VERSION ""

NS_ :

BS_:

BU_: VCU_LE CHUD_LE VKM_LE RCRM_LE VPM_LE EDI_LE V2V_LE TCP_LE CSM_LE UHP_Low_LE TouchPad_LE RSE_LE RSC_LE RSA_LE PDIM_LE OTIM_LE ICS_LE LVMPC_LE LVMNav_LE DVB_T_LE ONSTAR_LE HUD_LE IPC_LE RadioHead_LE CHM_LE Dummy_LE CGM_LE AMP_LE

BO_ 2155102208 Driver_Seat_Massage_Priority_LE: 8 CGM_LE
 SG_ DSMP_UnsdRsrvd : 56|1@0+ (1,0) [0|1] ""  VCU_LE,CSM_LE,RadioHead_LE
 SG_ DSMP_MaxDispVal : 59|3@0+ (1,0) [0|7] ""  VCU_LE,CSM_LE,RadioHead_LE
 SG_ DSMP_Type15 : 63|4@0+ (1,0) [0|15] ""  VCU_LE,CSM_LE,RadioHead_LE
 SG_ DSMP_Type14 : 51|4@0+ (1,0) [0|15] ""  VCU_LE,CSM_LE,RadioHead_LE
 SG_ DSMP_Type13 : 55|4@0+ (1,0) [0|15] ""  VCU_LE,CSM_LE,RadioHead_LE
 SG_ DSMP_Type12 : 43|4@0+ (1,0) [0|15] ""  VCU_LE,CSM_LE,RadioHead_LE
 SG_ DSMP_Type11 : 47|4@0+ (1,0) [0|15] ""  VCU_LE,CSM_LE,RadioHead_LE
 SG_ DSMP_Type10 : 35|4@0+ (1,0) [0|15] ""  VCU_LE,CSM_LE,RadioHead_LE
 SG_ DSMP_Type9 : 39|4@0+ (1,0) [0|15] ""  VCU_LE,CSM_LE,RadioHead_LE
 SG_ DSMP_Type8 : 27|4@0+ (1,0) [0|15] ""  VCU_LE,CSM_LE,RadioHead_LE
 SG_ DSMP_Type7 : 31|4@0+ (1,0) [0|15] ""  VCU_LE,CSM_LE,RadioHead_LE
 SG_ DSMP_Type6 : 19|4@0+ (1,0) [0|15] ""  VCU_LE,CSM_LE,RadioHead_LE
 SG_ DSMP_Type5 : 23|4@0+ (1,0) [0|15] ""  VCU_LE,CSM_LE,RadioHead_LE
 SG_ DSMP_Type4 : 11|4@0+ (1,0) [0|15] ""  VCU_LE,CSM_LE,RadioHead_LE
 SG_ DSMP_Type3 : 15|4@0+ (1,0) [0|15] ""  VCU_LE,CSM_LE,RadioHead_LE
 SG_ DSMP_Type2 : 3|4@0+ (1,0) [0|15] ""  VCU_LE,CSM_LE,RadioHead_LE
 SG_ DSMP_Type1 : 7|4@0+ (1,0) [0|15] ""  VCU_LE,CSM_LE,RadioHead_LE

BO_ 2155085824 Driver_Seat_Control_Disp_Stat_LE: 8 CGM_LE
 SG_ StrgColUpDwnPos : 63|8@0+ (1,0) [0|255] ""  Dummy_LE
 SG_ CPMAPINFO4 : 5|1@0+ (1,0) [0|1] ""  Dummy_LE
 SG_ StrgColInOutPos : 55|8@0+ (1,0) [0|255] ""  Dummy_LE
 SG_ StrgColCommsFlt : 7|2@0+ (1,0) [0|3] ""  Dummy_LE
 SG_ DSCDS_UnsdRsrvd : 42|3@0+ (1,0) [0|7] ""  VCU_LE,CSM_LE,RadioHead_LE
 SG_ DSCDS_DispReq : 43|1@0+ (1,0) [0|1] ""  VCU_LE,CSM_LE,RadioHead_LE
 SG_ DSCDS_DispSz : 45|2@0+ (1,0) [0|3] ""  VCU_LE,CSM_LE,RadioHead_LE
 SG_ DSCDS_CshLgAdjFdRr : 47|2@0+ (1,0) [0|3] ""  VCU_LE,CSM_LE,RadioHead_LE
 SG_ DSCDS_BkCshBlstInOt : 34|3@0+ (1,0) [0|7] ""  VCU_LE,CSM_LE,RadioHead_LE
 SG_ DSCDS_CshBlstrInOut : 36|2@0+ (1,0) [0|3] ""  VCU_LE,CSM_LE,RadioHead_LE
 SG_ DSCDS_BkBlstrInOut : 38|2@0+ (1,0) [0|3] ""  VCU_LE,CSM_LE,RadioHead_LE
 SG_ DSCDS_LmbrUDnFdRr : 25|3@0+ (1,0) [0|7] ""  VCU_LE,CSM_LE,RadioHead_LE
 SG_ DSCDS_LmbrFwdRr : 27|2@0+ (1,0) [0|3] ""  VCU_LE,CSM_LE,RadioHead_LE
 SG_ DSCDS_LmbrUpDwn : 29|2@0+ (1,0) [0|3] ""  VCU_LE,CSM_LE,RadioHead_LE
 SG_ DSCDS_UprShldrFdRr : 31|2@0+ (1,0) [0|3] ""  VCU_LE,CSM_LE,RadioHead_LE
 SG_ DSCDS_HdrstTltFwdRr : 17|2@0+ (1,0) [0|3] ""  VCU_LE,CSM_LE,RadioHead_LE
 SG_ DSCDS_HdrstWngInOt : 19|2@0+ (1,0) [0|3] ""  VCU_LE,CSM_LE,RadioHead_LE
 SG_ DSCDS_HdrstUDnFdRr : 22|3@0+ (1,0) [0|7] ""  VCU_LE,CSM_LE,RadioHead_LE
 SG_ DSCDS_HdrstFwdRrwd : 8|2@0+ (1,0) [0|3] ""  VCU_LE,CSM_LE,RadioHead_LE
 SG_ DSCDS_HdrstUpDn : 10|2@0+ (1,0) [0|3] ""  VCU_LE,CSM_LE,RadioHead_LE
 SG_ DSCDS_MassgIntsty : 13|3@0+ (1,0) [0|7] ""  VCU_LE,CSM_LE,RadioHead_LE
 SG_ DSCDS_MassgTyp : 1|4@0+ (1,0) [0|15] ""  VCU_LE,CSM_LE,RadioHead_LE
 SG_ DSCDS_Massg : 3|2@0+ (1,0) [0|3] ""  VCU_LE,CSM_LE,RadioHead_LE

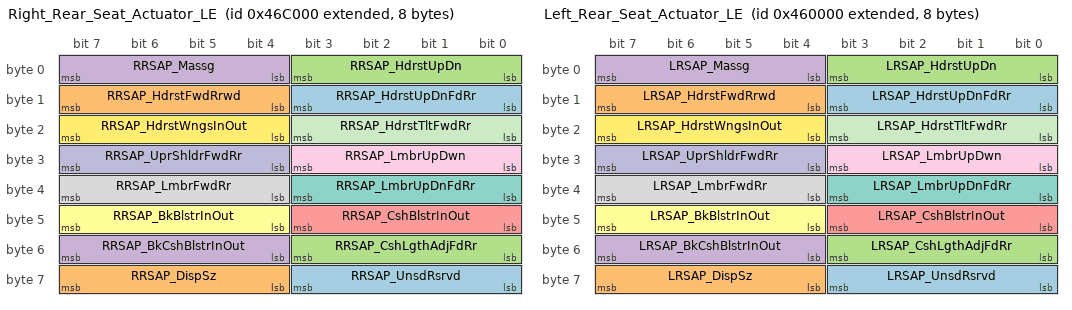
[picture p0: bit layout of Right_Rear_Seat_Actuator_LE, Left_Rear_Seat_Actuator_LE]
BO_ 2152120320 Right_Rear_Seat_Actuator_LE: 8 CGM_LE
 SG_ RRSAP_UnsdRsrvd : 59|4@0+ (1,0) [0|15] ""  RSE_LE,VCU_LE,CSM_LE,RadioHead_LE
 SG_ RRSAP_DispSz : 63|4@0+ (1,0) [0|15] ""  RSE_LE,VCU_LE,CSM_LE,RadioHead_LE
 SG_ RRSAP_CshLgthAdjFdRr : 51|4@0+ (1,0) [0|15] ""  RSE_LE,VCU_LE,CSM_LE,RadioHead_LE
 SG_ RRSAP_BkCshBlstrInOut : 55|4@0+ (1,0) [0|15] ""  RSE_LE,VCU_LE,CSM_LE,RadioHead_LE
 SG_ RRSAP_CshBlstrInOut : 43|4@0+ (1,0) [0|15] ""  RSE_LE,VCU_LE,CSM_LE,RadioHead_LE
 SG_ RRSAP_BkBlstrInOut : 47|4@0+ (1,0) [0|15] ""  RSE_LE,VCU_LE,CSM_LE,RadioHead_LE
 SG_ RRSAP_LmbrUpDnFdRr : 35|4@0+ (1,0) [0|15] ""  RSE_LE,VCU_LE,CSM_LE,RadioHead_LE
 SG_ RRSAP_LmbrFwdRr : 39|4@0+ (1,0) [0|15] ""  RSE_LE,VCU_LE,CSM_LE,RadioHead_LE
 SG_ RRSAP_LmbrUpDwn : 27|4@0+ (1,0) [0|15] ""  RSE_LE,VCU_LE,CSM_LE,RadioHead_LE
 SG_ RRSAP_UprShldrFwdRr : 31|4@0+ (1,0) [0|15] ""  RSE_LE,VCU_LE,CSM_LE,RadioHead_LE
 SG_ RRSAP_HdrstTltFwdRr : 19|4@0+ (1,0) [0|15] ""  RSE_LE,VCU_LE,CSM_LE,RadioHead_LE
 SG_ RRSAP_HdrstWngsInOut : 23|4@0+ (1,0) [0|15] ""  RSE_LE,VCU_LE,CSM_LE,RadioHead_LE
 SG_ RRSAP_HdrstUpDnFdRr : 11|4@0+ (1,0) [0|15] ""  RSE_LE,VCU_LE,CSM_LE,RadioHead_LE
 SG_ RRSAP_HdrstFwdRrwd : 15|4@0+ (1,0) [0|15] ""  RSE_LE,VCU_LE,CSM_LE,RadioHead_LE
 SG_ RRSAP_HdrstUpDn : 3|4@0+ (1,0) [0|15] ""  RSE_LE,VCU_LE,CSM_LE,RadioHead_LE
 SG_ RRSAP_Massg : 7|4@0+ (1,0) [0|15] ""  RSE_LE,VCU_LE,CSM_LE,RadioHead_LE

BO_ 2152103936 Left_Rear_Seat_Display_Status_LE: 6 CGM_LE
 SG_ LRSCDS_UnsdRsrvd : 42|3@0+ (1,0) [0|7] ""  RSE_LE,VCU_LE,CSM_LE,RadioHead_LE
 SG_ LRSCDS_DispReq : 43|1@0+ (1,0) [0|1] ""  RSE_LE,VCU_LE,CSM_LE,RadioHead_LE
 SG_ LRSCDS_DispSz : 45|2@0+ (1,0) [0|3] ""  RSE_LE,VCU_LE,CSM_LE,RadioHead_LE
 SG_ LRSCDS_CshLgAdjFdRr : 47|2@0+ (1,0) [0|3] ""  RSE_LE,VCU_LE,CSM_LE,RadioHead_LE
 SG_ LRSCDS_BkCshBlstInOt : 34|3@0+ (1,0) [0|7] ""  RSE_LE,VCU_LE,CSM_LE,RadioHead_LE
 SG_ LRSCDS_CshBlstrInOut : 36|2@0+ (1,0) [0|3] ""  RSE_LE,VCU_LE,CSM_LE,RadioHead_LE
 SG_ LRSCDS_BkBlstrInOut : 38|2@0+ (1,0) [0|3] ""  RSE_LE,VCU_LE,CSM_LE,RadioHead_LE
 SG_ LRSCDS_LmbrUDnFdRr : 25|3@0+ (1,0) [0|7] ""  RSE_LE,VCU_LE,CSM_LE,RadioHead_LE
 SG_ LRSCDS_LmbrFwdRr : 27|2@0+ (1,0) [0|3] ""  RSE_LE,VCU_LE,CSM_LE,RadioHead_LE
 SG_ LRSCDS_LmbrUpDwn : 29|2@0+ (1,0) [0|3] ""  RSE_LE,VCU_LE,CSM_LE,RadioHead_LE
 SG_ LRSCDS_UprShldrFdRr : 31|2@0+ (1,0) [0|3] ""  RSE_LE,VCU_LE,CSM_LE,RadioHead_LE
 SG_ LRSCDS_HdrstTltFwdRr : 17|2@0+ (1,0) [0|3] ""  RSE_LE,VCU_LE,CSM_LE,RadioHead_LE
 SG_ LRSCDS_HdrstWngInOt : 19|2@0+ (1,0) [0|3] ""  RSE_LE,VCU_LE,CSM_LE,RadioHead_LE
 SG_ LRSCDS_HdrstFdRrUDn : 22|3@0+ (1,0) [0|7] ""  RSE_LE,VCU_LE,CSM_LE,RadioHead_LE
 SG_ LRSCDS_HdrstFwdRrwd : 8|2@0+ (1,0) [0|3] ""  RSE_LE,VCU_LE,CSM_LE,RadioHead_LE
 SG_ LRSCDS_HdrstUpDn : 10|2@0+ (1,0) [0|3] ""  RSE_LE,VCU_LE,CSM_LE,RadioHead_LE
 SG_ LRSCDS_MassgIntsty : 13|3@0+ (1,0) [0|7] ""  RSE_LE,VCU_LE,CSM_LE,RadioHead_LE
 SG_ LRSCDS_MassgTyp : 1|4@0+ (1,0) [0|15] ""  RSE_LE,VCU_LE,CSM_LE,RadioHead_LE
 SG_ LRSCDS_Massg : 3|2@0+ (1,0) [0|3] ""  RSE_LE,VCU_LE,CSM_LE,RadioHead_LE

BO_ 2152087552 Left_Rear_Seat_Massage_LE: 8 CGM_LE
 SG_ LRSMP_UnsdRsrvd : 56|1@0+ (1,0) [0|1] ""  RSE_LE,VCU_LE,CSM_LE,RadioHead_LE
 SG_ LRSMP_MaxDispVal : 59|3@0+ (1,0) [0|7] ""  RSE_LE,VCU_LE,CSM_LE,RadioHead_LE
 SG_ LRSMP_Type15 : 63|4@0+ (1,0) [0|15] ""  RSE_LE,VCU_LE,CSM_LE,RadioHead_LE
 SG_ LRSMP_Type14 : 51|4@0+ (1,0) [0|15] ""  RSE_LE,VCU_LE,CSM_LE,RadioHead_LE
 SG_ LRSMP_Type13 : 55|4@0+ (1,0) [0|15] ""  RSE_LE,VCU_LE,CSM_LE,RadioHead_LE
 SG_ LRSMP_Type12 : 43|4@0+ (1,0) [0|15] ""  RSE_LE,VCU_LE,CSM_LE,RadioHead_LE
 SG_ LRSMP_Type11 : 47|4@0+ (1,0) [0|15] ""  RSE_LE,VCU_LE,CSM_LE,RadioHead_LE
 SG_ LRSMP_Type10 : 35|4@0+ (1,0) [0|15] ""  RSE_LE,VCU_LE,CSM_LE,RadioHead_LE
 SG_ LRSMP_Type9 : 39|4@0+ (1,0) [0|15] ""  RSE_LE,VCU_LE,CSM_LE,RadioHead_LE
 SG_ LRSMP_Type8 : 27|4@0+ (1,0) [0|15] ""  RSE_LE,VCU_LE,CSM_LE,RadioHead_LE
 SG_ LRSMP_Type7 : 31|4@0+ (1,0) [0|15] ""  RSE_LE,VCU_LE,CSM_LE,RadioHead_LE
 SG_ LRSMP_Type6 : 19|4@0+ (1,0) [0|15] ""  RSE_LE,VCU_LE,CSM_LE,RadioHead_LE
 SG_ LRSMP_Type5 : 23|4@0+ (1,0) [0|15] ""  RSE_LE,VCU_LE,CSM_LE,RadioHead_LE
 SG_ LRSMP_Type4 : 11|4@0+ (1,0) [0|15] ""  RSE_LE,VCU_LE,CSM_LE,RadioHead_LE
 SG_ LRSMP_Type3 : 15|4@0+ (1,0) [0|15] ""  RSE_LE,VCU_LE,CSM_LE,RadioHead_LE
 SG_ LRSMP_Type2 : 3|4@0+ (1,0) [0|15] ""  RSE_LE,VCU_LE,CSM_LE,RadioHead_LE
 SG_ LRSMP_Type1 : 7|4@0+ (1,0) [0|15] ""  RSE_LE,VCU_LE,CSM_LE,RadioHead_LE

BO_ 2152071168 Left_Rear_Seat_Actuator_LE: 8 CGM_LE
 SG_ LRSAP_UnsdRsrvd : 59|4@0+ (1,0) [0|15] ""  RSE_LE,VCU_LE,CSM_LE,RadioHead_LE
 SG_ LRSAP_DispSz : 63|4@0+ (1,0) [0|15] ""  RSE_LE,VCU_LE,CSM_LE,RadioHead_LE
 SG_ LRSAP_CshLgthAdjFdRr : 51|4@0+ (1,0) [0|15] ""  RSE_LE,VCU_LE,CSM_LE,RadioHead_LE
 SG_ LRSAP_BkCshBlstrInOut : 55|4@0+ (1,0) [0|15] ""  RSE_LE,VCU_LE,CSM_LE,RadioHead_LE
 SG_ LRSAP_CshBlstrInOut : 43|4@0+ (1,0) [0|15] ""  RSE_LE,VCU_LE,CSM_LE,RadioHead_LE
 SG_ LRSAP_BkBlstrInOut : 47|4@0+ (1,0) [0|15] ""  RSE_LE,VCU_LE,CSM_LE,RadioHead_LE
 SG_ LRSAP_LmbrUpDnFdRr : 35|4@0+ (1,0) [0|15] ""  RSE_LE,VCU_LE,CSM_LE,RadioHead_LE
 SG_ LRSAP_LmbrFwdRr : 39|4@0+ (1,0) [0|15] ""  RSE_LE,VCU_LE,CSM_LE,RadioHead_LE
 SG_ LRSAP_LmbrUpDwn : 27|4@0+ (1,0) [0|15] ""  RSE_LE,VCU_LE,CSM_LE,RadioHead_LE
 SG_ LRSAP_UprShldrFwdRr : 31|4@0+ (1,0) [0|15] ""  RSE_LE,VCU_LE,CSM_LE,RadioHead_LE
 SG_ LRSAP_HdrstTltFwdRr : 19|4@0+ (1,0) [0|15] ""  RSE_LE,VCU_LE,CSM_LE,RadioHead_LE
 SG_ LRSAP_HdrstWngsInOut : 23|4@0+ (1,0) [0|15] ""  RSE_LE,VCU_LE,CSM_LE,RadioHead_LE
 SG_ LRSAP_HdrstUpDnFdRr : 11|4@0+ (1,0) [0|15] ""  RSE_LE,VCU_LE,CSM_LE,RadioHead_LE
 SG_ LRSAP_HdrstFwdRrwd : 15|4@0+ (1,0) [0|15] ""  RSE_LE,VCU_LE,CSM_LE,RadioHead_LE
 SG_ LRSAP_HdrstUpDn : 3|4@0+ (1,0) [0|15] ""  RSE_LE,VCU_LE,CSM_LE,RadioHead_LE
 SG_ LRSAP_Massg : 7|4@0+ (1,0) [0|15] ""  RSE_LE,VCU_LE,CSM_LE,RadioHead_LE

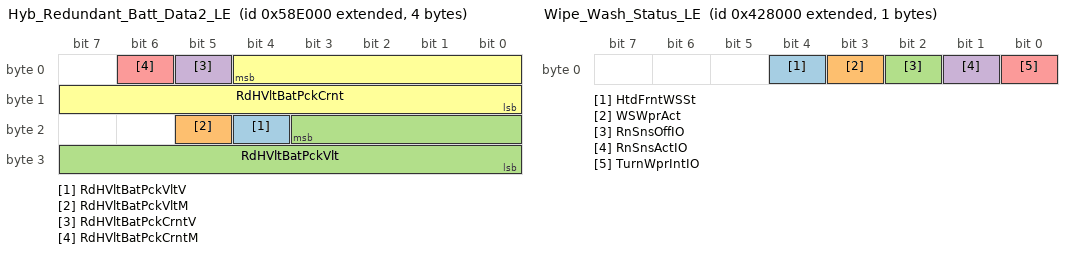
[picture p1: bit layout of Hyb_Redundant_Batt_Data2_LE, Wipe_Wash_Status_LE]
BO_ 2153308160 Hyb_Redundant_Batt_Data2_LE: 4 CGM_LE
 SG_ RdHVltBatPckVltV : 20|1@0+ (1,0) [0|1] ""  CSM_LE,RadioHead_LE,VCU_LE,IPC_LE
 SG_ RdHVltBatPckVltM : 21|1@0+ (1,0) [0|1] ""  CSM_LE,RadioHead_LE,VCU_LE,IPC_LE
 SG_ RdHVltBatPckVlt : 19|12@0+ (0.125,0) [0|511.875] "V"  CSM_LE,RadioHead_LE,VCU_LE,IPC_LE
 SG_ RdHVltBatPckCrntV : 5|1@0+ (1,0) [0|1] ""  CSM_LE,RadioHead_LE,VCU_LE,IPC_LE
 SG_ RdHVltBatPckCrntM : 6|1@0+ (1,0) [0|1] ""  CSM_LE,RadioHead_LE,VCU_LE,IPC_LE
 SG_ RdHVltBatPckCrnt : 4|13@0- (0.15,0) [-614.4|614.25] "A"  CSM_LE,RadioHead_LE,VCU_LE,IPC_LE

BO_ 2149924864 Drv_Pref_Mode_Switch_Status_LE: 8 CGM_LE
 SG_ PTOMobModTrnsInGrIO : 15|1@0+ (1,0) [0|1] ""  VCU_LE,IPC_LE
 SG_ FwdClnMtgnBrkReqAct : 7|1@0+ (1,0) [0|1] ""  Dummy_LE
 SG_ TireRRLowTracIO : 54|1@0+ (1,0) [0|1] ""  CSM_LE,VCU_LE,IPC_LE
 SG_ TireRFLowTracIO : 53|1@0+ (1,0) [0|1] ""  CSM_LE,VCU_LE,IPC_LE
 SG_ TireLRLowTracIO : 52|1@0+ (1,0) [0|1] ""  CSM_LE,VCU_LE,IPC_LE
 SG_ TireLFLowTracIO : 51|1@0+ (1,0) [0|1] ""  CSM_LE,VCU_LE,IPC_LE
 SG_ HilRlbkCtrlActIO : 6|1@0+ (1,0) [0|1] ""  VCU_LE,IPC_LE
 SG_ DsplyPerfMdRq : 50|3@0+ (1,0) [0|7] ""  VCU_LE,IPC_LE
 SG_ DrvSelMd8Stat : 37|1@0+ (1,0) [0|1] ""  CSM_LE,RadioHead_LE,VCU_LE,IPC_LE
 SG_ DrvSelMd8ReqDnd : 38|1@0+ (1,0) [0|1] ""  CSM_LE,RadioHead_LE,VCU_LE,IPC_LE
 SG_ DrvSelMd7Stat : 35|1@0+ (1,0) [0|1] ""  CSM_LE,RadioHead_LE,VCU_LE,IPC_LE
 SG_ DrvSelMd7ReqDnd : 36|1@0+ (1,0) [0|1] ""  CSM_LE,RadioHead_LE,VCU_LE,IPC_LE
 SG_ DrvSelMd6Stat : 13|1@0+ (1,0) [0|1] ""  CSM_LE,RadioHead_LE,VCU_LE,IPC_LE
 SG_ DrvSelMd6ReqDnd : 14|1@0+ (1,0) [0|1] ""  CSM_LE,RadioHead_LE,VCU_LE,IPC_LE
 SG_ DrvSelMd5Stat : 11|1@0+ (1,0) [0|1] ""  CSM_LE,RadioHead_LE,VCU_LE,IPC_LE
 SG_ DrvSelMd5ReqDnd : 12|1@0+ (1,0) [0|1] ""  CSM_LE,RadioHead_LE,VCU_LE,IPC_LE
 SG_ DrvSelMd4Stat : 9|1@0+ (1,0) [0|1] ""  CSM_LE,RadioHead_LE,VCU_LE,IPC_LE
 SG_ DrvSelMd4ReqDnd : 10|1@0+ (1,0) [0|1] ""  CSM_LE,RadioHead_LE,VCU_LE,IPC_LE
 SG_ EDADS_RcmndtFwdGr : 43|4@0+ (1,0) [0|15] ""  CSM_LE,VCU_LE,IPC_LE
 SG_ EDADS_CrntFwdMsdG : 47|4@0+ (1,0) [0|15] ""  CSM_LE,VCU_LE,IPC_LE
 SG_ EDADS_ShftIndStat : 33|2@0+ (1,0) [0|3] ""  CSM_LE,VCU_LE,IPC_LE
 SG_ EDADS_EcoDrvShftIO : 34|1@0+ (1,0) [0|1] ""  CSM_LE,VCU_LE,IPC_LE
 SG_ DSMSS_DrvSelMd0Pn : 24|1@0+ (1,0) [0|1] ""  CSM_LE,RadioHead_LE,VCU_LE,IPC_LE
 SG_ DSMSS_DrvSelMd8Pn : 25|1@0+ (1,0) [0|1] ""  CSM_LE,RadioHead_LE,VCU_LE,IPC_LE
 SG_ DSMSS_DrvSelMd7Pn : 26|1@0+ (1,0) [0|1] ""  CSM_LE,RadioHead_LE,VCU_LE,IPC_LE
 SG_ DSMSS_DrvSelMd6Pn : 27|1@0+ (1,0) [0|1] ""  CSM_LE,RadioHead_LE,VCU_LE,IPC_LE
 SG_ DSMSS_DrvSelMd5Pn : 28|1@0+ (1,0) [0|1] ""  CSM_LE,RadioHead_LE,VCU_LE,IPC_LE
 SG_ DSMSS_DrvSelMd4Pn : 29|1@0+ (1,0) [0|1] ""  CSM_LE,RadioHead_LE,VCU_LE,IPC_LE
 SG_ DSMSS_DrvSelMd3Pn : 30|1@0+ (1,0) [0|1] ""  CSM_LE,RadioHead_LE,VCU_LE,IPC_LE
 SG_ DSMSS_DrvSelMd2Pn : 31|1@0+ (1,0) [0|1] ""  CSM_LE,RadioHead_LE,VCU_LE,IPC_LE
 SG_ DSMSS_DrvSelMd1Pn : 16|1@0+ (1,0) [0|1] ""  CSM_LE,RadioHead_LE,VCU_LE,IPC_LE
 SG_ DSMSS_DrvSelMd8Un : 17|1@0+ (1,0) [0|1] ""  CSM_LE,RadioHead_LE,VCU_LE,IPC_LE
 SG_ DSMSS_DrvSelMd7Un : 18|1@0+ (1,0) [0|1] ""  CSM_LE,RadioHead_LE,VCU_LE,IPC_LE
 SG_ DSMSS_DrvSelMd6Un : 19|1@0+ (1,0) [0|1] ""  CSM_LE,RadioHead_LE,VCU_LE,IPC_LE
 SG_ DSMSS_DrvSelMd5Un : 20|1@0+ (1,0) [0|1] ""  CSM_LE,RadioHead_LE,VCU_LE,IPC_LE
 SG_ DSMSS_DrvSelMd4Un : 21|1@0+ (1,0) [0|1] ""  CSM_LE,RadioHead_LE,VCU_LE,IPC_LE
 SG_ DSMSS_DrvSelMd3Un : 22|1@0+ (1,0) [0|1] ""  CSM_LE,RadioHead_LE,VCU_LE,IPC_LE
 SG_ DSMSS_DrvSelMd2Un : 23|1@0+ (1,0) [0|1] ""  CSM_LE,RadioHead_LE,VCU_LE,IPC_LE
 SG_ DSMSS_DrvSelMd1Un : 8|1@0+ (1,0) [0|1] ""  CSM_LE,RadioHead_LE,VCU_LE,IPC_LE
 SG_ DrvSelMd3Stat : 4|1@0+ (1,0) [0|1] ""  CSM_LE,RadioHead_LE,VCU_LE,IPC_LE
 SG_ DrvSelMd3ReqDnd : 5|1@0+ (1,0) [0|1] ""  CSM_LE,RadioHead_LE,VCU_LE,IPC_LE
 SG_ DrvSelMd2Stat : 2|1@0+ (1,0) [0|1] ""  CSM_LE,RadioHead_LE,VCU_LE,IPC_LE
 SG_ DrvSelMd2ReqDnd : 3|1@0+ (1,0) [0|1] ""  CSM_LE,RadioHead_LE,VCU_LE,IPC_LE
 SG_ DrvSelMd1Stat : 0|1@0+ (1,0) [0|1] ""  CSM_LE,RadioHead_LE,VCU_LE,IPC_LE
 SG_ DrvSelMd1ReqDnd : 1|1@0+ (1,0) [0|1] ""  CSM_LE,RadioHead_LE,VCU_LE,IPC_LE
 SG_ a_12VBatSysUnstab : 55|1@0+ (1,0) [0|1] ""  VCU_LE,IPC_LE
 SG_ FstIdlMdAct : 39|1@0+ (1,0) [0|1] ""  VCU_LE,IPC_LE
 SG_ CPSCA_Resrv3Avail : 56|1@0+ (1,0) [0|1] ""  VCU_LE,CSM_LE,RadioHead_LE
 SG_ CPSCA_Resrv2Avail : 57|1@0+ (1,0) [0|1] ""  VCU_LE,CSM_LE,RadioHead_LE
 SG_ CPSCA_Resrv1Avail : 58|1@0+ (1,0) [0|1] ""  VCU_LE,CSM_LE,RadioHead_LE
 SG_ CPSCA_AlrtBrkStrAvail : 59|1@0+ (1,0) [0|1] ""  VCU_LE,CSM_LE,RadioHead_LE
 SG_ CPSCA_AlrtBrkAvail : 60|1@0+ (1,0) [0|1] ""  VCU_LE,CSM_LE,RadioHead_LE
 SG_ CPSCA_AlrtAvail : 61|1@0+ (1,0) [0|1] ""  VCU_LE,CSM_LE,RadioHead_LE
 SG_ CPSCA_OffAvail : 62|1@0+ (1,0) [0|1] ""  VCU_LE,CSM_LE,RadioHead_LE

BO_ 2151153664 Rear_Window_Defog_Status_LE: 1 CGM_LE
 SG_ RrWndDfgOn : 0|1@0+ (1,0) [0|1] ""  Dummy_LE,IPC_LE,VCU_LE,CSM_LE,RadioHead_LE

BO_ 2151841792 Wipe_Wash_Status_LE: 1 CGM_LE
 SG_ HtdFrntWSSt : 4|1@0+ (1,0) [0|1] ""  VCU_LE,IPC_LE
 SG_ WSWprAct : 3|1@0+ (1,0) [0|1] ""  V2V_LE,CSM_LE,VCU_LE,RadioHead_LE
 SG_ RnSnsOffIO : 2|1@0+ (1,0) [0|1] ""  CSM_LE,IPC_LE,VCU_LE,RadioHead_LE
 SG_ RnSnsActIO : 1|1@0+ (1,0) [0|1] ""  CSM_LE,IPC_LE,VCU_LE,RadioHead_LE
 SG_ TurnWprIntIO : 0|1@0+ (1,0) [0|1] ""  CSM_LE,IPC_LE,VCU_LE,RadioHead_LE

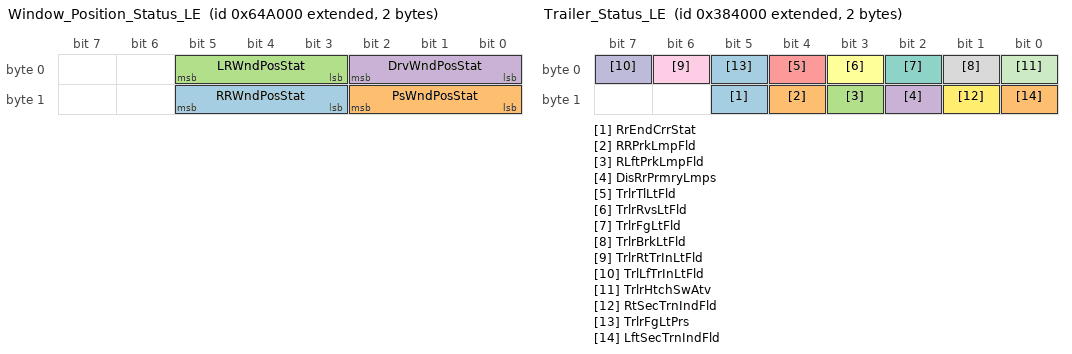
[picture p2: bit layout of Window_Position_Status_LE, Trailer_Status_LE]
BO_ 2154078208 Window_Position_Status_LE: 2 CGM_LE
 SG_ RRWndPosStat : 13|3@0+ (1,0) [0|7] ""  CSM_LE,VCU_LE,RadioHead_LE
 SG_ PsWndPosStat : 10|3@0+ (1,0) [0|7] ""  CSM_LE,VCU_LE,RadioHead_LE
 SG_ LRWndPosStat : 5|3@0+ (1,0) [0|7] ""  CSM_LE,VCU_LE,RadioHead_LE
 SG_ DrvWndPosStat : 2|3@0+ (1,0) [0|7] ""  CSM_LE,VCU_LE,RadioHead_LE

BO_ 2151399424 Wash_Level_LE: 1 IPC_LE
 SG_ WshFldLw : 0|1@0+ (1,0) [0|1] ""  CSM_LE,TCP_LE,VCU_LE,RadioHead_LE,ONSTAR_LE,CGM_LE
 SG_ VhlFlRngLwIO : 1|1@0+ (1,0) [0|1] ""  CGM_LE,CSM_LE

BO_ 2151170048 Trailer_Status_LE: 2 CGM_LE
 SG_ RrEndCrrStat : 13|1@0+ (1,0) [0|1] ""  CSM_LE,VCU_LE,RadioHead_LE
 SG_ RRPrkLmpFld : 12|1@0+ (1,0) [0|1] ""  CSM_LE,RadioHead_LE,VCU_LE,IPC_LE
 SG_ RLftPrkLmpFld : 11|1@0+ (1,0) [0|1] ""  CSM_LE,RadioHead_LE,VCU_LE,IPC_LE
 SG_ DisRrPrmryLmps : 10|1@0+ (1,0) [0|1] ""  CSM_LE,VCU_LE,RadioHead_LE
 SG_ TrlrTlLtFld : 4|1@0+ (1,0) [0|1] ""  CSM_LE,RadioHead_LE,VCU_LE,IPC_LE
 SG_ TrlrRvsLtFld : 3|1@0+ (1,0) [0|1] ""  CSM_LE,RadioHead_LE,VCU_LE,IPC_LE
 SG_ TrlrFgLtFld : 2|1@0+ (1,0) [0|1] ""  CSM_LE,RadioHead_LE,VCU_LE,IPC_LE
 SG_ TrlrBrkLtFld : 1|1@0+ (1,0) [0|1] ""  CSM_LE,RadioHead_LE,VCU_LE,IPC_LE
 SG_ TrlrRtTrInLtFld : 6|1@0+ (1,0) [0|1] ""  CSM_LE,RadioHead_LE,VCU_LE,IPC_LE
 SG_ TrlLfTrInLtFld : 7|1@0+ (1,0) [0|1] ""  CSM_LE,RadioHead_LE,VCU_LE,IPC_LE
 SG_ TrlrHtchSwAtv : 0|1@0+ (1,0) [0|1] ""  CSM_LE,VCU_LE,RadioHead_LE
 SG_ RtSecTrnIndFld : 9|1@0+ (1,0) [0|1] ""  CSM_LE,VCU_LE,RadioHead_LE
 SG_ TrlrFgLtPrs : 5|1@0+ (1,0) [0|1] ""  CSM_LE,VCU_LE,RadioHead_LE
 SG_ LftSecTrnIndFld : 8|1@0+ (1,0) [0|1] ""  CSM_LE,VCU_LE,RadioHead_LE

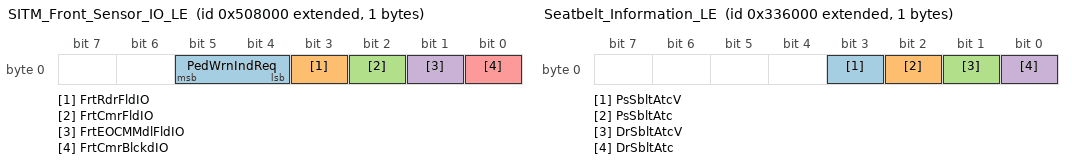
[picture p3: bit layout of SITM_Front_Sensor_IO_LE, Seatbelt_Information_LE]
BO_ 2152759296 SITM_Front_Sensor_IO_LE: 1 CGM_LE
 SG_ PedWrnIndReq : 5|2@0+ (1,0) [0|3] ""  CSM_LE,RadioHead_LE,VCU_LE,IPC_LE
 SG_ FrtRdrFldIO : 3|1@0+ (1,0) [0|1] ""  CSM_LE,IPC_LE,VCU_LE,RadioHead_LE
 SG_ FrtCmrFldIO : 2|1@0+ (1,0) [0|1] ""  CSM_LE,IPC_LE,VCU_LE,RadioHead_LE
 SG_ FrtEOCMMdlFldIO : 1|1@0+ (1,0) [0|1] ""  CSM_LE,IPC_LE,VCU_LE,RadioHead_LE
 SG_ FrtCmrBlckdIO : 0|1@0+ (1,0) [0|1] ""  CSM_LE,IPC_LE,VCU_LE,RadioHead_LE

BO_ 2150850560 Seatbelt_Information_LE: 1 CGM_LE
 SG_ PsSbltAtcV : 3|1@0+ (1,0) [0|1] ""  V2V_LE,CSM_LE,TCP_LE,ONSTAR_LE,VCU_LE,RadioHead_LE
 SG_ PsSbltAtc : 2|1@0+ (1,0) [0|1] ""  V2V_LE,CSM_LE,TCP_LE,ONSTAR_LE,VCU_LE,RadioHead_LE
 SG_ DrSbltAtcV : 1|1@0+ (1,0) [0|1] ""  V2V_LE,CSM_LE,TCP_LE,ONSTAR_LE,VCU_LE,RadioHead_LE
 SG_ DrSbltAtc : 0|1@0+ (1,0) [0|1] ""  V2V_LE,CSM_LE,TCP_LE,ONSTAR_LE,VCU_LE,RadioHead_LE

BO_ 2150604800 Right_Rear_Door_Status_LE: 1 CGM_LE
 SG_ RRDoorAjarSwAct : 0|1@0+ (1,0) [0|1] ""  VKM_LE,AMP_LE,V2V_LE,CSM_LE,VPM_LE,IPC_LE,VCU_LE,RadioHead_LE

BO_ 2151219200 Remote_Start_Status_LE: 1 CGM_LE
 SG_ RemStrtSt : 0|1@0+ (1,0) [0|1] ""  VKM_LE,TCP_LE,CSM_LE,ONSTAR_LE,VCU_LE,RadioHead_LE
 SG_ RmVehStrRq : 1|1@0+ (1,0) [0|1] ""  TCP_LE,ONSTAR_LE,CSM_LE,VCU_LE,RadioHead_LE

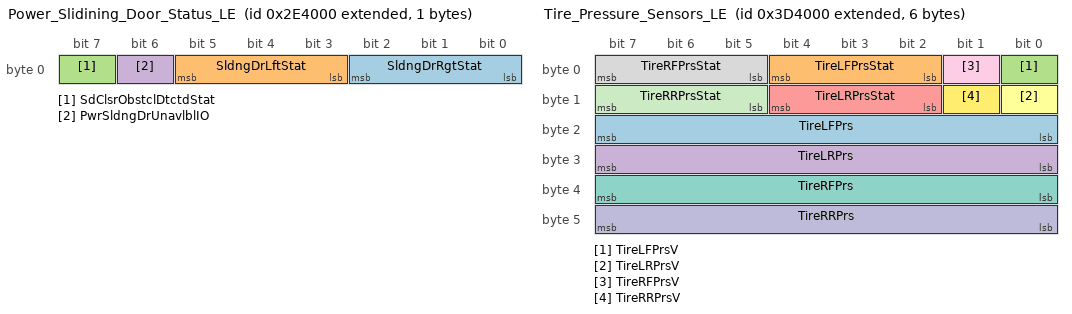
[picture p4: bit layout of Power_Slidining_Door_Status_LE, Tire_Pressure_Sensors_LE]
BO_ 2150514688 Power_Slidining_Door_Status_LE: 1 CGM_LE
 SG_ SldngDrRgtStat : 2|3@0+ (1,0) [0|7] ""  CSM_LE,VCU_LE,RadioHead_LE
 SG_ SldngDrLftStat : 5|3@0+ (1,0) [0|7] ""  CSM_LE,VCU_LE,RadioHead_LE
 SG_ SdClsrObstclDtctdStat : 7|1@0+ (1,0) [0|1] ""  CSM_LE,VCU_LE,RadioHead_LE
 SG_ PwrSldngDrUnavlblIO : 6|1@0+ (1,0) [0|1] ""  CSM_LE,RadioHead_LE,VCU_LE,IPC_LE

BO_ 2155208704 Power_Conv_Top_Info_LE: 3 CGM_LE
 SG_ SftTpPlsDnWrngIndOn : 22|1@0+ (1,0) [0|1] ""  VCU_LE,IPC_LE
 SG_ SftTpPlsDnSrtdIndOn : 21|1@0+ (1,0) [0|1] ""  VCU_LE,IPC_LE
 SG_ VltSwAtvIndOn : 14|1@0+ (1,0) [0|1] ""  CSM_LE,RadioHead_LE,VCU_LE,IPC_LE
 SG_ SftTpVltLwIO : 10|1@0+ (1,0) [0|1] ""  CSM_LE,RadioHead_LE,VCU_LE,IPC_LE
 SG_ SftTpVehOvSpdIndOn : 9|1@0+ (1,0) [0|1] ""  CSM_LE,RadioHead_LE,VCU_LE,IPC_LE
 SG_ SftTpTneuCvrIO : 8|1@0+ (1,0) [0|1] ""  CSM_LE,RadioHead_LE,VCU_LE,IPC_LE
 SG_ SftTpTmpLwIO : 7|1@0+ (1,0) [0|1] ""  CSM_LE,RadioHead_LE,VCU_LE,IPC_LE
 SG_ SftTpStrIO : 6|1@0+ (1,0) [0|1] ""  CSM_LE,RadioHead_LE,VCU_LE,IPC_LE
 SG_ SftTpRmCrgCrrIO : 5|1@0+ (1,0) [0|1] ""  CSM_LE,RadioHead_LE,VCU_LE,IPC_LE
 SG_ SftTpMnlLtchIndOn : 3|1@0+ (1,0) [0|1] ""  CSM_LE,RadioHead_LE,VCU_LE,IPC_LE
 SG_ SftTpMchnOvhtIO : 4|1@0+ (1,0) [0|1] ""  CSM_LE,RadioHead_LE,VCU_LE,IPC_LE
 SG_ SftTpLtcIO : 2|1@0+ (1,0) [0|1] ""  CSM_LE,RadioHead_LE,VCU_LE,IPC_LE
 SG_ SftTpFlrIO : 1|1@0+ (1,0) [0|1] ""  CSM_LE,RadioHead_LE,VCU_LE,IPC_LE
 SG_ SftTpAbvWrngSpdIndOn : 0|1@0+ (1,0) [0|1] ""  CSM_LE,RadioHead_LE,VCU_LE,IPC_LE
 SG_ FldngTpSt : 18|3@0+ (1,0) [0|7] ""  AMP_LE,CSM_LE,RadioHead_LE,VCU_LE,IPC_LE
 SG_ ClsTrnkLidIO : 12|1@0+ (1,0) [0|1] ""  V2V_LE,CSM_LE,RadioHead_LE,VCU_LE,IPC_LE
 SG_ CkSoftTpIO : 11|1@0+ (1,0) [0|1] ""  CSM_LE,RadioHead_LE,VCU_LE,IPC_LE
 SG_ SftTpTrnLmpsRqd : 15|1@0+ (1,0) [0|1] ""  CSM_LE,VCU_LE,RadioHead_LE
 SG_ FldngTpWndCmftRq : 20|2@0+ (1,0) [0|3] ""  CSM_LE,VCU_LE,RadioHead_LE
 SG_ FTUpdWndPsLmtEnbld : 13|1@0+ (1,0) [0|1] ""  CSM_LE,VCU_LE,RadioHead_LE

BO_ 2151530496 TPM_Display_Commands_LE: 6 CGM_LE
 SG_ HVBTBDCSRR1_DChMHSRq : 45|6@0+ (1,0) [0|63] "min"  Dummy_LE
 SG_ HVBTBDCSRR1_DChSnSRq : 47|2@0+ (1,0) [0|3] ""  Dummy_LE
 SG_ HVBTBDCSRR1_DChSlSRq : 35|4@0+ (1,0) [0|15] ""  Dummy_LE
 SG_ HVBTBDCSRR1_DChDStRq : 39|4@0+ (1,0) [0|15] ""  Dummy_LE
 SG_ HVBTBDCSRR1_DChHStRq : 28|5@0+ (1,0) [0|31] "hr"  Dummy_LE
 SG_ HVBatTmBsChgMdRqRmt1 : 31|3@0+ (1,0) [0|7] ""  Dummy_LE
 SG_ HVChgSyChgLvPfStRmt1 : 18|3@0+ (1,0) [0|7] ""  Dummy_LE
 SG_ StTODChrgTmpOvrdRmt1 : 20|2@0+ (1,0) [0|3] ""  Dummy_LE
 SG_ PrtyChrgRqRmt1 : 22|2@0+ (1,0) [0|3] ""  Dummy_LE
 SG_ OfBrdHVCVhCsChRqRmt1 : 23|1@0+ (1,0) [0|1] ""  Dummy_LE
 SG_ TireTrdTmpStat : 6|3@0+ (1,0) [0|7] ""  VCU_LE,IPC_LE
 SG_ TrPrsMntrTrLdStat : 3|2@0+ (1,0) [0|3] ""  CSM_LE,RadioHead_LE,VCU_LE,IPC_LE
 SG_ TrPrsMntrAtLocFld : 1|1@0+ (1,0) [0|1] ""  CSM_LE,RadioHead_LE,VCU_LE,IPC_LE
 SG_ TireLocatnWarnEn : 15|1@0+ (1,0) [0|1] ""  CSM_LE,RadioHead_LE,VCU_LE,IPC_LE
 SG_ WintTrRecIndOn : 12|1@0+ (1,0) [0|1] ""  CSM_LE,RadioHead_LE,VCU_LE,IPC_LE
 SG_ TrPrsMntrFld : 13|1@0+ (1,0) [0|1] ""  CSM_LE,RadioHead_LE,VCU_LE,IPC_LE
 SG_ TrRrAxlPresStat : 11|2@0+ (1,0) [0|3] ""  CSM_LE,RadioHead_LE,VCU_LE,IPC_LE
 SG_ TrFrntAxlPresStat : 9|2@0+ (1,0) [0|3] ""  CSM_LE,RadioHead_LE,VCU_LE,IPC_LE
 SG_ TPMTrLrnMdCmplt : 0|1@0+ (1,0) [0|1] ""  CSM_LE,RadioHead_LE,VCU_LE,IPC_LE

BO_ 2151497728 Tire_Pressure_Sensors_LE: 6 CGM_LE
 SG_ TireLFPrs : 23|8@0+ (4,0) [0|1020] "kPaG"  V2V_LE,VPM_LE,CSM_LE,TCP_LE,ONSTAR_LE,RadioHead_LE,VCU_LE,IPC_LE
 SG_ TireLFPrsStat : 4|3@0+ (1,0) [0|7] ""  VPM_LE,CSM_LE,TCP_LE,ONSTAR_LE,RadioHead_LE,VCU_LE,IPC_LE
 SG_ TireLFPrsV : 0|1@0+ (1,0) [0|1] ""  V2V_LE,VPM_LE,CSM_LE,TCP_LE,ONSTAR_LE,RadioHead_LE,VCU_LE,IPC_LE
 SG_ TireLRPrs : 31|8@0+ (4,0) [0|1020] "kPaG"  V2V_LE,VPM_LE,CSM_LE,TCP_LE,ONSTAR_LE,RadioHead_LE,VCU_LE,IPC_LE
 SG_ TireLRPrsStat : 12|3@0+ (1,0) [0|7] ""  CSM_LE,VPM_LE,TCP_LE,ONSTAR_LE,RadioHead_LE,VCU_LE,IPC_LE
 SG_ TireLRPrsV : 8|1@0+ (1,0) [0|1] ""  V2V_LE,CSM_LE,VPM_LE,TCP_LE,ONSTAR_LE,RadioHead_LE,VCU_LE,IPC_LE
 SG_ TireRFPrs : 39|8@0+ (4,0) [0|1020] "kPaG"  V2V_LE,CSM_LE,VPM_LE,TCP_LE,ONSTAR_LE,RadioHead_LE,VCU_LE,IPC_LE
 SG_ TireRFPrsStat : 7|3@0+ (1,0) [0|7] ""  CSM_LE,VPM_LE,TCP_LE,ONSTAR_LE,RadioHead_LE,VCU_LE,IPC_LE
 SG_ TireRFPrsV : 1|1@0+ (1,0) [0|1] ""  V2V_LE,CSM_LE,VPM_LE,TCP_LE,ONSTAR_LE,RadioHead_LE,VCU_LE,IPC_LE
 SG_ TireRRPrs : 47|8@0+ (4,0) [0|1020] "kPaG"  V2V_LE,CSM_LE,VPM_LE,TCP_LE,ONSTAR_LE,RadioHead_LE,VCU_LE,IPC_LE
 SG_ TireRRPrsStat : 15|3@0+ (1,0) [0|7] ""  CSM_LE,VPM_LE,TCP_LE,ONSTAR_LE,RadioHead_LE,VCU_LE,IPC_LE
 SG_ TireRRPrsV : 9|1@0+ (1,0) [0|1] ""  V2V_LE,CSM_LE,VPM_LE,TCP_LE,ONSTAR_LE,RadioHead_LE,VCU_LE,IPC_LE

BO_ 2150588416 Passenger_Door_Status_LE: 1 CGM_LE
 SG_ PDAjrSwAtv : 0|1@0+ (1,0) [0|1] ""  VKM_LE,AMP_LE,V2V_LE,CSM_LE,VPM_LE,RadioHead_LE,VCU_LE,IPC_LE

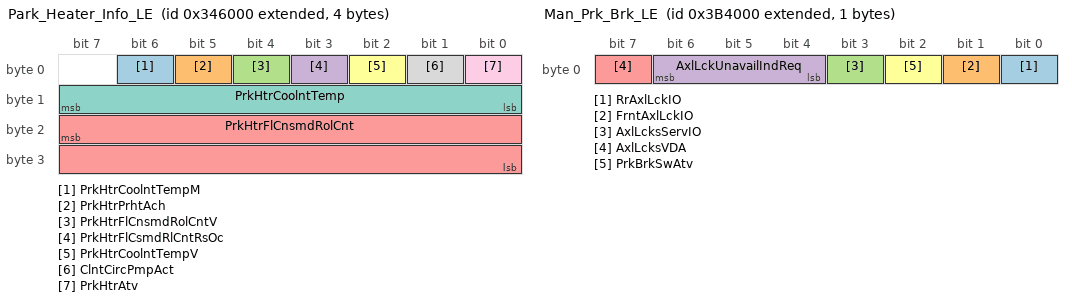
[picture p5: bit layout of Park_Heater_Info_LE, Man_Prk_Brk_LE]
BO_ 2150916096 Park_Heater_Info_LE: 4 CGM_LE
 SG_ PrkHtrCoolntTempM : 6|1@0+ (1,0) [0|1] ""  Dummy_LE
 SG_ PrkHtrPrhtAch : 5|1@0+ (1,0) [0|1] ""  CSM_LE,VCU_LE,RadioHead_LE
 SG_ PrkHtrFlCnsmdRolCntV : 4|1@0+ (1,0) [0|1] ""  CSM_LE,IPC_LE,VCU_LE,RadioHead_LE
 SG_ PrkHtrFlCsmdRlCntRsOc : 3|1@0+ (1,0) [0|1] ""  CSM_LE,IPC_LE,VCU_LE,RadioHead_LE
 SG_ PrkHtrFlCnsmdRolCnt : 23|16@0+ (3.05176E-006,0) [0|0.1999970916] "liters"  CSM_LE,IPC_LE,VCU_LE,RadioHead_LE
 SG_ PrkHtrCoolntTempV : 2|1@0+ (1,0) [0|1] ""  CSM_LE,VCU_LE,RadioHead_LE
 SG_ PrkHtrCoolntTemp : 15|8@0+ (1,-40) [-40|215] "deg C"  CSM_LE,VCU_LE,RadioHead_LE
 SG_ ClntCircPmpAct : 1|1@0+ (1,0) [0|1] ""  CSM_LE,VCU_LE,RadioHead_LE
 SG_ PrkHtrAtv : 0|1@0+ (1,0) [0|1] ""  CSM_LE,VCU_LE,RadioHead_LE

BO_ 2151366656 Man_Prk_Brk_LE: 1 CGM_LE
 SG_ RrAxlLckIO : 0|1@0+ (1,0) [0|1] ""  VCU_LE,IPC_LE
 SG_ FrntAxlLckIO : 1|1@0+ (1,0) [0|1] ""  VCU_LE,IPC_LE
 SG_ AxlLcksServIO : 3|1@0+ (1,0) [0|1] ""  VCU_LE,IPC_LE
 SG_ AxlLckUnavailIndReq : 6|3@0+ (1,0) [0|7] ""  VCU_LE,IPC_LE
 SG_ AxlLcksVDA : 7|1@0+ (1,0) [0|1] ""  VCU_LE,IPC_LE
 SG_ PrkBrkSwAtv : 2|1@0+ (1,0) [0|1] ""  V2V_LE,ONSTAR_LE,TCP_LE,CSM_LE,LVMNav_LE,RadioHead_LE,VCU_LE,IPC_LE

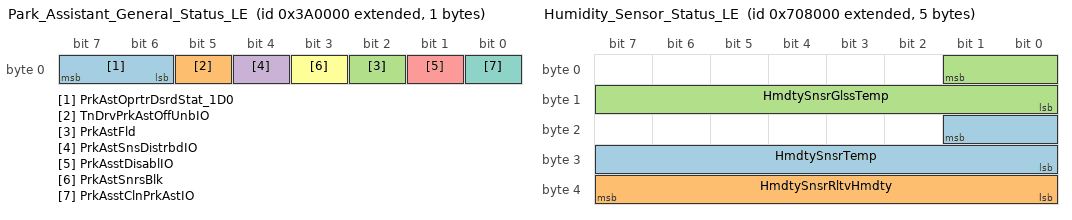
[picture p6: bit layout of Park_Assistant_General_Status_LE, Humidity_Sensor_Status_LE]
BO_ 2151284736 Park_Assistant_General_Status_LE: 1 CGM_LE
 SG_ PrkAstOprtrDsrdStat_1D0 : 7|2@0+ (1,0) [0|3] ""  Dummy_LE
 SG_ TnDrvPrkAstOffUnbIO : 5|1@0+ (1,0) [0|1] ""  VCU_LE,IPC_LE
 SG_ PrkAstFld : 2|1@0+ (1,0) [0|1] ""  CSM_LE,RadioHead_LE,VCU_LE,IPC_LE
 SG_ PrkAstSnsDistrbdIO : 4|1@0+ (1,0) [0|1] ""  CSM_LE,RadioHead_LE,VCU_LE,IPC_LE
 SG_ PrkAsstDisablIO : 1|1@0+ (1,0) [0|1] ""  CSM_LE,RadioHead_LE,VCU_LE,IPC_LE
 SG_ PrkAstSnrsBlk : 3|1@0+ (1,0) [0|1] ""  CSM_LE,RadioHead_LE,VCU_LE,IPC_LE
 SG_ PrkAsstClnPrkAstIO : 0|1@0+ (1,0) [0|1] ""  CSM_LE,RadioHead_LE,VCU_LE,IPC_LE

BO_ 2150596608 Left_Rear_Door_Status_LE: 1 CGM_LE
 SG_ RLDoorAjarSwAct : 0|1@0+ (1,0) [0|1] ""  VKM_LE,AMP_LE,V2V_LE,CSM_LE,VPM_LE,RadioHead_LE,VCU_LE,IPC_LE

BO_ 2155380736 HS_Indications_SuperSlow_LE: 6 CGM_LE
 SG_ ServFuelSysTrnsfrPmpIO : 42|1@0+ (1,0) [0|1] ""  VCU_LE,IPC_LE
 SG_ ACCmCltEngd : 41|1@0+ (1,0) [0|1] ""  Dummy_LE
 SG_ StrAsstRdcdLvl3IO : 23|1@0+ (1,0) [0|1] ""  VCU_LE,IPC_LE
 SG_ StrAsstRdcdLvl2IO : 16|1@0+ (1,0) [0|1] ""  VCU_LE,IPC_LE
 SG_ StrngAsstRdcdIO : 22|1@0+ (1,0) [0|1] ""  CSM_LE,RadioHead_LE,VCU_LE,IPC_LE
 SG_ ARSFlrIO : 40|1@0+ (1,0) [0|1] ""  CSM_LE,RadioHead_LE,VCU_LE,IPC_LE
 SG_ PwrPkFnSpd : 39|8@0+ (0.392157,0) [0|100.000035] "%"  CSM_LE,VCU_LE,RadioHead_LE
 SG_ PwrPckAirInTempFlt : 31|8@0+ (1,-40) [-40|215] "deg C"  CSM_LE,VCU_LE,RadioHead_LE
 SG_ PTExPrtclFltrWrn2IO : 18|1@0+ (1,0) [0|1] ""  CSM_LE,RadioHead_LE,VCU_LE,IPC_LE
 SG_ EngOilHotIO : 5|1@0+ (1,0) [0|1] ""  CSM_LE,RadioHead_LE,VCU_LE,IPC_LE
 SG_ RrLevVDA : 3|1@0+ (1,0) [0|1] ""  CSM_LE,RadioHead_LE,VCU_LE,IPC_LE
 SG_ EngWtrInFlIO : 12|1@0+ (1,0) [0|1] ""  CSM_LE,RadioHead_LE,VCU_LE,IPC_LE
 SG_ AdvFrntLghtSysIndRq : 21|3@0+ (1,0) [0|7] ""  CSM_LE,RadioHead_LE,VCU_LE,IPC_LE
 SG_ PTExPrtclFltrWrnIO : 6|1@0+ (1,0) [0|1] ""  CSM_LE,RadioHead_LE,VCU_LE,IPC_LE
 SG_ AirCndOffIO : 4|1@0+ (1,0) [0|1] ""  CSM_LE,RadioHead_LE,VCU_LE,IPC_LE
 SG_ HdLtLvlFlrIO : 2|1@0+ (1,0) [0|1] ""  CSM_LE,RadioHead_LE,VCU_LE,IPC_LE
 SG_ PwrStrIO : 17|1@0+ (1,0) [0|1] ""  CSM_LE,RadioHead_LE,VCU_LE,IPC_LE
 SG_ EngHt_StpEngIO : 15|1@0+ (1,0) [0|1] ""  CSM_LE,RadioHead_LE,VCU_LE,IPC_LE
 SG_ CkFlFilrCapIO : 14|1@0+ (1,0) [0|1] ""  CSM_LE,RadioHead_LE,VCU_LE,IPC_LE
 SG_ RdcdPwrIO : 13|1@0+ (1,0) [0|1] ""  CSM_LE,RadioHead_LE,VCU_LE,IPC_LE
 SG_ EngOilPrsLwIO : 11|1@0+ (1,0) [0|1] ""  CSM_LE,RadioHead_LE,VCU_LE,IPC_LE
 SG_ EngOilLvlLwIO : 10|1@0+ (1,0) [0|1] ""  CSM_LE,RadioHead_LE,VCU_LE,IPC_LE
 SG_ EngOilChngIO : 9|1@0+ (1,0) [0|1] ""  CSM_LE,RadioHead_LE,VCU_LE,IPC_LE
 SG_ EngHotFuelEnrchmntIO : 8|1@0+ (1,0) [0|1] ""  CSM_LE,RadioHead_LE,VCU_LE,IPC_LE
 SG_ DslGlwPlgIO : 7|1@0+ (1,0) [0|1] ""  CSM_LE,RadioHead_LE,VCU_LE,IPC_LE
 SG_ SrvLevSysIO : 1|1@0+ (1,0) [0|1] ""  CSM_LE,RadioHead_LE,VCU_LE,IPC_LE
 SG_ VehOvrLdIndOn : 0|1@0+ (1,0) [0|1] ""  CSM_LE,RadioHead_LE,VCU_LE,IPC_LE

BO_ 2154856448 Humidity_Sensor_Status_LE: 5 CGM_LE
 SG_ HmdtySnsrTemp : 17|10@0+ (0.146628,-50) [-50|100.000444] "deg C"  CSM_LE,VCU_LE,RadioHead_LE
 SG_ HmdtySnsrRltvHmdty : 39|8@0+ (0.392157,0) [0|100.000035] "%"  CSM_LE,VCU_LE,RadioHead_LE
 SG_ HmdtySnsrGlssTemp : 1|10@0+ (0.146628,-50) [-50|100.000444] "deg C"  CSM_LE,VCU_LE,RadioHead_LE

BO_TX_BU_ 2151399424 : VCU_LE,IPC_LE;
CM_ BO_ 2151530496 "LAP: Kolla oxå 0x3BA.         Imported from CA8.50 (5501)";
CM_ SG_ 2151530496 TrRrAxlPresStat "Not required for C100 DIC";
CM_ SG_ 2151530496 TrFrntAxlPresStat "Not required for C100 DIC";
CM_ SG_ 2150916096 PrkHtrCoolntTempM "Signal Shortname in CSD is PrkHtrCoolntTempMsk. This is a known discrepancy.";
CM_ SG_ 2150916096 PrkHtrFlCnsmdRolCntV "ParkHeater shall be used to denote a heater function that can operate independent of the engine operating status.";
CM_ SG_ 2150916096 PrkHtrFlCsmdRlCntRsOc "ParkHeater shall be used to denote a heater function that can operate independent of the engine operating status.";
CM_ SG_ 2150916096 PrkHtrFlCnsmdRolCnt "ParkHeater shall be used to denote a heater function that can operate independent of the engine operating status.";
CM_ SG_ 2151284736 PrkAstSnsDistrbdIO "This signal turns on a warning that tells the driver that the Parking Assist is receiving ultrasonic input that essentially makes it blind.  The system is still enabled, there is no failure in the system, but it can't perform the function.";
BA_DEF_ SG_  "VNSigPrimaryTriggering" ENUM  "No","Yes","DLCLS","DLCHS","DLCCE","DLCFO";
BA_DEF_ SG_  "VNSigRemoteDiagnostics" ENUM  "No","Yes","DLCLS","DLCHS","DLCCE","DLCFO";
BA_DEF_ SG_  "VNSigInfotainment" ENUM  "No","Yes","DLCLS","DLCHS","DLCCE","DLCFO";
BA_DEF_ SG_  "VNSigParkedVehicle" ENUM  "No","Yes","DLCLS","DLCHS","DLCCE","DLCFO";
BA_DEF_ SG_  "VNSigIntermediate" ENUM  "No","Yes","DLCLS","DLCHS","DLCCE","DLCFO";
BA_DEF_ SG_  "VNSigUnused_4" ENUM  "No","Yes","DLCLS","DLCHS","DLCCE","DLCFO";
BA_DEF_ SG_  "SignalType" STRING ;
BA_DEF_ SG_  "PacketOrder" INT 0 65535;
BA_DEF_ SG_  "SignalLongName" STRING ;
BA_DEF_ SG_  "GenSigStartValue" INT 0 65535;
BA_DEF_ SG_  "VNSigDiagnostic" ENUM  "No","Yes","DLCLS","DLCHS","DLCCE","DLCFO";
BA_DEF_ SG_  "VNSigAllNodes" ENUM  "No","Yes","DLCLS","DLCHS","DLCCE","DLCFO";
BA_DEF_ SG_  "GenSigDeltaValue" INT 0 0;
BA_DEF_ SG_  "GenSigSendType" ENUM  "not used","not used","not used","not used","not used","not used","not used","NoSigSendType","not used","not used","OnAnyChange","OnChangeIfActive","OnDelta","DLCLS","DLCHS","DLCCE","DLCFO";
BA_DEF_ SG_  "GenSigSendOnInit" ENUM  "Not Initialized","Application","Handler","DLCLS","DLCHS","DLCCE","DLCFO";
BA_DEF_ BO_  "AppGenMsgCycleTime" INT 0 0;
BA_DEF_ BO_  "TpTxIndex" INT 0 99;
BA_DEF_ BO_  "GenMsgILSupport" ENUM  "No","Yes","DLCLS","DLCHS","DLCCE","DLCFO";
BA_DEF_ BO_  "TpApplType" STRING ;
BA_DEF_ BO_  "Prio" INT 0 7;
BA_DEF_ BO_  "MessageSubnet" ENUM  "LS","MS","HS","CE","PE","HV","FO","S1","HE","LE","HE2","DLCLS","DLCHS","DLCCE","DLCFO";
BA_DEF_ BO_  "GenMsgMandatoryToSupervision" ENUM  "No","Yes","DLCLS","DLCHS","DLCCE","DLCFO";
BA_DEF_ BO_  "DiagState" ENUM  "No","Yes","DLCLS","DLCHS","DLCCE","DLCFO";
BA_DEF_ BO_  "GenMsgStartDelayTime" INT 0 100000;
BA_DEF_ BO_  "GenMsgDelayTime" INT 0 100000;
BA_DEF_ BO_  "GenMsgCycleTime" INT 0 100000;
BA_DEF_ BO_  "GenMsgSendType" ENUM  "cyclicX","spontanX","cyclicIfActiveX","spontanWithDelay","cyclicAndSpontanX","cyclicAndSpontanWithDelay","spontanWithRepitition","cyclicIfActiveAndSpontanWD","DLCLS","DLCHS","DLCCE","DLCFO";
BA_DEF_ BO_  "DiagResponse" ENUM  "No","Yes","DLCLS","DLCHS","DLCCE","DLCFO";
BA_DEF_ BO_  "DiagRequest" ENUM  "No","Yes","DLCLS","DLCHS","DLCCE","DLCFO";
BA_DEF_ BO_  "NmMessage" ENUM  "No","Yes","DLCLS","DLCHS","DLCCE","DLCFO";
BA_DEF_REL_ BU_SG_REL_  "GenSigSuprvRespComment" STRING ;
BA_DEF_REL_ BU_SG_REL_  "GenSigVBitResp" ENUM  "No","Yes","DLCLS","DLCHS","DLCCE","DLCFO";
BA_DEF_REL_ BU_SG_REL_  "GenSigVBitRespComment" STRING ;
BA_DEF_REL_ BU_SG_REL_  "GenSigVDAFailComment" STRING ;
BA_DEF_REL_ BU_SG_REL_  "GenSigVDAFailResp" ENUM  "No","Yes","DLCLS","DLCHS","DLCCE","DLCFO";
BA_DEF_REL_ BU_SG_REL_  "GenSigRxStartValue" STRING ;
BA_DEF_REL_ BU_SG_REL_  "GenSigSuprvRespSubValue" INT 0 65535;
BA_DEF_REL_ BU_SG_REL_  "GenSigSuprvResp" ENUM  "None","Notify App","Substitute Default","DLCLS","DLCHS","DLCCE","DLCFO";
BA_DEF_REL_ BU_SG_REL_  "GenSigTimeoutMsg" HEX -2147483648 268435455;
BA_DEF_DEF_  "VNSigPrimaryTriggering" "No";
BA_DEF_DEF_  "VNSigRemoteDiagnostics" "No";
BA_DEF_DEF_  "VNSigInfotainment" "No";
BA_DEF_DEF_  "VNSigParkedVehicle" "No";
BA_DEF_DEF_  "VNSigIntermediate" "No";
BA_DEF_DEF_  "VNSigUnused_4" "No";
BA_DEF_DEF_  "SignalType" "";
BA_DEF_DEF_  "PacketOrder" 0;
BA_DEF_DEF_  "SignalLongName" "";
BA_DEF_DEF_  "GenSigStartValue" 0;
BA_DEF_DEF_  "VNSigDiagnostic" "No";
BA_DEF_DEF_  "VNSigAllNodes" "No";
BA_DEF_DEF_  "GenSigDeltaValue" 0;
BA_DEF_DEF_  "GenSigSendType" "NoSigSendType";
BA_DEF_DEF_  "GenSigSendOnInit" "Not Initialized";
BA_DEF_DEF_  "AppGenMsgCycleTime" 0;
BA_DEF_DEF_  "TpTxIndex" 0;
BA_DEF_DEF_  "GenMsgILSupport" "Yes";
BA_DEF_DEF_  "TpApplType" "";
BA_DEF_DEF_  "Prio" 4;
BA_DEF_DEF_  "MessageSubnet" "FO";
BA_DEF_DEF_  "GenMsgMandatoryToSupervision" "No";
BA_DEF_DEF_  "DiagState" "No";
BA_DEF_DEF_  "GenMsgStartDelayTime" 0;
BA_DEF_DEF_  "GenMsgDelayTime" 0;
BA_DEF_DEF_  "GenMsgCycleTime" 0;
BA_DEF_DEF_  "GenMsgSendType" "spontanX";
BA_DEF_DEF_  "DiagResponse" "No";
BA_DEF_DEF_  "DiagRequest" "No";
BA_DEF_DEF_  "NmMessage" "No";
BA_DEF_DEF_REL_ "GenSigSuprvRespComment" "";
BA_DEF_DEF_REL_ "GenSigVBitResp" "No";
BA_DEF_DEF_REL_ "GenSigVBitRespComment" "";
BA_DEF_DEF_REL_ "GenSigVDAFailComment" "";
BA_DEF_DEF_REL_ "GenSigVDAFailResp" "No";
BA_DEF_DEF_REL_ "GenSigRxStartValue" "";
BA_DEF_DEF_REL_ "GenSigSuprvRespSubValue" 0;
BA_DEF_DEF_REL_ "GenSigSuprvResp" "None";
BA_DEF_DEF_REL_ "GenSigTimeoutMsg" 0;
BA_ "MessageSubnet" BO_ 2155102208 9;
BA_ "GenMsgDelayTime" BO_ 2155102208 100;
BA_ "MessageSubnet" BO_ 2155085824 9;
BA_ "GenMsgDelayTime" BO_ 2155085824 100;
BA_ "MessageSubnet" BO_ 2152120320 9;
BA_ "GenMsgDelayTime" BO_ 2152120320 100;
BA_ "MessageSubnet" BO_ 2152103936 9;
BA_ "GenMsgDelayTime" BO_ 2152103936 100;
BA_ "MessageSubnet" BO_ 2152087552 9;
BA_ "GenMsgDelayTime" BO_ 2152087552 100;
BA_ "MessageSubnet" BO_ 2152071168 9;
BA_ "GenMsgDelayTime" BO_ 2152071168 100;
BA_ "MessageSubnet" BO_ 2153308160 9;
BA_ "GenMsgStartDelayTime" BO_ 2153308160 100;
BA_ "GenMsgCycleTime" BO_ 2153308160 1000;
BA_ "GenMsgSendType" BO_ 2153308160 0;
BA_ "MessageSubnet" BO_ 2149924864 9;
BA_ "GenMsgDelayTime" BO_ 2149924864 100;
BA_ "MessageSubnet" BO_ 2151153664 9;
BA_ "GenMsgDelayTime" BO_ 2151153664 100;
BA_ "MessageSubnet" BO_ 2151841792 9;
BA_ "GenMsgDelayTime" BO_ 2151841792 100;
BA_ "MessageSubnet" BO_ 2154078208 9;
BA_ "GenMsgDelayTime" BO_ 2154078208 200;
BA_ "MessageSubnet" BO_ 2151399424 9;
BA_ "GenMsgDelayTime" BO_ 2151399424 100;
BA_ "MessageSubnet" BO_ 2151170048 9;
BA_ "GenMsgDelayTime" BO_ 2151170048 100;
BA_ "MessageSubnet" BO_ 2152759296 9;
BA_ "GenMsgDelayTime" BO_ 2152759296 100;
BA_ "MessageSubnet" BO_ 2150850560 9;
BA_ "GenMsgDelayTime" BO_ 2150850560 100;
BA_ "Prio" BO_ 2150604800 3;
BA_ "MessageSubnet" BO_ 2150604800 9;
BA_ "GenMsgDelayTime" BO_ 2150604800 100;
BA_ "Prio" BO_ 2151219200 3;
BA_ "MessageSubnet" BO_ 2151219200 9;
BA_ "GenMsgDelayTime" BO_ 2151219200 100;
BA_ "MessageSubnet" BO_ 2150514688 9;
BA_ "GenMsgDelayTime" BO_ 2150514688 100;
BA_ "MessageSubnet" BO_ 2155208704 9;
BA_ "GenMsgDelayTime" BO_ 2155208704 100;
BA_ "MessageSubnet" BO_ 2151530496 9;
BA_ "GenMsgDelayTime" BO_ 2151530496 100;
BA_ "MessageSubnet" BO_ 2151497728 9;
BA_ "GenMsgDelayTime" BO_ 2151497728 100;
BA_ "Prio" BO_ 2150588416 3;
BA_ "MessageSubnet" BO_ 2150588416 9;
BA_ "GenMsgDelayTime" BO_ 2150588416 100;
BA_ "MessageSubnet" BO_ 2150916096 9;
BA_ "GenMsgDelayTime" BO_ 2150916096 100;
BA_ "MessageSubnet" BO_ 2151366656 9;
BA_ "GenMsgDelayTime" BO_ 2151366656 100;
BA_ "MessageSubnet" BO_ 2151284736 9;
BA_ "GenMsgDelayTime" BO_ 2151284736 100;
BA_ "Prio" BO_ 2150596608 3;
BA_ "MessageSubnet" BO_ 2150596608 9;
BA_ "GenMsgDelayTime" BO_ 2150596608 100;
BA_ "MessageSubnet" BO_ 2155380736 9;
BA_ "GenMsgStartDelayTime" BO_ 2155380736 180;
BA_ "GenMsgDelayTime" BO_ 2155380736 10;
BA_ "GenMsgCycleTime" BO_ 2155380736 500;
BA_ "GenMsgSendType" BO_ 2155380736 0;
BA_ "MessageSubnet" BO_ 2154856448 9;
BA_ "GenMsgDelayTime" BO_ 2154856448 100;
BA_ "GenSigSendType" SG_ 2155102208 DSMP_UnsdRsrvd 10;
BA_ "GenSigSendOnInit" SG_ 2155102208 DSMP_UnsdRsrvd 2;
BA_ "SignalType" SG_ 2155102208 DSMP_UnsdRsrvd "BLN";
BA_ "PacketOrder" SG_ 2155102208 DSMP_UnsdRsrvd 17;
BA_ "SignalLongName" SG_ 2155102208 DSMP_UnsdRsrvd "Driver Seat Massage Priority : Unused and Reserved";
BA_ "VNSigAllNodes" SG_ 2155102208 DSMP_UnsdRsrvd 1;
BA_ "GenSigDeltaValue" SG_ 2155102208 DSMP_MaxDispVal 1;
BA_ "GenSigSendType" SG_ 2155102208 DSMP_MaxDispVal 12;
BA_ "GenSigSendOnInit" SG_ 2155102208 DSMP_MaxDispVal 2;
BA_ "SignalType" SG_ 2155102208 DSMP_MaxDispVal "UNM";
BA_ "PacketOrder" SG_ 2155102208 DSMP_MaxDispVal 16;
BA_ "SignalLongName" SG_ 2155102208 DSMP_MaxDispVal "Driver Seat Massage Priority : Maximum Display Value";
BA_ "VNSigAllNodes" SG_ 2155102208 DSMP_MaxDispVal 1;
BA_ "GenSigDeltaValue" SG_ 2155102208 DSMP_Type15 1;
BA_ "GenSigSendType" SG_ 2155102208 DSMP_Type15 12;
BA_ "GenSigSendOnInit" SG_ 2155102208 DSMP_Type15 2;
BA_ "SignalType" SG_ 2155102208 DSMP_Type15 "UNM";
BA_ "PacketOrder" SG_ 2155102208 DSMP_Type15 15;
BA_ "SignalLongName" SG_ 2155102208 DSMP_Type15 "Driver Seat Massage Priority : Type 15";
BA_ "VNSigAllNodes" SG_ 2155102208 DSMP_Type15 1;
BA_ "GenSigDeltaValue" SG_ 2155102208 DSMP_Type14 1;
BA_ "GenSigSendType" SG_ 2155102208 DSMP_Type14 12;
BA_ "GenSigSendOnInit" SG_ 2155102208 DSMP_Type14 2;
BA_ "SignalType" SG_ 2155102208 DSMP_Type14 "UNM";
BA_ "PacketOrder" SG_ 2155102208 DSMP_Type14 14;
BA_ "SignalLongName" SG_ 2155102208 DSMP_Type14 "Driver Seat Massage Priority : Type 14";
BA_ "VNSigAllNodes" SG_ 2155102208 DSMP_Type14 1;
BA_ "GenSigDeltaValue" SG_ 2155102208 DSMP_Type13 1;
BA_ "GenSigSendType" SG_ 2155102208 DSMP_Type13 12;
BA_ "GenSigSendOnInit" SG_ 2155102208 DSMP_Type13 2;
BA_ "SignalType" SG_ 2155102208 DSMP_Type13 "UNM";
BA_ "PacketOrder" SG_ 2155102208 DSMP_Type13 13;
BA_ "SignalLongName" SG_ 2155102208 DSMP_Type13 "Driver Seat Massage Priority : Type 13";
BA_ "VNSigAllNodes" SG_ 2155102208 DSMP_Type13 1;
BA_ "GenSigDeltaValue" SG_ 2155102208 DSMP_Type12 1;
BA_ "GenSigSendType" SG_ 2155102208 DSMP_Type12 12;
BA_ "GenSigSendOnInit" SG_ 2155102208 DSMP_Type12 2;
BA_ "SignalType" SG_ 2155102208 DSMP_Type12 "UNM";
BA_ "PacketOrder" SG_ 2155102208 DSMP_Type12 12;
BA_ "SignalLongName" SG_ 2155102208 DSMP_Type12 "Driver Seat Massage Priority : Type 12";
BA_ "VNSigAllNodes" SG_ 2155102208 DSMP_Type12 1;
BA_ "GenSigDeltaValue" SG_ 2155102208 DSMP_Type11 1;
BA_ "GenSigSendType" SG_ 2155102208 DSMP_Type11 12;
BA_ "GenSigSendOnInit" SG_ 2155102208 DSMP_Type11 2;
BA_ "SignalType" SG_ 2155102208 DSMP_Type11 "UNM";
BA_ "PacketOrder" SG_ 2155102208 DSMP_Type11 11;
BA_ "SignalLongName" SG_ 2155102208 DSMP_Type11 "Driver Seat Massage Priority : Type 11";
BA_ "VNSigAllNodes" SG_ 2155102208 DSMP_Type11 1;
BA_ "GenSigDeltaValue" SG_ 2155102208 DSMP_Type10 1;
BA_ "GenSigSendType" SG_ 2155102208 DSMP_Type10 12;
BA_ "GenSigSendOnInit" SG_ 2155102208 DSMP_Type10 2;
BA_ "SignalType" SG_ 2155102208 DSMP_Type10 "UNM";
BA_ "PacketOrder" SG_ 2155102208 DSMP_Type10 10;
BA_ "SignalLongName" SG_ 2155102208 DSMP_Type10 "Driver Seat Massage Priority : Type 10";
BA_ "VNSigAllNodes" SG_ 2155102208 DSMP_Type10 1;
BA_ "GenSigDeltaValue" SG_ 2155102208 DSMP_Type9 1;
BA_ "GenSigSendType" SG_ 2155102208 DSMP_Type9 12;
BA_ "GenSigSendOnInit" SG_ 2155102208 DSMP_Type9 2;
BA_ "SignalType" SG_ 2155102208 DSMP_Type9 "UNM";
BA_ "PacketOrder" SG_ 2155102208 DSMP_Type9 9;
BA_ "SignalLongName" SG_ 2155102208 DSMP_Type9 "Driver Seat Massage Priority : Type 9";
BA_ "VNSigAllNodes" SG_ 2155102208 DSMP_Type9 1;
BA_ "GenSigDeltaValue" SG_ 2155102208 DSMP_Type8 1;
BA_ "GenSigSendType" SG_ 2155102208 DSMP_Type8 12;
BA_ "GenSigSendOnInit" SG_ 2155102208 DSMP_Type8 2;
BA_ "SignalType" SG_ 2155102208 DSMP_Type8 "UNM";
BA_ "PacketOrder" SG_ 2155102208 DSMP_Type8 8;
BA_ "SignalLongName" SG_ 2155102208 DSMP_Type8 "Driver Seat Massage Priority : Type 8";
BA_ "VNSigAllNodes" SG_ 2155102208 DSMP_Type8 1;
BA_ "GenSigDeltaValue" SG_ 2155102208 DSMP_Type7 1;
BA_ "GenSigSendType" SG_ 2155102208 DSMP_Type7 12;
BA_ "GenSigSendOnInit" SG_ 2155102208 DSMP_Type7 2;
BA_ "SignalType" SG_ 2155102208 DSMP_Type7 "UNM";
BA_ "PacketOrder" SG_ 2155102208 DSMP_Type7 7;
BA_ "SignalLongName" SG_ 2155102208 DSMP_Type7 "Driver Seat Massage Priority : Type 7";
BA_ "VNSigAllNodes" SG_ 2155102208 DSMP_Type7 1;
BA_ "GenSigDeltaValue" SG_ 2155102208 DSMP_Type6 1;
BA_ "GenSigSendType" SG_ 2155102208 DSMP_Type6 12;
BA_ "GenSigSendOnInit" SG_ 2155102208 DSMP_Type6 2;
BA_ "SignalType" SG_ 2155102208 DSMP_Type6 "UNM";
BA_ "PacketOrder" SG_ 2155102208 DSMP_Type6 6;
BA_ "SignalLongName" SG_ 2155102208 DSMP_Type6 "Driver Seat Massage Priority : Type 6";
BA_ "VNSigAllNodes" SG_ 2155102208 DSMP_Type6 1;
BA_ "GenSigDeltaValue" SG_ 2155102208 DSMP_Type5 1;
BA_ "GenSigSendType" SG_ 2155102208 DSMP_Type5 12;
BA_ "GenSigSendOnInit" SG_ 2155102208 DSMP_Type5 2;
BA_ "SignalType" SG_ 2155102208 DSMP_Type5 "UNM";
BA_ "PacketOrder" SG_ 2155102208 DSMP_Type5 5;
BA_ "SignalLongName" SG_ 2155102208 DSMP_Type5 "Driver Seat Massage Priority : Type 5";
BA_ "VNSigAllNodes" SG_ 2155102208 DSMP_Type5 1;
BA_ "GenSigDeltaValue" SG_ 2155102208 DSMP_Type4 1;
BA_ "GenSigSendType" SG_ 2155102208 DSMP_Type4 12;
BA_ "GenSigSendOnInit" SG_ 2155102208 DSMP_Type4 2;
BA_ "SignalType" SG_ 2155102208 DSMP_Type4 "UNM";
BA_ "PacketOrder" SG_ 2155102208 DSMP_Type4 4;
BA_ "SignalLongName" SG_ 2155102208 DSMP_Type4 "Driver Seat Massage Priority : Type 4";
BA_ "VNSigAllNodes" SG_ 2155102208 DSMP_Type4 1;
BA_ "GenSigDeltaValue" SG_ 2155102208 DSMP_Type3 1;
BA_ "GenSigSendType" SG_ 2155102208 DSMP_Type3 12;
BA_ "GenSigSendOnInit" SG_ 2155102208 DSMP_Type3 2;
BA_ "SignalType" SG_ 2155102208 DSMP_Type3 "UNM";
BA_ "PacketOrder" SG_ 2155102208 DSMP_Type3 3;
BA_ "SignalLongName" SG_ 2155102208 DSMP_Type3 "Driver Seat Massage Priority : Type 3";
BA_ "VNSigAllNodes" SG_ 2155102208 DSMP_Type3 1;
BA_ "GenSigDeltaValue" SG_ 2155102208 DSMP_Type2 1;
BA_ "GenSigSendType" SG_ 2155102208 DSMP_Type2 12;
BA_ "GenSigSendOnInit" SG_ 2155102208 DSMP_Type2 2;
BA_ "SignalType" SG_ 2155102208 DSMP_Type2 "UNM";
BA_ "PacketOrder" SG_ 2155102208 DSMP_Type2 2;
BA_ "SignalLongName" SG_ 2155102208 DSMP_Type2 "Driver Seat Massage Priority : Type 2";
BA_ "VNSigAllNodes" SG_ 2155102208 DSMP_Type2 1;
BA_ "GenSigDeltaValue" SG_ 2155102208 DSMP_Type1 1;
BA_ "GenSigSendType" SG_ 2155102208 DSMP_Type1 12;
BA_ "GenSigSendOnInit" SG_ 2155102208 DSMP_Type1 2;
BA_ "SignalType" SG_ 2155102208 DSMP_Type1 "UNM";
BA_ "PacketOrder" SG_ 2155102208 DSMP_Type1 1;
BA_ "SignalLongName" SG_ 2155102208 DSMP_Type1 "Driver Seat Massage Priority : Type 1";
BA_ "VNSigAllNodes" SG_ 2155102208 DSMP_Type1 1;
BA_ "GenSigDeltaValue" SG_ 2155085824 StrgColUpDwnPos 1;
BA_ "GenSigSendType" SG_ 2155085824 StrgColUpDwnPos 12;
BA_ "SignalType" SG_ 2155085824 StrgColUpDwnPos "UNM";
BA_ "SignalLongName" SG_ 2155085824 StrgColUpDwnPos "Steering Column Up Down Position";
BA_ "VNSigAllNodes" SG_ 2155085824 StrgColUpDwnPos 1;
BA_ "GenSigSendType" SG_ 2155085824 CPMAPINFO4 10;
BA_ "SignalType" SG_ 2155085824 CPMAPINFO4 "ENM";
BA_ "SignalLongName" SG_ 2155085824 CPMAPINFO4 "Steering Column Internal Fault";
BA_ "VNSigAllNodes" SG_ 2155085824 CPMAPINFO4 1;
BA_ "GenSigDeltaValue" SG_ 2155085824 StrgColInOutPos 1;
BA_ "GenSigSendType" SG_ 2155085824 StrgColInOutPos 12;
BA_ "SignalType" SG_ 2155085824 StrgColInOutPos "UNM";
BA_ "SignalLongName" SG_ 2155085824 StrgColInOutPos "Steering Column In Out Position";
BA_ "VNSigAllNodes" SG_ 2155085824 StrgColInOutPos 1;
BA_ "GenSigSendType" SG_ 2155085824 StrgColCommsFlt 10;
BA_ "SignalType" SG_ 2155085824 StrgColCommsFlt "ENM";
BA_ "SignalLongName" SG_ 2155085824 StrgColCommsFlt "Steering Column Communications Fault";
BA_ "VNSigAllNodes" SG_ 2155085824 StrgColCommsFlt 1;
BA_ "GenSigDeltaValue" SG_ 2155085824 DSCDS_UnsdRsrvd 1;
BA_ "GenSigSendType" SG_ 2155085824 DSCDS_UnsdRsrvd 12;
BA_ "GenSigSendOnInit" SG_ 2155085824 DSCDS_UnsdRsrvd 2;
BA_ "SignalType" SG_ 2155085824 DSCDS_UnsdRsrvd "UNM";
BA_ "PacketOrder" SG_ 2155085824 DSCDS_UnsdRsrvd 19;
BA_ "SignalLongName" SG_ 2155085824 DSCDS_UnsdRsrvd "Driver Seat Control Display Status : Unused and Reserved";
BA_ "VNSigAllNodes" SG_ 2155085824 DSCDS_UnsdRsrvd 1;
BA_ "GenSigSendType" SG_ 2155085824 DSCDS_DispReq 10;
BA_ "GenSigSendOnInit" SG_ 2155085824 DSCDS_DispReq 2;
BA_ "SignalType" SG_ 2155085824 DSCDS_DispReq "BLN";
BA_ "PacketOrder" SG_ 2155085824 DSCDS_DispReq 18;
BA_ "SignalLongName" SG_ 2155085824 DSCDS_DispReq "Driver Seat Control Display Status : Display Request";
BA_ "VNSigAllNodes" SG_ 2155085824 DSCDS_DispReq 1;
BA_ "GenSigSendType" SG_ 2155085824 DSCDS_DispSz 10;
BA_ "GenSigSendOnInit" SG_ 2155085824 DSCDS_DispSz 2;
BA_ "SignalType" SG_ 2155085824 DSCDS_DispSz "ENM";
BA_ "PacketOrder" SG_ 2155085824 DSCDS_DispSz 17;
BA_ "SignalLongName" SG_ 2155085824 DSCDS_DispSz "Driver Seat Control Display Status : Display Size";
BA_ "VNSigAllNodes" SG_ 2155085824 DSCDS_DispSz 1;
BA_ "GenSigSendType" SG_ 2155085824 DSCDS_CshLgAdjFdRr 10;
BA_ "GenSigSendOnInit" SG_ 2155085824 DSCDS_CshLgAdjFdRr 2;
BA_ "SignalType" SG_ 2155085824 DSCDS_CshLgAdjFdRr "ENM";
BA_ "PacketOrder" SG_ 2155085824 DSCDS_CshLgAdjFdRr 16;
BA_ "SignalLongName" SG_ 2155085824 DSCDS_CshLgAdjFdRr "Driver Seat Control Display Status : Cushion Length Adjustment Forward/Rearward";
BA_ "VNSigAllNodes" SG_ 2155085824 DSCDS_CshLgAdjFdRr 1;
BA_ "GenSigSendType" SG_ 2155085824 DSCDS_BkCshBlstInOt 10;
BA_ "GenSigSendOnInit" SG_ 2155085824 DSCDS_BkCshBlstInOt 2;
BA_ "SignalType" SG_ 2155085824 DSCDS_BkCshBlstInOt "ENM";
BA_ "PacketOrder" SG_ 2155085824 DSCDS_BkCshBlstInOt 15;
BA_ "SignalLongName" SG_ 2155085824 DSCDS_BkCshBlstInOt "Driver Seat Control Display Status : Back and Cushion Bolster In/Out";
BA_ "VNSigAllNodes" SG_ 2155085824 DSCDS_BkCshBlstInOt 1;
BA_ "GenSigSendType" SG_ 2155085824 DSCDS_CshBlstrInOut 10;
BA_ "GenSigSendOnInit" SG_ 2155085824 DSCDS_CshBlstrInOut 2;
BA_ "SignalType" SG_ 2155085824 DSCDS_CshBlstrInOut "ENM";
BA_ "PacketOrder" SG_ 2155085824 DSCDS_CshBlstrInOut 14;
BA_ "SignalLongName" SG_ 2155085824 DSCDS_CshBlstrInOut "Driver Seat Control Display Status : Cushion Bolster In/Out";
BA_ "VNSigAllNodes" SG_ 2155085824 DSCDS_CshBlstrInOut 1;
BA_ "GenSigSendType" SG_ 2155085824 DSCDS_BkBlstrInOut 10;
BA_ "GenSigSendOnInit" SG_ 2155085824 DSCDS_BkBlstrInOut 2;
BA_ "SignalType" SG_ 2155085824 DSCDS_BkBlstrInOut "ENM";
BA_ "PacketOrder" SG_ 2155085824 DSCDS_BkBlstrInOut 13;
BA_ "SignalLongName" SG_ 2155085824 DSCDS_BkBlstrInOut "Driver Seat Control Display Status : Back Bolster In/Out";
BA_ "VNSigAllNodes" SG_ 2155085824 DSCDS_BkBlstrInOut 1;
BA_ "GenSigSendType" SG_ 2155085824 DSCDS_LmbrUDnFdRr 10;
BA_ "GenSigSendOnInit" SG_ 2155085824 DSCDS_LmbrUDnFdRr 2;
BA_ "SignalType" SG_ 2155085824 DSCDS_LmbrUDnFdRr "ENM";
BA_ "PacketOrder" SG_ 2155085824 DSCDS_LmbrUDnFdRr 12;
BA_ "SignalLongName" SG_ 2155085824 DSCDS_LmbrUDnFdRr "Driver Seat Control Display Status : Lumbar Up/Down and Forward/Rearward";
BA_ "VNSigAllNodes" SG_ 2155085824 DSCDS_LmbrUDnFdRr 1;
BA_ "GenSigSendType" SG_ 2155085824 DSCDS_LmbrFwdRr 10;
BA_ "GenSigSendOnInit" SG_ 2155085824 DSCDS_LmbrFwdRr 2;
BA_ "SignalType" SG_ 2155085824 DSCDS_LmbrFwdRr "ENM";
BA_ "PacketOrder" SG_ 2155085824 DSCDS_LmbrFwdRr 11;
BA_ "SignalLongName" SG_ 2155085824 DSCDS_LmbrFwdRr "Driver Seat Control Display Status : Lumbar Forward/Rearward";
BA_ "VNSigAllNodes" SG_ 2155085824 DSCDS_LmbrFwdRr 1;
BA_ "GenSigSendType" SG_ 2155085824 DSCDS_LmbrUpDwn 10;
BA_ "GenSigSendOnInit" SG_ 2155085824 DSCDS_LmbrUpDwn 2;
BA_ "SignalType" SG_ 2155085824 DSCDS_LmbrUpDwn "ENM";
BA_ "PacketOrder" SG_ 2155085824 DSCDS_LmbrUpDwn 10;
BA_ "SignalLongName" SG_ 2155085824 DSCDS_LmbrUpDwn "Driver Seat Control Display Status : Lumbar Up/Down";
BA_ "VNSigAllNodes" SG_ 2155085824 DSCDS_LmbrUpDwn 1;
BA_ "GenSigSendType" SG_ 2155085824 DSCDS_UprShldrFdRr 10;
BA_ "GenSigSendOnInit" SG_ 2155085824 DSCDS_UprShldrFdRr 2;
BA_ "SignalType" SG_ 2155085824 DSCDS_UprShldrFdRr "ENM";
BA_ "PacketOrder" SG_ 2155085824 DSCDS_UprShldrFdRr 9;
BA_ "SignalLongName" SG_ 2155085824 DSCDS_UprShldrFdRr "Driver Seat Control Display Status : Upper Shoulder Forward/Rearward";
BA_ "VNSigAllNodes" SG_ 2155085824 DSCDS_UprShldrFdRr 1;
BA_ "GenSigSendType" SG_ 2155085824 DSCDS_HdrstTltFwdRr 10;
BA_ "GenSigSendOnInit" SG_ 2155085824 DSCDS_HdrstTltFwdRr 2;
BA_ "SignalType" SG_ 2155085824 DSCDS_HdrstTltFwdRr "ENM";
BA_ "PacketOrder" SG_ 2155085824 DSCDS_HdrstTltFwdRr 8;
BA_ "SignalLongName" SG_ 2155085824 DSCDS_HdrstTltFwdRr "Driver Seat Control Display Status : Headrest Tilt Forward/Rearward";
BA_ "VNSigAllNodes" SG_ 2155085824 DSCDS_HdrstTltFwdRr 1;
BA_ "GenSigSendType" SG_ 2155085824 DSCDS_HdrstWngInOt 10;
BA_ "GenSigSendOnInit" SG_ 2155085824 DSCDS_HdrstWngInOt 2;
BA_ "SignalType" SG_ 2155085824 DSCDS_HdrstWngInOt "ENM";
BA_ "PacketOrder" SG_ 2155085824 DSCDS_HdrstWngInOt 7;
BA_ "SignalLongName" SG_ 2155085824 DSCDS_HdrstWngInOt "Driver Seat Control Display Status : Headrest Wings In/Out";
BA_ "VNSigAllNodes" SG_ 2155085824 DSCDS_HdrstWngInOt 1;
BA_ "GenSigSendType" SG_ 2155085824 DSCDS_HdrstUDnFdRr 10;
BA_ "GenSigSendOnInit" SG_ 2155085824 DSCDS_HdrstUDnFdRr 2;
BA_ "SignalType" SG_ 2155085824 DSCDS_HdrstUDnFdRr "ENM";
BA_ "PacketOrder" SG_ 2155085824 DSCDS_HdrstUDnFdRr 6;
BA_ "SignalLongName" SG_ 2155085824 DSCDS_HdrstUDnFdRr "Driver Seat Control Display Status : Headrest Forward/Rearward and Up/Down";
BA_ "VNSigAllNodes" SG_ 2155085824 DSCDS_HdrstUDnFdRr 1;
BA_ "GenSigSendType" SG_ 2155085824 DSCDS_HdrstFwdRrwd 10;
BA_ "GenSigSendOnInit" SG_ 2155085824 DSCDS_HdrstFwdRrwd 2;
BA_ "SignalType" SG_ 2155085824 DSCDS_HdrstFwdRrwd "ENM";
BA_ "PacketOrder" SG_ 2155085824 DSCDS_HdrstFwdRrwd 5;
BA_ "SignalLongName" SG_ 2155085824 DSCDS_HdrstFwdRrwd "Driver Seat Control Display Status : Headrest Forward/Rearward";
BA_ "VNSigAllNodes" SG_ 2155085824 DSCDS_HdrstFwdRrwd 1;
BA_ "GenSigSendType" SG_ 2155085824 DSCDS_HdrstUpDn 10;
BA_ "GenSigSendOnInit" SG_ 2155085824 DSCDS_HdrstUpDn 2;
BA_ "SignalType" SG_ 2155085824 DSCDS_HdrstUpDn "ENM";
BA_ "PacketOrder" SG_ 2155085824 DSCDS_HdrstUpDn 4;
BA_ "SignalLongName" SG_ 2155085824 DSCDS_HdrstUpDn "Driver Seat Control Display Status : Headrest Up/Down";
BA_ "VNSigAllNodes" SG_ 2155085824 DSCDS_HdrstUpDn 1;
BA_ "GenSigSendType" SG_ 2155085824 DSCDS_MassgIntsty 10;
BA_ "GenSigSendOnInit" SG_ 2155085824 DSCDS_MassgIntsty 2;
BA_ "SignalType" SG_ 2155085824 DSCDS_MassgIntsty "ENM";
BA_ "PacketOrder" SG_ 2155085824 DSCDS_MassgIntsty 3;
BA_ "SignalLongName" SG_ 2155085824 DSCDS_MassgIntsty "Driver Seat Control Display Status : Massage Intensity";
BA_ "VNSigAllNodes" SG_ 2155085824 DSCDS_MassgIntsty 1;
BA_ "GenSigSendType" SG_ 2155085824 DSCDS_MassgTyp 10;
BA_ "GenSigSendOnInit" SG_ 2155085824 DSCDS_MassgTyp 2;
BA_ "SignalType" SG_ 2155085824 DSCDS_MassgTyp "ENM";
BA_ "PacketOrder" SG_ 2155085824 DSCDS_MassgTyp 2;
BA_ "SignalLongName" SG_ 2155085824 DSCDS_MassgTyp "Driver Seat Control Display Status : Massage Type";
BA_ "VNSigAllNodes" SG_ 2155085824 DSCDS_MassgTyp 1;
BA_ "GenSigSendType" SG_ 2155085824 DSCDS_Massg 10;
BA_ "GenSigSendOnInit" SG_ 2155085824 DSCDS_Massg 2;
BA_ "SignalType" SG_ 2155085824 DSCDS_Massg "ENM";
BA_ "PacketOrder" SG_ 2155085824 DSCDS_Massg 1;
BA_ "SignalLongName" SG_ 2155085824 DSCDS_Massg "Driver Seat Control Display Status : Massage";
BA_ "VNSigAllNodes" SG_ 2155085824 DSCDS_Massg 1;
BA_ "GenSigDeltaValue" SG_ 2152120320 RRSAP_UnsdRsrvd 1;
BA_ "GenSigSendType" SG_ 2152120320 RRSAP_UnsdRsrvd 12;
BA_ "GenSigSendOnInit" SG_ 2152120320 RRSAP_UnsdRsrvd 2;
BA_ "SignalType" SG_ 2152120320 RRSAP_UnsdRsrvd "UNM";
BA_ "PacketOrder" SG_ 2152120320 RRSAP_UnsdRsrvd 16;
BA_ "SignalLongName" SG_ 2152120320 RRSAP_UnsdRsrvd "Right Rear Seat Actuator Priority : Unused and Reserved";
BA_ "VNSigAllNodes" SG_ 2152120320 RRSAP_UnsdRsrvd 1;
BA_ "GenSigDeltaValue" SG_ 2152120320 RRSAP_DispSz 1;
BA_ "GenSigSendType" SG_ 2152120320 RRSAP_DispSz 12;
BA_ "GenSigSendOnInit" SG_ 2152120320 RRSAP_DispSz 2;
BA_ "SignalType" SG_ 2152120320 RRSAP_DispSz "UNM";
BA_ "PacketOrder" SG_ 2152120320 RRSAP_DispSz 15;
BA_ "SignalLongName" SG_ 2152120320 RRSAP_DispSz "Right Rear Seat Actuator Priority : Display Size";
BA_ "VNSigAllNodes" SG_ 2152120320 RRSAP_DispSz 1;
BA_ "GenSigDeltaValue" SG_ 2152120320 RRSAP_CshLgthAdjFdRr 1;
BA_ "GenSigSendType" SG_ 2152120320 RRSAP_CshLgthAdjFdRr 12;
BA_ "GenSigSendOnInit" SG_ 2152120320 RRSAP_CshLgthAdjFdRr 2;
BA_ "SignalType" SG_ 2152120320 RRSAP_CshLgthAdjFdRr "UNM";
BA_ "PacketOrder" SG_ 2152120320 RRSAP_CshLgthAdjFdRr 14;
BA_ "SignalLongName" SG_ 2152120320 RRSAP_CshLgthAdjFdRr "Right Rear Seat Actuator Priority : Cushion Length Adjustment Forward/Rearward";
BA_ "VNSigAllNodes" SG_ 2152120320 RRSAP_CshLgthAdjFdRr 1;
BA_ "GenSigDeltaValue" SG_ 2152120320 RRSAP_BkCshBlstrInOut 1;
BA_ "GenSigSendType" SG_ 2152120320 RRSAP_BkCshBlstrInOut 12;
BA_ "GenSigSendOnInit" SG_ 2152120320 RRSAP_BkCshBlstrInOut 2;
BA_ "SignalType" SG_ 2152120320 RRSAP_BkCshBlstrInOut "UNM";
BA_ "PacketOrder" SG_ 2152120320 RRSAP_BkCshBlstrInOut 13;
BA_ "SignalLongName" SG_ 2152120320 RRSAP_BkCshBlstrInOut "Right Rear Seat Actuator Priority : Back and Cushion Bolster In/Out";
BA_ "VNSigAllNodes" SG_ 2152120320 RRSAP_BkCshBlstrInOut 1;
BA_ "GenSigDeltaValue" SG_ 2152120320 RRSAP_CshBlstrInOut 1;
BA_ "GenSigSendType" SG_ 2152120320 RRSAP_CshBlstrInOut 12;
BA_ "GenSigSendOnInit" SG_ 2152120320 RRSAP_CshBlstrInOut 2;
BA_ "SignalType" SG_ 2152120320 RRSAP_CshBlstrInOut "UNM";
BA_ "PacketOrder" SG_ 2152120320 RRSAP_CshBlstrInOut 12;
BA_ "SignalLongName" SG_ 2152120320 RRSAP_CshBlstrInOut "Right Rear Seat Actuator Priority : Cushion Bolster In/Out";
BA_ "VNSigAllNodes" SG_ 2152120320 RRSAP_CshBlstrInOut 1;
BA_ "GenSigDeltaValue" SG_ 2152120320 RRSAP_BkBlstrInOut 1;
BA_ "GenSigSendType" SG_ 2152120320 RRSAP_BkBlstrInOut 12;
BA_ "GenSigSendOnInit" SG_ 2152120320 RRSAP_BkBlstrInOut 2;
BA_ "SignalType" SG_ 2152120320 RRSAP_BkBlstrInOut "UNM";
BA_ "PacketOrder" SG_ 2152120320 RRSAP_BkBlstrInOut 11;
BA_ "SignalLongName" SG_ 2152120320 RRSAP_BkBlstrInOut "Right Rear Seat Actuator Priority : Back Bolster In/Out";
BA_ "VNSigAllNodes" SG_ 2152120320 RRSAP_BkBlstrInOut 1;
BA_ "GenSigDeltaValue" SG_ 2152120320 RRSAP_LmbrUpDnFdRr 1;
BA_ "GenSigSendType" SG_ 2152120320 RRSAP_LmbrUpDnFdRr 12;
BA_ "GenSigSendOnInit" SG_ 2152120320 RRSAP_LmbrUpDnFdRr 2;
BA_ "SignalType" SG_ 2152120320 RRSAP_LmbrUpDnFdRr "UNM";
BA_ "PacketOrder" SG_ 2152120320 RRSAP_LmbrUpDnFdRr 10;
BA_ "SignalLongName" SG_ 2152120320 RRSAP_LmbrUpDnFdRr "Right Rear Seat Actuator Priority : Lumbar Up/Down and Forward/Rearward";
BA_ "VNSigAllNodes" SG_ 2152120320 RRSAP_LmbrUpDnFdRr 1;
BA_ "GenSigDeltaValue" SG_ 2152120320 RRSAP_LmbrFwdRr 1;
BA_ "GenSigSendType" SG_ 2152120320 RRSAP_LmbrFwdRr 12;
BA_ "GenSigSendOnInit" SG_ 2152120320 RRSAP_LmbrFwdRr 2;
BA_ "SignalType" SG_ 2152120320 RRSAP_LmbrFwdRr "UNM";
BA_ "PacketOrder" SG_ 2152120320 RRSAP_LmbrFwdRr 9;
BA_ "SignalLongName" SG_ 2152120320 RRSAP_LmbrFwdRr "Right Rear Seat Actuator Priority : Lumbar Forward/Rearward";
BA_ "VNSigAllNodes" SG_ 2152120320 RRSAP_LmbrFwdRr 1;
BA_ "GenSigDeltaValue" SG_ 2152120320 RRSAP_LmbrUpDwn 1;
BA_ "GenSigSendType" SG_ 2152120320 RRSAP_LmbrUpDwn 12;
BA_ "GenSigSendOnInit" SG_ 2152120320 RRSAP_LmbrUpDwn 2;
BA_ "SignalType" SG_ 2152120320 RRSAP_LmbrUpDwn "UNM";
BA_ "PacketOrder" SG_ 2152120320 RRSAP_LmbrUpDwn 8;
BA_ "SignalLongName" SG_ 2152120320 RRSAP_LmbrUpDwn "Right Rear Seat Actuator Priority : Lumbar Up/Down";
BA_ "VNSigAllNodes" SG_ 2152120320 RRSAP_LmbrUpDwn 1;
BA_ "GenSigDeltaValue" SG_ 2152120320 RRSAP_UprShldrFwdRr 1;
BA_ "GenSigSendType" SG_ 2152120320 RRSAP_UprShldrFwdRr 12;
BA_ "GenSigSendOnInit" SG_ 2152120320 RRSAP_UprShldrFwdRr 2;
BA_ "SignalType" SG_ 2152120320 RRSAP_UprShldrFwdRr "UNM";
BA_ "PacketOrder" SG_ 2152120320 RRSAP_UprShldrFwdRr 7;
BA_ "SignalLongName" SG_ 2152120320 RRSAP_UprShldrFwdRr "Right Rear Seat Actuator Priority : Upper Shoulder Forward/Rearward";
BA_ "VNSigAllNodes" SG_ 2152120320 RRSAP_UprShldrFwdRr 1;
BA_ "GenSigDeltaValue" SG_ 2152120320 RRSAP_HdrstTltFwdRr 1;
BA_ "GenSigSendType" SG_ 2152120320 RRSAP_HdrstTltFwdRr 12;
BA_ "GenSigSendOnInit" SG_ 2152120320 RRSAP_HdrstTltFwdRr 2;
BA_ "SignalType" SG_ 2152120320 RRSAP_HdrstTltFwdRr "UNM";
BA_ "PacketOrder" SG_ 2152120320 RRSAP_HdrstTltFwdRr 6;
BA_ "SignalLongName" SG_ 2152120320 RRSAP_HdrstTltFwdRr "Right Rear Seat Actuator Priority : Headrest Tilt Forward/Rearward";
BA_ "VNSigAllNodes" SG_ 2152120320 RRSAP_HdrstTltFwdRr 1;
BA_ "GenSigDeltaValue" SG_ 2152120320 RRSAP_HdrstWngsInOut 1;
BA_ "GenSigSendType" SG_ 2152120320 RRSAP_HdrstWngsInOut 12;
BA_ "GenSigSendOnInit" SG_ 2152120320 RRSAP_HdrstWngsInOut 2;
BA_ "SignalType" SG_ 2152120320 RRSAP_HdrstWngsInOut "UNM";
BA_ "PacketOrder" SG_ 2152120320 RRSAP_HdrstWngsInOut 5;
BA_ "SignalLongName" SG_ 2152120320 RRSAP_HdrstWngsInOut "Right Rear Seat Actuator Priority : Headrest Wings Inward/Outward";
BA_ "VNSigAllNodes" SG_ 2152120320 RRSAP_HdrstWngsInOut 1;
BA_ "GenSigDeltaValue" SG_ 2152120320 RRSAP_HdrstUpDnFdRr 1;
BA_ "GenSigSendType" SG_ 2152120320 RRSAP_HdrstUpDnFdRr 12;
BA_ "GenSigSendOnInit" SG_ 2152120320 RRSAP_HdrstUpDnFdRr 2;
BA_ "SignalType" SG_ 2152120320 RRSAP_HdrstUpDnFdRr "UNM";
BA_ "PacketOrder" SG_ 2152120320 RRSAP_HdrstUpDnFdRr 4;
BA_ "SignalLongName" SG_ 2152120320 RRSAP_HdrstUpDnFdRr "Right Rear Seat Actuator Priority : Headrest Up/Down and Forward/Rearward";
BA_ "VNSigAllNodes" SG_ 2152120320 RRSAP_HdrstUpDnFdRr 1;
BA_ "GenSigDeltaValue" SG_ 2152120320 RRSAP_HdrstFwdRrwd 1;
BA_ "GenSigSendType" SG_ 2152120320 RRSAP_HdrstFwdRrwd 12;
BA_ "GenSigSendOnInit" SG_ 2152120320 RRSAP_HdrstFwdRrwd 2;
BA_ "SignalType" SG_ 2152120320 RRSAP_HdrstFwdRrwd "UNM";
BA_ "PacketOrder" SG_ 2152120320 RRSAP_HdrstFwdRrwd 3;
BA_ "SignalLongName" SG_ 2152120320 RRSAP_HdrstFwdRrwd "Right Rear Seat Actuator Priority : Headrest Forward/Rearward";
BA_ "VNSigAllNodes" SG_ 2152120320 RRSAP_HdrstFwdRrwd 1;
BA_ "GenSigDeltaValue" SG_ 2152120320 RRSAP_HdrstUpDn 1;
BA_ "GenSigSendType" SG_ 2152120320 RRSAP_HdrstUpDn 12;
BA_ "GenSigSendOnInit" SG_ 2152120320 RRSAP_HdrstUpDn 2;
BA_ "SignalType" SG_ 2152120320 RRSAP_HdrstUpDn "UNM";
BA_ "PacketOrder" SG_ 2152120320 RRSAP_HdrstUpDn 2;
BA_ "SignalLongName" SG_ 2152120320 RRSAP_HdrstUpDn "Right Rear Seat Actuator Priority : Headrest Up/Down";
BA_ "VNSigAllNodes" SG_ 2152120320 RRSAP_HdrstUpDn 1;
BA_ "GenSigDeltaValue" SG_ 2152120320 RRSAP_Massg 1;
BA_ "GenSigSendType" SG_ 2152120320 RRSAP_Massg 12;
BA_ "GenSigSendOnInit" SG_ 2152120320 RRSAP_Massg 2;
BA_ "SignalType" SG_ 2152120320 RRSAP_Massg "UNM";
BA_ "PacketOrder" SG_ 2152120320 RRSAP_Massg 1;
BA_ "SignalLongName" SG_ 2152120320 RRSAP_Massg "Right Rear Seat Actuator Priority : Massage";
BA_ "VNSigAllNodes" SG_ 2152120320 RRSAP_Massg 1;
BA_ "GenSigDeltaValue" SG_ 2152103936 LRSCDS_UnsdRsrvd 1;
BA_ "GenSigSendType" SG_ 2152103936 LRSCDS_UnsdRsrvd 12;
BA_ "SignalType" SG_ 2152103936 LRSCDS_UnsdRsrvd "UNM";
BA_ "PacketOrder" SG_ 2152103936 LRSCDS_UnsdRsrvd 19;
BA_ "SignalLongName" SG_ 2152103936 LRSCDS_UnsdRsrvd "Left Rear Seat Control Display Status : Unused and Reserved";
BA_ "VNSigAllNodes" SG_ 2152103936 LRSCDS_UnsdRsrvd 1;
BA_ "GenSigSendType" SG_ 2152103936 LRSCDS_DispReq 10;
BA_ "SignalType" SG_ 2152103936 LRSCDS_DispReq "BLN";
BA_ "PacketOrder" SG_ 2152103936 LRSCDS_DispReq 18;
BA_ "SignalLongName" SG_ 2152103936 LRSCDS_DispReq "Left Rear Seat Control Display Status : Display Request";
BA_ "VNSigAllNodes" SG_ 2152103936 LRSCDS_DispReq 1;
BA_ "GenSigSendType" SG_ 2152103936 LRSCDS_DispSz 10;
BA_ "SignalType" SG_ 2152103936 LRSCDS_DispSz "ENM";
BA_ "PacketOrder" SG_ 2152103936 LRSCDS_DispSz 17;
BA_ "SignalLongName" SG_ 2152103936 LRSCDS_DispSz "Left Rear Seat Control Display Status : Display Size";
BA_ "VNSigAllNodes" SG_ 2152103936 LRSCDS_DispSz 1;
BA_ "GenSigSendType" SG_ 2152103936 LRSCDS_CshLgAdjFdRr 10;
BA_ "SignalType" SG_ 2152103936 LRSCDS_CshLgAdjFdRr "ENM";
BA_ "PacketOrder" SG_ 2152103936 LRSCDS_CshLgAdjFdRr 16;
BA_ "SignalLongName" SG_ 2152103936 LRSCDS_CshLgAdjFdRr "Left Rear Seat Control Display Status : Cushion Length Adjustment Forward/Rearward";
BA_ "VNSigAllNodes" SG_ 2152103936 LRSCDS_CshLgAdjFdRr 1;
BA_ "GenSigSendType" SG_ 2152103936 LRSCDS_BkCshBlstInOt 10;
BA_ "SignalType" SG_ 2152103936 LRSCDS_BkCshBlstInOt "ENM";
BA_ "PacketOrder" SG_ 2152103936 LRSCDS_BkCshBlstInOt 15;
BA_ "SignalLongName" SG_ 2152103936 LRSCDS_BkCshBlstInOt "Left Rear Seat Control Display Status : Back and Cushion Bolster In/Out";
BA_ "VNSigAllNodes" SG_ 2152103936 LRSCDS_BkCshBlstInOt 1;
BA_ "GenSigSendType" SG_ 2152103936 LRSCDS_CshBlstrInOut 10;
BA_ "SignalType" SG_ 2152103936 LRSCDS_CshBlstrInOut "ENM";
BA_ "PacketOrder" SG_ 2152103936 LRSCDS_CshBlstrInOut 14;
BA_ "SignalLongName" SG_ 2152103936 LRSCDS_CshBlstrInOut "Left Rear Seat Control Display Status : Cushion Bolster In/Out";
BA_ "VNSigAllNodes" SG_ 2152103936 LRSCDS_CshBlstrInOut 1;
BA_ "GenSigSendType" SG_ 2152103936 LRSCDS_BkBlstrInOut 10;
BA_ "SignalType" SG_ 2152103936 LRSCDS_BkBlstrInOut "ENM";
BA_ "PacketOrder" SG_ 2152103936 LRSCDS_BkBlstrInOut 13;
BA_ "SignalLongName" SG_ 2152103936 LRSCDS_BkBlstrInOut "Left Rear Seat Control Display Status : Back Bolster In/Out";
BA_ "VNSigAllNodes" SG_ 2152103936 LRSCDS_BkBlstrInOut 1;
BA_ "GenSigSendType" SG_ 2152103936 LRSCDS_LmbrUDnFdRr 10;
BA_ "SignalType" SG_ 2152103936 LRSCDS_LmbrUDnFdRr "ENM";
BA_ "PacketOrder" SG_ 2152103936 LRSCDS_LmbrUDnFdRr 12;
BA_ "SignalLongName" SG_ 2152103936 LRSCDS_LmbrUDnFdRr "Left Rear Seat Control Display Status : Lumbar Up/Down and Forward/Rearward";
BA_ "VNSigAllNodes" SG_ 2152103936 LRSCDS_LmbrUDnFdRr 1;
BA_ "GenSigSendType" SG_ 2152103936 LRSCDS_LmbrFwdRr 10;
BA_ "SignalType" SG_ 2152103936 LRSCDS_LmbrFwdRr "ENM";
BA_ "PacketOrder" SG_ 2152103936 LRSCDS_LmbrFwdRr 11;
BA_ "SignalLongName" SG_ 2152103936 LRSCDS_LmbrFwdRr "Left Rear Seat Control Display Status : Lumbar Forward/Rearward";
BA_ "VNSigAllNodes" SG_ 2152103936 LRSCDS_LmbrFwdRr 1;
BA_ "GenSigSendType" SG_ 2152103936 LRSCDS_LmbrUpDwn 10;
BA_ "SignalType" SG_ 2152103936 LRSCDS_LmbrUpDwn "ENM";
BA_ "PacketOrder" SG_ 2152103936 LRSCDS_LmbrUpDwn 10;
BA_ "SignalLongName" SG_ 2152103936 LRSCDS_LmbrUpDwn "Left Rear Seat Control Display Status : Lumbar Up/Down";
BA_ "VNSigAllNodes" SG_ 2152103936 LRSCDS_LmbrUpDwn 1;
BA_ "GenSigSendType" SG_ 2152103936 LRSCDS_UprShldrFdRr 10;
BA_ "SignalType" SG_ 2152103936 LRSCDS_UprShldrFdRr "ENM";
BA_ "PacketOrder" SG_ 2152103936 LRSCDS_UprShldrFdRr 9;
BA_ "SignalLongName" SG_ 2152103936 LRSCDS_UprShldrFdRr "Left Rear Seat Control Display Status : Upper Shoulder Forward/Rearward";
BA_ "VNSigAllNodes" SG_ 2152103936 LRSCDS_UprShldrFdRr 1;
BA_ "GenSigSendType" SG_ 2152103936 LRSCDS_HdrstTltFwdRr 10;
BA_ "SignalType" SG_ 2152103936 LRSCDS_HdrstTltFwdRr "ENM";
BA_ "PacketOrder" SG_ 2152103936 LRSCDS_HdrstTltFwdRr 8;
BA_ "SignalLongName" SG_ 2152103936 LRSCDS_HdrstTltFwdRr "Left Rear Seat Control Display Status : Headrest Tilt Forward/Rearward";
BA_ "VNSigAllNodes" SG_ 2152103936 LRSCDS_HdrstTltFwdRr 1;
BA_ "GenSigSendType" SG_ 2152103936 LRSCDS_HdrstWngInOt 10;
BA_ "SignalType" SG_ 2152103936 LRSCDS_HdrstWngInOt "ENM";
BA_ "PacketOrder" SG_ 2152103936 LRSCDS_HdrstWngInOt 7;
BA_ "SignalLongName" SG_ 2152103936 LRSCDS_HdrstWngInOt "Left Rear Seat Control Display Status : Headrest Wings In/Out";
BA_ "VNSigAllNodes" SG_ 2152103936 LRSCDS_HdrstWngInOt 1;
BA_ "GenSigSendType" SG_ 2152103936 LRSCDS_HdrstFdRrUDn 10;
BA_ "SignalType" SG_ 2152103936 LRSCDS_HdrstFdRrUDn "ENM";
BA_ "PacketOrder" SG_ 2152103936 LRSCDS_HdrstFdRrUDn 6;
BA_ "SignalLongName" SG_ 2152103936 LRSCDS_HdrstFdRrUDn "Left Rear Seat Control Display Status : Headrest Forward/Rearward and Up/Down";
BA_ "VNSigAllNodes" SG_ 2152103936 LRSCDS_HdrstFdRrUDn 1;
BA_ "GenSigSendType" SG_ 2152103936 LRSCDS_HdrstFwdRrwd 10;
BA_ "SignalType" SG_ 2152103936 LRSCDS_HdrstFwdRrwd "ENM";
BA_ "PacketOrder" SG_ 2152103936 LRSCDS_HdrstFwdRrwd 5;
BA_ "SignalLongName" SG_ 2152103936 LRSCDS_HdrstFwdRrwd "Left Rear Seat Control Display Status : Headrest Forward/Rearward";
BA_ "VNSigAllNodes" SG_ 2152103936 LRSCDS_HdrstFwdRrwd 1;
BA_ "GenSigSendType" SG_ 2152103936 LRSCDS_HdrstUpDn 10;
BA_ "SignalType" SG_ 2152103936 LRSCDS_HdrstUpDn "ENM";
BA_ "PacketOrder" SG_ 2152103936 LRSCDS_HdrstUpDn 4;
BA_ "SignalLongName" SG_ 2152103936 LRSCDS_HdrstUpDn "Left Rear Seat Control Display Status : Headrest Up/Down";
BA_ "VNSigAllNodes" SG_ 2152103936 LRSCDS_HdrstUpDn 1;
BA_ "GenSigSendType" SG_ 2152103936 LRSCDS_MassgIntsty 10;
BA_ "SignalType" SG_ 2152103936 LRSCDS_MassgIntsty "ENM";
BA_ "PacketOrder" SG_ 2152103936 LRSCDS_MassgIntsty 3;
BA_ "SignalLongName" SG_ 2152103936 LRSCDS_MassgIntsty "Left Rear Seat Control Display Status : Massage Intensity";
BA_ "VNSigAllNodes" SG_ 2152103936 LRSCDS_MassgIntsty 1;
BA_ "GenSigSendType" SG_ 2152103936 LRSCDS_MassgTyp 10;
BA_ "SignalType" SG_ 2152103936 LRSCDS_MassgTyp "ENM";
BA_ "PacketOrder" SG_ 2152103936 LRSCDS_MassgTyp 2;
BA_ "SignalLongName" SG_ 2152103936 LRSCDS_MassgTyp "Left Rear Seat Control Display Status : Massage Type";
BA_ "VNSigAllNodes" SG_ 2152103936 LRSCDS_MassgTyp 1;
BA_ "GenSigSendType" SG_ 2152103936 LRSCDS_Massg 10;
BA_ "SignalType" SG_ 2152103936 LRSCDS_Massg "ENM";
BA_ "PacketOrder" SG_ 2152103936 LRSCDS_Massg 1;
BA_ "SignalLongName" SG_ 2152103936 LRSCDS_Massg "Left Rear Seat Control Display Status : Massage";
BA_ "VNSigAllNodes" SG_ 2152103936 LRSCDS_Massg 1;
BA_ "GenSigSendType" SG_ 2152087552 LRSMP_UnsdRsrvd 10;
BA_ "GenSigSendOnInit" SG_ 2152087552 LRSMP_UnsdRsrvd 2;
BA_ "SignalType" SG_ 2152087552 LRSMP_UnsdRsrvd "BLN";
BA_ "PacketOrder" SG_ 2152087552 LRSMP_UnsdRsrvd 17;
BA_ "SignalLongName" SG_ 2152087552 LRSMP_UnsdRsrvd "Left Rear Seat Massage Priority : Unused and Reserved";
BA_ "VNSigAllNodes" SG_ 2152087552 LRSMP_UnsdRsrvd 1;
BA_ "GenSigDeltaValue" SG_ 2152087552 LRSMP_MaxDispVal 1;
BA_ "GenSigSendType" SG_ 2152087552 LRSMP_MaxDispVal 12;
BA_ "GenSigSendOnInit" SG_ 2152087552 LRSMP_MaxDispVal 2;
BA_ "SignalType" SG_ 2152087552 LRSMP_MaxDispVal "UNM";
BA_ "PacketOrder" SG_ 2152087552 LRSMP_MaxDispVal 16;
BA_ "SignalLongName" SG_ 2152087552 LRSMP_MaxDispVal "Left Rear Seat Massage Priority : Maximum Display Value";
BA_ "VNSigAllNodes" SG_ 2152087552 LRSMP_MaxDispVal 1;
BA_ "GenSigDeltaValue" SG_ 2152087552 LRSMP_Type15 1;
BA_ "GenSigSendType" SG_ 2152087552 LRSMP_Type15 12;
BA_ "GenSigSendOnInit" SG_ 2152087552 LRSMP_Type15 2;
BA_ "SignalType" SG_ 2152087552 LRSMP_Type15 "UNM";
BA_ "PacketOrder" SG_ 2152087552 LRSMP_Type15 15;
BA_ "SignalLongName" SG_ 2152087552 LRSMP_Type15 "Left Rear Seat Massage Priority : Type 15";
BA_ "VNSigAllNodes" SG_ 2152087552 LRSMP_Type15 1;
BA_ "GenSigDeltaValue" SG_ 2152087552 LRSMP_Type14 1;
BA_ "GenSigSendType" SG_ 2152087552 LRSMP_Type14 12;
BA_ "GenSigSendOnInit" SG_ 2152087552 LRSMP_Type14 2;
BA_ "SignalType" SG_ 2152087552 LRSMP_Type14 "UNM";
BA_ "PacketOrder" SG_ 2152087552 LRSMP_Type14 14;
BA_ "SignalLongName" SG_ 2152087552 LRSMP_Type14 "Left Rear Seat Massage Priority : Type 14";
BA_ "VNSigAllNodes" SG_ 2152087552 LRSMP_Type14 1;
BA_ "GenSigDeltaValue" SG_ 2152087552 LRSMP_Type13 1;
BA_ "GenSigSendType" SG_ 2152087552 LRSMP_Type13 12;
BA_ "GenSigSendOnInit" SG_ 2152087552 LRSMP_Type13 2;
BA_ "SignalType" SG_ 2152087552 LRSMP_Type13 "UNM";
BA_ "PacketOrder" SG_ 2152087552 LRSMP_Type13 13;
BA_ "SignalLongName" SG_ 2152087552 LRSMP_Type13 "Left Rear Seat Massage Priority : Type 13";
BA_ "VNSigAllNodes" SG_ 2152087552 LRSMP_Type13 1;
BA_ "GenSigDeltaValue" SG_ 2152087552 LRSMP_Type12 1;
BA_ "GenSigSendType" SG_ 2152087552 LRSMP_Type12 12;
BA_ "GenSigSendOnInit" SG_ 2152087552 LRSMP_Type12 2;
BA_ "SignalType" SG_ 2152087552 LRSMP_Type12 "UNM";
BA_ "PacketOrder" SG_ 2152087552 LRSMP_Type12 12;
BA_ "SignalLongName" SG_ 2152087552 LRSMP_Type12 "Left Rear Seat Massage Priority : Type 12";
BA_ "VNSigAllNodes" SG_ 2152087552 LRSMP_Type12 1;
BA_ "GenSigDeltaValue" SG_ 2152087552 LRSMP_Type11 1;
BA_ "GenSigSendType" SG_ 2152087552 LRSMP_Type11 12;
BA_ "GenSigSendOnInit" SG_ 2152087552 LRSMP_Type11 2;
BA_ "SignalType" SG_ 2152087552 LRSMP_Type11 "UNM";
BA_ "PacketOrder" SG_ 2152087552 LRSMP_Type11 11;
BA_ "SignalLongName" SG_ 2152087552 LRSMP_Type11 "Left Rear Seat Massage Priority : Type 11";
BA_ "VNSigAllNodes" SG_ 2152087552 LRSMP_Type11 1;
BA_ "GenSigDeltaValue" SG_ 2152087552 LRSMP_Type10 1;
BA_ "GenSigSendType" SG_ 2152087552 LRSMP_Type10 12;
BA_ "GenSigSendOnInit" SG_ 2152087552 LRSMP_Type10 2;
BA_ "SignalType" SG_ 2152087552 LRSMP_Type10 "UNM";
BA_ "PacketOrder" SG_ 2152087552 LRSMP_Type10 10;
BA_ "SignalLongName" SG_ 2152087552 LRSMP_Type10 "Left Rear Seat Massage Priority : Type 10";
BA_ "VNSigAllNodes" SG_ 2152087552 LRSMP_Type10 1;
BA_ "GenSigDeltaValue" SG_ 2152087552 LRSMP_Type9 1;
BA_ "GenSigSendType" SG_ 2152087552 LRSMP_Type9 12;
BA_ "GenSigSendOnInit" SG_ 2152087552 LRSMP_Type9 2;
BA_ "SignalType" SG_ 2152087552 LRSMP_Type9 "UNM";
BA_ "PacketOrder" SG_ 2152087552 LRSMP_Type9 9;
BA_ "SignalLongName" SG_ 2152087552 LRSMP_Type9 "Left Rear Seat Massage Priority : Type 9";
BA_ "VNSigAllNodes" SG_ 2152087552 LRSMP_Type9 1;
BA_ "GenSigDeltaValue" SG_ 2152087552 LRSMP_Type8 1;
BA_ "GenSigSendType" SG_ 2152087552 LRSMP_Type8 12;
BA_ "GenSigSendOnInit" SG_ 2152087552 LRSMP_Type8 2;
BA_ "SignalType" SG_ 2152087552 LRSMP_Type8 "UNM";
BA_ "PacketOrder" SG_ 2152087552 LRSMP_Type8 8;
BA_ "SignalLongName" SG_ 2152087552 LRSMP_Type8 "Left Rear Seat Massage Priority : Type 8";
BA_ "VNSigAllNodes" SG_ 2152087552 LRSMP_Type8 1;
BA_ "GenSigDeltaValue" SG_ 2152087552 LRSMP_Type7 1;
BA_ "GenSigSendType" SG_ 2152087552 LRSMP_Type7 12;
BA_ "GenSigSendOnInit" SG_ 2152087552 LRSMP_Type7 2;
BA_ "SignalType" SG_ 2152087552 LRSMP_Type7 "UNM";
BA_ "PacketOrder" SG_ 2152087552 LRSMP_Type7 7;
BA_ "SignalLongName" SG_ 2152087552 LRSMP_Type7 "Left Rear Seat Massage Priority : Type 7";
BA_ "VNSigAllNodes" SG_ 2152087552 LRSMP_Type7 1;
BA_ "GenSigDeltaValue" SG_ 2152087552 LRSMP_Type6 1;
BA_ "GenSigSendType" SG_ 2152087552 LRSMP_Type6 12;
BA_ "GenSigSendOnInit" SG_ 2152087552 LRSMP_Type6 2;
BA_ "SignalType" SG_ 2152087552 LRSMP_Type6 "UNM";
BA_ "PacketOrder" SG_ 2152087552 LRSMP_Type6 6;
BA_ "SignalLongName" SG_ 2152087552 LRSMP_Type6 "Left Rear Seat Massage Priority : Type 6";
BA_ "VNSigAllNodes" SG_ 2152087552 LRSMP_Type6 1;
BA_ "GenSigDeltaValue" SG_ 2152087552 LRSMP_Type5 1;
BA_ "GenSigSendType" SG_ 2152087552 LRSMP_Type5 12;
BA_ "GenSigSendOnInit" SG_ 2152087552 LRSMP_Type5 2;
BA_ "SignalType" SG_ 2152087552 LRSMP_Type5 "UNM";
BA_ "PacketOrder" SG_ 2152087552 LRSMP_Type5 5;
BA_ "SignalLongName" SG_ 2152087552 LRSMP_Type5 "Left Rear Seat Massage Priority : Type 5";
BA_ "VNSigAllNodes" SG_ 2152087552 LRSMP_Type5 1;
BA_ "GenSigDeltaValue" SG_ 2152087552 LRSMP_Type4 1;
BA_ "GenSigSendType" SG_ 2152087552 LRSMP_Type4 12;
BA_ "GenSigSendOnInit" SG_ 2152087552 LRSMP_Type4 2;
BA_ "SignalType" SG_ 2152087552 LRSMP_Type4 "UNM";
BA_ "PacketOrder" SG_ 2152087552 LRSMP_Type4 4;
BA_ "SignalLongName" SG_ 2152087552 LRSMP_Type4 "Left Rear Seat Massage Priority : Type 4";
BA_ "VNSigAllNodes" SG_ 2152087552 LRSMP_Type4 1;
BA_ "GenSigDeltaValue" SG_ 2152087552 LRSMP_Type3 1;
BA_ "GenSigSendType" SG_ 2152087552 LRSMP_Type3 12;
BA_ "GenSigSendOnInit" SG_ 2152087552 LRSMP_Type3 2;
BA_ "SignalType" SG_ 2152087552 LRSMP_Type3 "UNM";
BA_ "PacketOrder" SG_ 2152087552 LRSMP_Type3 3;
BA_ "SignalLongName" SG_ 2152087552 LRSMP_Type3 "Left Rear Seat Massage Priority : Type 3";
BA_ "VNSigAllNodes" SG_ 2152087552 LRSMP_Type3 1;
BA_ "GenSigDeltaValue" SG_ 2152087552 LRSMP_Type2 1;
BA_ "GenSigSendType" SG_ 2152087552 LRSMP_Type2 12;
BA_ "GenSigSendOnInit" SG_ 2152087552 LRSMP_Type2 2;
BA_ "SignalType" SG_ 2152087552 LRSMP_Type2 "UNM";
BA_ "PacketOrder" SG_ 2152087552 LRSMP_Type2 2;
BA_ "SignalLongName" SG_ 2152087552 LRSMP_Type2 "Left Rear Seat Massage Priority : Type 2";
BA_ "VNSigAllNodes" SG_ 2152087552 LRSMP_Type2 1;
BA_ "GenSigDeltaValue" SG_ 2152087552 LRSMP_Type1 1;
BA_ "GenSigSendType" SG_ 2152087552 LRSMP_Type1 12;
BA_ "GenSigSendOnInit" SG_ 2152087552 LRSMP_Type1 2;
BA_ "SignalType" SG_ 2152087552 LRSMP_Type1 "UNM";
BA_ "PacketOrder" SG_ 2152087552 LRSMP_Type1 1;
BA_ "SignalLongName" SG_ 2152087552 LRSMP_Type1 "Left Rear Seat Massage Priority : Type 1";
BA_ "VNSigAllNodes" SG_ 2152087552 LRSMP_Type1 1;
BA_ "GenSigDeltaValue" SG_ 2152071168 LRSAP_UnsdRsrvd 1;
BA_ "GenSigSendType" SG_ 2152071168 LRSAP_UnsdRsrvd 12;
BA_ "GenSigSendOnInit" SG_ 2152071168 LRSAP_UnsdRsrvd 2;
BA_ "SignalType" SG_ 2152071168 LRSAP_UnsdRsrvd "UNM";
BA_ "PacketOrder" SG_ 2152071168 LRSAP_UnsdRsrvd 16;
BA_ "SignalLongName" SG_ 2152071168 LRSAP_UnsdRsrvd "Left Rear Seat Actuator Priority : Unused and Reserved";
BA_ "VNSigAllNodes" SG_ 2152071168 LRSAP_UnsdRsrvd 1;
BA_ "GenSigDeltaValue" SG_ 2152071168 LRSAP_DispSz 1;
BA_ "GenSigSendType" SG_ 2152071168 LRSAP_DispSz 12;
BA_ "GenSigSendOnInit" SG_ 2152071168 LRSAP_DispSz 2;
BA_ "SignalType" SG_ 2152071168 LRSAP_DispSz "UNM";
BA_ "PacketOrder" SG_ 2152071168 LRSAP_DispSz 15;
BA_ "SignalLongName" SG_ 2152071168 LRSAP_DispSz "Left Rear Seat Actuator Priority : Display Size";
BA_ "VNSigAllNodes" SG_ 2152071168 LRSAP_DispSz 1;
BA_ "GenSigDeltaValue" SG_ 2152071168 LRSAP_CshLgthAdjFdRr 1;
BA_ "GenSigSendType" SG_ 2152071168 LRSAP_CshLgthAdjFdRr 12;
BA_ "GenSigSendOnInit" SG_ 2152071168 LRSAP_CshLgthAdjFdRr 2;
BA_ "SignalType" SG_ 2152071168 LRSAP_CshLgthAdjFdRr "UNM";
BA_ "PacketOrder" SG_ 2152071168 LRSAP_CshLgthAdjFdRr 14;
BA_ "SignalLongName" SG_ 2152071168 LRSAP_CshLgthAdjFdRr "Left Rear Seat Actuator Priority : Cushion Length Adjustment Forward/Rearward";
BA_ "VNSigAllNodes" SG_ 2152071168 LRSAP_CshLgthAdjFdRr 1;
BA_ "GenSigDeltaValue" SG_ 2152071168 LRSAP_BkCshBlstrInOut 1;
BA_ "GenSigSendType" SG_ 2152071168 LRSAP_BkCshBlstrInOut 12;
BA_ "GenSigSendOnInit" SG_ 2152071168 LRSAP_BkCshBlstrInOut 2;
BA_ "SignalType" SG_ 2152071168 LRSAP_BkCshBlstrInOut "UNM";
BA_ "PacketOrder" SG_ 2152071168 LRSAP_BkCshBlstrInOut 13;
BA_ "SignalLongName" SG_ 2152071168 LRSAP_BkCshBlstrInOut "Left Rear Seat Actuator Priority : Back and Cushion Bolster In/Out";
BA_ "VNSigAllNodes" SG_ 2152071168 LRSAP_BkCshBlstrInOut 1;
BA_ "GenSigDeltaValue" SG_ 2152071168 LRSAP_CshBlstrInOut 1;
BA_ "GenSigSendType" SG_ 2152071168 LRSAP_CshBlstrInOut 12;
BA_ "GenSigSendOnInit" SG_ 2152071168 LRSAP_CshBlstrInOut 2;
BA_ "SignalType" SG_ 2152071168 LRSAP_CshBlstrInOut "UNM";
BA_ "PacketOrder" SG_ 2152071168 LRSAP_CshBlstrInOut 12;
BA_ "SignalLongName" SG_ 2152071168 LRSAP_CshBlstrInOut "Left Rear Seat Actuator Priority : Cushion Bolster In/Out";
BA_ "VNSigAllNodes" SG_ 2152071168 LRSAP_CshBlstrInOut 1;
BA_ "GenSigDeltaValue" SG_ 2152071168 LRSAP_BkBlstrInOut 1;
BA_ "GenSigSendType" SG_ 2152071168 LRSAP_BkBlstrInOut 12;
BA_ "GenSigSendOnInit" SG_ 2152071168 LRSAP_BkBlstrInOut 2;
BA_ "SignalType" SG_ 2152071168 LRSAP_BkBlstrInOut "UNM";
BA_ "PacketOrder" SG_ 2152071168 LRSAP_BkBlstrInOut 11;
BA_ "SignalLongName" SG_ 2152071168 LRSAP_BkBlstrInOut "Left Rear Seat Actuator Priority : Back Bolster In/Out";
BA_ "VNSigAllNodes" SG_ 2152071168 LRSAP_BkBlstrInOut 1;
BA_ "GenSigDeltaValue" SG_ 2152071168 LRSAP_LmbrUpDnFdRr 1;
BA_ "GenSigSendType" SG_ 2152071168 LRSAP_LmbrUpDnFdRr 12;
BA_ "GenSigSendOnInit" SG_ 2152071168 LRSAP_LmbrUpDnFdRr 2;
BA_ "SignalType" SG_ 2152071168 LRSAP_LmbrUpDnFdRr "UNM";
BA_ "PacketOrder" SG_ 2152071168 LRSAP_LmbrUpDnFdRr 10;
BA_ "SignalLongName" SG_ 2152071168 LRSAP_LmbrUpDnFdRr "Left Rear Seat Actuator Priority : Lumbar Up/Down and Forward/Rearward";
BA_ "VNSigAllNodes" SG_ 2152071168 LRSAP_LmbrUpDnFdRr 1;
BA_ "GenSigDeltaValue" SG_ 2152071168 LRSAP_LmbrFwdRr 1;
BA_ "GenSigSendType" SG_ 2152071168 LRSAP_LmbrFwdRr 12;
BA_ "GenSigSendOnInit" SG_ 2152071168 LRSAP_LmbrFwdRr 2;
BA_ "SignalType" SG_ 2152071168 LRSAP_LmbrFwdRr "UNM";
BA_ "PacketOrder" SG_ 2152071168 LRSAP_LmbrFwdRr 9;
BA_ "SignalLongName" SG_ 2152071168 LRSAP_LmbrFwdRr "Left Rear Seat Actuator Priority : Lumbar Forward/Rearward";
BA_ "VNSigAllNodes" SG_ 2152071168 LRSAP_LmbrFwdRr 1;
BA_ "GenSigDeltaValue" SG_ 2152071168 LRSAP_LmbrUpDwn 1;
BA_ "GenSigSendType" SG_ 2152071168 LRSAP_LmbrUpDwn 12;
BA_ "GenSigSendOnInit" SG_ 2152071168 LRSAP_LmbrUpDwn 2;
BA_ "SignalType" SG_ 2152071168 LRSAP_LmbrUpDwn "UNM";
BA_ "PacketOrder" SG_ 2152071168 LRSAP_LmbrUpDwn 8;
BA_ "SignalLongName" SG_ 2152071168 LRSAP_LmbrUpDwn "Left Rear Seat Actuator Priority : Lumbar Up/Down";
BA_ "VNSigAllNodes" SG_ 2152071168 LRSAP_LmbrUpDwn 1;
BA_ "GenSigDeltaValue" SG_ 2152071168 LRSAP_UprShldrFwdRr 1;
BA_ "GenSigSendType" SG_ 2152071168 LRSAP_UprShldrFwdRr 12;
BA_ "GenSigSendOnInit" SG_ 2152071168 LRSAP_UprShldrFwdRr 2;
BA_ "SignalType" SG_ 2152071168 LRSAP_UprShldrFwdRr "UNM";
BA_ "PacketOrder" SG_ 2152071168 LRSAP_UprShldrFwdRr 7;
BA_ "SignalLongName" SG_ 2152071168 LRSAP_UprShldrFwdRr "Left Rear Seat Actuator Priority : Upper Shoulder Forward/Rearward";
BA_ "VNSigAllNodes" SG_ 2152071168 LRSAP_UprShldrFwdRr 1;
BA_ "GenSigDeltaValue" SG_ 2152071168 LRSAP_HdrstTltFwdRr 1;
BA_ "GenSigSendType" SG_ 2152071168 LRSAP_HdrstTltFwdRr 12;
BA_ "GenSigSendOnInit" SG_ 2152071168 LRSAP_HdrstTltFwdRr 2;
BA_ "SignalType" SG_ 2152071168 LRSAP_HdrstTltFwdRr "UNM";
BA_ "PacketOrder" SG_ 2152071168 LRSAP_HdrstTltFwdRr 6;
BA_ "SignalLongName" SG_ 2152071168 LRSAP_HdrstTltFwdRr "Left Rear Seat Actuator Priority : Headrest Tilt Forward/Rearward";
BA_ "VNSigAllNodes" SG_ 2152071168 LRSAP_HdrstTltFwdRr 1;
BA_ "GenSigDeltaValue" SG_ 2152071168 LRSAP_HdrstWngsInOut 1;
BA_ "GenSigSendType" SG_ 2152071168 LRSAP_HdrstWngsInOut 12;
BA_ "GenSigSendOnInit" SG_ 2152071168 LRSAP_HdrstWngsInOut 2;
BA_ "SignalType" SG_ 2152071168 LRSAP_HdrstWngsInOut "UNM";
BA_ "PacketOrder" SG_ 2152071168 LRSAP_HdrstWngsInOut 5;
BA_ "SignalLongName" SG_ 2152071168 LRSAP_HdrstWngsInOut "Left Rear Seat Actuator Priority : Headrest Wings Inward/Outward";
BA_ "VNSigAllNodes" SG_ 2152071168 LRSAP_HdrstWngsInOut 1;
BA_ "GenSigDeltaValue" SG_ 2152071168 LRSAP_HdrstUpDnFdRr 1;
BA_ "GenSigSendType" SG_ 2152071168 LRSAP_HdrstUpDnFdRr 12;
BA_ "GenSigSendOnInit" SG_ 2152071168 LRSAP_HdrstUpDnFdRr 2;
BA_ "SignalType" SG_ 2152071168 LRSAP_HdrstUpDnFdRr "UNM";
BA_ "PacketOrder" SG_ 2152071168 LRSAP_HdrstUpDnFdRr 4;
BA_ "SignalLongName" SG_ 2152071168 LRSAP_HdrstUpDnFdRr "Left Rear Seat Actuator Priority : Headrest Up/Down and Forward/Rearward";
BA_ "VNSigAllNodes" SG_ 2152071168 LRSAP_HdrstUpDnFdRr 1;
BA_ "GenSigDeltaValue" SG_ 2152071168 LRSAP_HdrstFwdRrwd 1;
BA_ "GenSigSendType" SG_ 2152071168 LRSAP_HdrstFwdRrwd 12;
BA_ "GenSigSendOnInit" SG_ 2152071168 LRSAP_HdrstFwdRrwd 2;
BA_ "SignalType" SG_ 2152071168 LRSAP_HdrstFwdRrwd "UNM";
BA_ "PacketOrder" SG_ 2152071168 LRSAP_HdrstFwdRrwd 3;
BA_ "SignalLongName" SG_ 2152071168 LRSAP_HdrstFwdRrwd "Left Rear Seat Actuator Priority : Headrest Forward/Rearward";
BA_ "VNSigAllNodes" SG_ 2152071168 LRSAP_HdrstFwdRrwd 1;
BA_ "GenSigDeltaValue" SG_ 2152071168 LRSAP_HdrstUpDn 1;
BA_ "GenSigSendType" SG_ 2152071168 LRSAP_HdrstUpDn 12;
BA_ "GenSigSendOnInit" SG_ 2152071168 LRSAP_HdrstUpDn 2;
BA_ "SignalType" SG_ 2152071168 LRSAP_HdrstUpDn "UNM";
BA_ "PacketOrder" SG_ 2152071168 LRSAP_HdrstUpDn 2;
BA_ "SignalLongName" SG_ 2152071168 LRSAP_HdrstUpDn "Left Rear Seat Actuator Priority : Headrest Up/Down";
BA_ "VNSigAllNodes" SG_ 2152071168 LRSAP_HdrstUpDn 1;
BA_ "GenSigDeltaValue" SG_ 2152071168 LRSAP_Massg 1;
BA_ "GenSigSendType" SG_ 2152071168 LRSAP_Massg 12;
BA_ "GenSigSendOnInit" SG_ 2152071168 LRSAP_Massg 2;
BA_ "SignalType" SG_ 2152071168 LRSAP_Massg "UNM";
BA_ "PacketOrder" SG_ 2152071168 LRSAP_Massg 1;
BA_ "SignalLongName" SG_ 2152071168 LRSAP_Massg "Left Rear Seat Actuator Priority : Massage";
BA_ "VNSigAllNodes" SG_ 2152071168 LRSAP_Massg 1;
BA_ "SignalType" SG_ 2153308160 RdHVltBatPckVltV "ENM";
BA_ "SignalLongName" SG_ 2153308160 RdHVltBatPckVltV "Redundant High Voltage Battery Pack Voltage Validity";
BA_ "VNSigAllNodes" SG_ 2153308160 RdHVltBatPckVltV 1;
BA_ "SignalType" SG_ 2153308160 RdHVltBatPckVltM "ENM";
BA_ "SignalLongName" SG_ 2153308160 RdHVltBatPckVltM "Redundant High Voltage Battery Pack Voltage Mask";
BA_ "VNSigAllNodes" SG_ 2153308160 RdHVltBatPckVltM 1;
BA_ "GenSigSendOnInit" SG_ 2153308160 RdHVltBatPckVlt 1;
BA_ "SignalType" SG_ 2153308160 RdHVltBatPckVlt "UNM";
BA_ "SignalLongName" SG_ 2153308160 RdHVltBatPckVlt "Redundant High Voltage Battery Pack Voltage";
BA_ "VNSigAllNodes" SG_ 2153308160 RdHVltBatPckVlt 1;
BA_ "GenSigSendOnInit" SG_ 2153308160 RdHVltBatPckCrntV 1;
BA_ "SignalType" SG_ 2153308160 RdHVltBatPckCrntV "ENM";
BA_ "SignalLongName" SG_ 2153308160 RdHVltBatPckCrntV "Redundant High Voltage Battery Pack Current Validity";
BA_ "VNSigAllNodes" SG_ 2153308160 RdHVltBatPckCrntV 1;
BA_ "GenSigSendOnInit" SG_ 2153308160 RdHVltBatPckCrntM 1;
BA_ "SignalType" SG_ 2153308160 RdHVltBatPckCrntM "ENM";
BA_ "SignalLongName" SG_ 2153308160 RdHVltBatPckCrntM "Redundant High Voltage Battery Pack Current Mask";
BA_ "VNSigAllNodes" SG_ 2153308160 RdHVltBatPckCrntM 1;
BA_ "GenSigSendOnInit" SG_ 2153308160 RdHVltBatPckCrnt 1;
BA_ "SignalType" SG_ 2153308160 RdHVltBatPckCrnt "SNM";
BA_ "SignalLongName" SG_ 2153308160 RdHVltBatPckCrnt "Redundant High Voltage Battery Pack Current";
BA_ "VNSigAllNodes" SG_ 2153308160 RdHVltBatPckCrnt 1;
BA_ "GenSigSendType" SG_ 2149924864 PTOMobModTrnsInGrIO 10;
BA_ "SignalType" SG_ 2149924864 PTOMobModTrnsInGrIO "BLN";
BA_ "SignalLongName" SG_ 2149924864 PTOMobModTrnsInGrIO "Power Take Off Mobile Mode Transmission In Gear Indication On";
BA_ "VNSigAllNodes" SG_ 2149924864 PTOMobModTrnsInGrIO 1;
BA_ "GenSigSendType" SG_ 2149924864 FwdClnMtgnBrkReqAct 10;
BA_ "SignalType" SG_ 2149924864 FwdClnMtgnBrkReqAct "BLN";
BA_ "SignalLongName" SG_ 2149924864 FwdClnMtgnBrkReqAct "Forward Collision Mitigation Braking Request Active";
BA_ "VNSigAllNodes" SG_ 2149924864 FwdClnMtgnBrkReqAct 1;
BA_ "GenSigSendType" SG_ 2149924864 TireRRLowTracIO 10;
BA_ "SignalType" SG_ 2149924864 TireRRLowTracIO "BLN";
BA_ "SignalLongName" SG_ 2149924864 TireRRLowTracIO "Tire Right Rear Low Traction Indication On";
BA_ "VNSigAllNodes" SG_ 2149924864 TireRRLowTracIO 1;
BA_ "GenSigSendType" SG_ 2149924864 TireRFLowTracIO 10;
BA_ "SignalType" SG_ 2149924864 TireRFLowTracIO "BLN";
BA_ "SignalLongName" SG_ 2149924864 TireRFLowTracIO "Tire Right Front Low Traction Indication On";
BA_ "VNSigAllNodes" SG_ 2149924864 TireRFLowTracIO 1;
BA_ "GenSigSendType" SG_ 2149924864 TireLRLowTracIO 10;
BA_ "SignalType" SG_ 2149924864 TireLRLowTracIO "BLN";
BA_ "SignalLongName" SG_ 2149924864 TireLRLowTracIO "Tire Left Rear Low Traction Indication On";
BA_ "VNSigAllNodes" SG_ 2149924864 TireLRLowTracIO 1;
BA_ "GenSigSendType" SG_ 2149924864 TireLFLowTracIO 10;
BA_ "SignalType" SG_ 2149924864 TireLFLowTracIO "BLN";
BA_ "SignalLongName" SG_ 2149924864 TireLFLowTracIO "Tire Left Front Low Traction Indication On";
BA_ "VNSigAllNodes" SG_ 2149924864 TireLFLowTracIO 1;
BA_ "GenSigSendType" SG_ 2149924864 HilRlbkCtrlActIO 10;
BA_ "SignalType" SG_ 2149924864 HilRlbkCtrlActIO "BLN";
BA_ "SignalLongName" SG_ 2149924864 HilRlbkCtrlActIO "Hill Rollback Control Active Indiction On";
BA_ "VNSigAllNodes" SG_ 2149924864 HilRlbkCtrlActIO 1;
BA_ "GenSigSendType" SG_ 2149924864 DsplyPerfMdRq 10;
BA_ "SignalType" SG_ 2149924864 DsplyPerfMdRq "ENM";
BA_ "SignalLongName" SG_ 2149924864 DsplyPerfMdRq "Display Performance Mode Request";
BA_ "VNSigAllNodes" SG_ 2149924864 DsplyPerfMdRq 1;
BA_ "GenSigSendType" SG_ 2149924864 DrvSelMd8Stat 10;
BA_ "SignalType" SG_ 2149924864 DrvSelMd8Stat "ENM";
BA_ "SignalLongName" SG_ 2149924864 DrvSelMd8Stat "Driver Selected Mode 8 Status";
BA_ "VNSigAllNodes" SG_ 2149924864 DrvSelMd8Stat 1;
BA_ "GenSigSendType" SG_ 2149924864 DrvSelMd8ReqDnd 10;
BA_ "SignalType" SG_ 2149924864 DrvSelMd8ReqDnd "BLN";
BA_ "SignalLongName" SG_ 2149924864 DrvSelMd8ReqDnd "Driver Selected Mode 8 Request Denied";
BA_ "VNSigAllNodes" SG_ 2149924864 DrvSelMd8ReqDnd 1;
BA_ "GenSigSendType" SG_ 2149924864 DrvSelMd7Stat 10;
BA_ "SignalType" SG_ 2149924864 DrvSelMd7Stat "ENM";
BA_ "SignalLongName" SG_ 2149924864 DrvSelMd7Stat "Driver Selected Mode 7 Status";
BA_ "VNSigAllNodes" SG_ 2149924864 DrvSelMd7Stat 1;
BA_ "GenSigSendType" SG_ 2149924864 DrvSelMd7ReqDnd 10;
BA_ "SignalType" SG_ 2149924864 DrvSelMd7ReqDnd "BLN";
BA_ "SignalLongName" SG_ 2149924864 DrvSelMd7ReqDnd "Driver Selected Mode 7 Request Denied";
BA_ "VNSigAllNodes" SG_ 2149924864 DrvSelMd7ReqDnd 1;
BA_ "GenSigSendType" SG_ 2149924864 DrvSelMd6Stat 10;
BA_ "SignalType" SG_ 2149924864 DrvSelMd6Stat "ENM";
BA_ "SignalLongName" SG_ 2149924864 DrvSelMd6Stat "Driver Selected Mode 6 Status";
BA_ "VNSigAllNodes" SG_ 2149924864 DrvSelMd6Stat 1;
BA_ "GenSigSendType" SG_ 2149924864 DrvSelMd6ReqDnd 10;
BA_ "SignalType" SG_ 2149924864 DrvSelMd6ReqDnd "BLN";
BA_ "SignalLongName" SG_ 2149924864 DrvSelMd6ReqDnd "Driver Selected Mode 6 Request Denied";
BA_ "VNSigAllNodes" SG_ 2149924864 DrvSelMd6ReqDnd 1;
BA_ "GenSigSendType" SG_ 2149924864 DrvSelMd5Stat 10;
BA_ "SignalType" SG_ 2149924864 DrvSelMd5Stat "ENM";
BA_ "SignalLongName" SG_ 2149924864 DrvSelMd5Stat "Driver Selected Mode 5 Status";
BA_ "VNSigAllNodes" SG_ 2149924864 DrvSelMd5Stat 1;
BA_ "GenSigSendType" SG_ 2149924864 DrvSelMd5ReqDnd 10;
BA_ "SignalType" SG_ 2149924864 DrvSelMd5ReqDnd "BLN";
BA_ "SignalLongName" SG_ 2149924864 DrvSelMd5ReqDnd "Driver Selected Mode 5 Request Denied";
BA_ "VNSigAllNodes" SG_ 2149924864 DrvSelMd5ReqDnd 1;
BA_ "GenSigSendType" SG_ 2149924864 DrvSelMd4Stat 10;
BA_ "SignalType" SG_ 2149924864 DrvSelMd4Stat "ENM";
BA_ "SignalLongName" SG_ 2149924864 DrvSelMd4Stat "Driver Selected Mode 4 Status";
BA_ "VNSigAllNodes" SG_ 2149924864 DrvSelMd4Stat 1;
BA_ "GenSigSendType" SG_ 2149924864 DrvSelMd4ReqDnd 10;
BA_ "SignalType" SG_ 2149924864 DrvSelMd4ReqDnd "BLN";
BA_ "SignalLongName" SG_ 2149924864 DrvSelMd4ReqDnd "Driver Selected Mode 4 Request Denied";
BA_ "VNSigAllNodes" SG_ 2149924864 DrvSelMd4ReqDnd 1;
BA_ "GenSigSendType" SG_ 2149924864 EDADS_RcmndtFwdGr 10;
BA_ "SignalType" SG_ 2149924864 EDADS_RcmndtFwdGr "ENM";
BA_ "PacketOrder" SG_ 2149924864 EDADS_RcmndtFwdGr 4;
BA_ "SignalLongName" SG_ 2149924864 EDADS_RcmndtFwdGr "ECO Drive Assist Display Status : Recommended Forward Gear";
BA_ "VNSigAllNodes" SG_ 2149924864 EDADS_RcmndtFwdGr 1;
BA_ "GenSigSendType" SG_ 2149924864 EDADS_CrntFwdMsdG 10;
BA_ "SignalType" SG_ 2149924864 EDADS_CrntFwdMsdG "ENM";
BA_ "PacketOrder" SG_ 2149924864 EDADS_CrntFwdMsdG 3;
BA_ "SignalLongName" SG_ 2149924864 EDADS_CrntFwdMsdG "ECO Drive Assist Display Status : Current Forward Measured Gear";
BA_ "VNSigAllNodes" SG_ 2149924864 EDADS_CrntFwdMsdG 1;
BA_ "GenSigSendType" SG_ 2149924864 EDADS_ShftIndStat 10;
BA_ "SignalType" SG_ 2149924864 EDADS_ShftIndStat "ENM";
BA_ "PacketOrder" SG_ 2149924864 EDADS_ShftIndStat 2;
BA_ "SignalLongName" SG_ 2149924864 EDADS_ShftIndStat "ECO Drive Assist Display Status : Shift Indication Status";
BA_ "VNSigAllNodes" SG_ 2149924864 EDADS_ShftIndStat 1;
BA_ "GenSigSendType" SG_ 2149924864 EDADS_EcoDrvShftIO 10;
BA_ "SignalType" SG_ 2149924864 EDADS_EcoDrvShftIO "BLN";
BA_ "PacketOrder" SG_ 2149924864 EDADS_EcoDrvShftIO 1;
BA_ "SignalLongName" SG_ 2149924864 EDADS_EcoDrvShftIO "ECO Drive Assist Display Status : ECO Drive Assist Shift Indication On";
BA_ "VNSigAllNodes" SG_ 2149924864 EDADS_EcoDrvShftIO 1;
BA_ "GenSigSendType" SG_ 2149924864 DSMSS_DrvSelMd0Pn 10;
BA_ "GenSigSendOnInit" SG_ 2149924864 DSMSS_DrvSelMd0Pn 1;
BA_ "SignalType" SG_ 2149924864 DSMSS_DrvSelMd0Pn "BLN";
BA_ "PacketOrder" SG_ 2149924864 DSMSS_DrvSelMd0Pn 17;
BA_ "SignalLongName" SG_ 2149924864 DSMSS_DrvSelMd0Pn "Driver Selected Mode Selection Status : Driver Selected Mode 0 Pending";
BA_ "VNSigAllNodes" SG_ 2149924864 DSMSS_DrvSelMd0Pn 1;
BA_ "GenSigSendType" SG_ 2149924864 DSMSS_DrvSelMd8Pn 10;
BA_ "GenSigSendOnInit" SG_ 2149924864 DSMSS_DrvSelMd8Pn 1;
BA_ "SignalType" SG_ 2149924864 DSMSS_DrvSelMd8Pn "BLN";
BA_ "PacketOrder" SG_ 2149924864 DSMSS_DrvSelMd8Pn 16;
BA_ "SignalLongName" SG_ 2149924864 DSMSS_DrvSelMd8Pn "Driver Selected Mode Selection Status : Driver Selected Mode 8 Pending";
BA_ "VNSigAllNodes" SG_ 2149924864 DSMSS_DrvSelMd8Pn 1;
BA_ "GenSigSendType" SG_ 2149924864 DSMSS_DrvSelMd7Pn 10;
BA_ "GenSigSendOnInit" SG_ 2149924864 DSMSS_DrvSelMd7Pn 1;
BA_ "SignalType" SG_ 2149924864 DSMSS_DrvSelMd7Pn "BLN";
BA_ "PacketOrder" SG_ 2149924864 DSMSS_DrvSelMd7Pn 15;
BA_ "SignalLongName" SG_ 2149924864 DSMSS_DrvSelMd7Pn "Driver Selected Mode Selection Status : Driver Selected Mode 7 Pending";
BA_ "VNSigAllNodes" SG_ 2149924864 DSMSS_DrvSelMd7Pn 1;
BA_ "GenSigSendType" SG_ 2149924864 DSMSS_DrvSelMd6Pn 10;
BA_ "GenSigSendOnInit" SG_ 2149924864 DSMSS_DrvSelMd6Pn 1;
BA_ "SignalType" SG_ 2149924864 DSMSS_DrvSelMd6Pn "BLN";
BA_ "PacketOrder" SG_ 2149924864 DSMSS_DrvSelMd6Pn 14;
BA_ "SignalLongName" SG_ 2149924864 DSMSS_DrvSelMd6Pn "Driver Selected Mode Selection Status : Driver Selected Mode 6 Pending";
BA_ "VNSigAllNodes" SG_ 2149924864 DSMSS_DrvSelMd6Pn 1;
BA_ "GenSigSendType" SG_ 2149924864 DSMSS_DrvSelMd5Pn 10;
BA_ "GenSigSendOnInit" SG_ 2149924864 DSMSS_DrvSelMd5Pn 1;
BA_ "SignalType" SG_ 2149924864 DSMSS_DrvSelMd5Pn "BLN";
BA_ "PacketOrder" SG_ 2149924864 DSMSS_DrvSelMd5Pn 13;
BA_ "SignalLongName" SG_ 2149924864 DSMSS_DrvSelMd5Pn "Driver Selected Mode Selection Status : Driver Selected Mode 5 Pending";
BA_ "VNSigAllNodes" SG_ 2149924864 DSMSS_DrvSelMd5Pn 1;
BA_ "GenSigSendType" SG_ 2149924864 DSMSS_DrvSelMd4Pn 10;
BA_ "GenSigSendOnInit" SG_ 2149924864 DSMSS_DrvSelMd4Pn 1;
BA_ "SignalType" SG_ 2149924864 DSMSS_DrvSelMd4Pn "BLN";
BA_ "PacketOrder" SG_ 2149924864 DSMSS_DrvSelMd4Pn 12;
BA_ "SignalLongName" SG_ 2149924864 DSMSS_DrvSelMd4Pn "Driver Selected Mode Selection Status : Driver Selected Mode 4 Pending";
BA_ "VNSigAllNodes" SG_ 2149924864 DSMSS_DrvSelMd4Pn 1;
BA_ "GenSigSendType" SG_ 2149924864 DSMSS_DrvSelMd3Pn 10;
BA_ "GenSigSendOnInit" SG_ 2149924864 DSMSS_DrvSelMd3Pn 1;
BA_ "SignalType" SG_ 2149924864 DSMSS_DrvSelMd3Pn "BLN";
BA_ "PacketOrder" SG_ 2149924864 DSMSS_DrvSelMd3Pn 11;
BA_ "SignalLongName" SG_ 2149924864 DSMSS_DrvSelMd3Pn "Driver Selected Mode Selection Status : Driver Selected Mode 3 Pending";
BA_ "VNSigAllNodes" SG_ 2149924864 DSMSS_DrvSelMd3Pn 1;
BA_ "GenSigSendType" SG_ 2149924864 DSMSS_DrvSelMd2Pn 10;
BA_ "GenSigSendOnInit" SG_ 2149924864 DSMSS_DrvSelMd2Pn 1;
BA_ "SignalType" SG_ 2149924864 DSMSS_DrvSelMd2Pn "BLN";
BA_ "PacketOrder" SG_ 2149924864 DSMSS_DrvSelMd2Pn 10;
BA_ "SignalLongName" SG_ 2149924864 DSMSS_DrvSelMd2Pn "Driver Selected Mode Selection Status : Driver Selected Mode 2 Pending";
BA_ "VNSigAllNodes" SG_ 2149924864 DSMSS_DrvSelMd2Pn 1;
BA_ "GenSigSendType" SG_ 2149924864 DSMSS_DrvSelMd1Pn 10;
BA_ "GenSigSendOnInit" SG_ 2149924864 DSMSS_DrvSelMd1Pn 1;
BA_ "SignalType" SG_ 2149924864 DSMSS_DrvSelMd1Pn "BLN";
BA_ "PacketOrder" SG_ 2149924864 DSMSS_DrvSelMd1Pn 9;
BA_ "SignalLongName" SG_ 2149924864 DSMSS_DrvSelMd1Pn "Driver Selected Mode Selection Status : Driver Selected Mode 1 Pending";
BA_ "VNSigAllNodes" SG_ 2149924864 DSMSS_DrvSelMd1Pn 1;
BA_ "GenSigSendType" SG_ 2149924864 DSMSS_DrvSelMd8Un 10;
BA_ "GenSigSendOnInit" SG_ 2149924864 DSMSS_DrvSelMd8Un 1;
BA_ "SignalType" SG_ 2149924864 DSMSS_DrvSelMd8Un "BLN";
BA_ "PacketOrder" SG_ 2149924864 DSMSS_DrvSelMd8Un 8;
BA_ "SignalLongName" SG_ 2149924864 DSMSS_DrvSelMd8Un "Driver Selected Mode Selection Status : Driver Selected Mode 8 Unavailable";
BA_ "VNSigAllNodes" SG_ 2149924864 DSMSS_DrvSelMd8Un 1;
BA_ "GenSigSendType" SG_ 2149924864 DSMSS_DrvSelMd7Un 10;
BA_ "GenSigSendOnInit" SG_ 2149924864 DSMSS_DrvSelMd7Un 1;
BA_ "SignalType" SG_ 2149924864 DSMSS_DrvSelMd7Un "BLN";
BA_ "PacketOrder" SG_ 2149924864 DSMSS_DrvSelMd7Un 7;
BA_ "SignalLongName" SG_ 2149924864 DSMSS_DrvSelMd7Un "Driver Selected Mode Selection Status : Driver Selected Mode 7 Unavailable";
BA_ "VNSigAllNodes" SG_ 2149924864 DSMSS_DrvSelMd7Un 1;
BA_ "GenSigSendType" SG_ 2149924864 DSMSS_DrvSelMd6Un 10;
BA_ "GenSigSendOnInit" SG_ 2149924864 DSMSS_DrvSelMd6Un 1;
BA_ "SignalType" SG_ 2149924864 DSMSS_DrvSelMd6Un "BLN";
BA_ "PacketOrder" SG_ 2149924864 DSMSS_DrvSelMd6Un 6;
BA_ "SignalLongName" SG_ 2149924864 DSMSS_DrvSelMd6Un "Driver Selected Mode Selection Status : Driver Selected Mode 6 Unavailable";
BA_ "VNSigAllNodes" SG_ 2149924864 DSMSS_DrvSelMd6Un 1;
BA_ "GenSigSendType" SG_ 2149924864 DSMSS_DrvSelMd5Un 10;
BA_ "GenSigSendOnInit" SG_ 2149924864 DSMSS_DrvSelMd5Un 1;
BA_ "SignalType" SG_ 2149924864 DSMSS_DrvSelMd5Un "BLN";
BA_ "PacketOrder" SG_ 2149924864 DSMSS_DrvSelMd5Un 5;
BA_ "SignalLongName" SG_ 2149924864 DSMSS_DrvSelMd5Un "Driver Selected Mode Selection Status : Driver Selected Mode 5 Unavailable";
BA_ "VNSigAllNodes" SG_ 2149924864 DSMSS_DrvSelMd5Un 1;
BA_ "GenSigSendType" SG_ 2149924864 DSMSS_DrvSelMd4Un 10;
BA_ "GenSigSendOnInit" SG_ 2149924864 DSMSS_DrvSelMd4Un 1;
BA_ "SignalType" SG_ 2149924864 DSMSS_DrvSelMd4Un "BLN";
BA_ "PacketOrder" SG_ 2149924864 DSMSS_DrvSelMd4Un 4;
BA_ "SignalLongName" SG_ 2149924864 DSMSS_DrvSelMd4Un "Driver Selected Mode Selection Status : Driver Selected Mode 4 Unavailable";
BA_ "VNSigAllNodes" SG_ 2149924864 DSMSS_DrvSelMd4Un 1;
BA_ "GenSigSendType" SG_ 2149924864 DSMSS_DrvSelMd3Un 10;
BA_ "GenSigSendOnInit" SG_ 2149924864 DSMSS_DrvSelMd3Un 1;
BA_ "SignalType" SG_ 2149924864 DSMSS_DrvSelMd3Un "BLN";
BA_ "PacketOrder" SG_ 2149924864 DSMSS_DrvSelMd3Un 3;
BA_ "SignalLongName" SG_ 2149924864 DSMSS_DrvSelMd3Un "Driver Selected Mode Selection Status : Driver Selected Mode 3 Unavailable";
BA_ "VNSigAllNodes" SG_ 2149924864 DSMSS_DrvSelMd3Un 1;
BA_ "GenSigSendType" SG_ 2149924864 DSMSS_DrvSelMd2Un 10;
BA_ "GenSigSendOnInit" SG_ 2149924864 DSMSS_DrvSelMd2Un 1;
BA_ "SignalType" SG_ 2149924864 DSMSS_DrvSelMd2Un "BLN";
BA_ "PacketOrder" SG_ 2149924864 DSMSS_DrvSelMd2Un 2;
BA_ "SignalLongName" SG_ 2149924864 DSMSS_DrvSelMd2Un "Driver Selected Mode Selection Status : Driver Selected Mode 2 Unavailable";
BA_ "VNSigAllNodes" SG_ 2149924864 DSMSS_DrvSelMd2Un 1;
BA_ "GenSigSendType" SG_ 2149924864 DSMSS_DrvSelMd1Un 10;
BA_ "GenSigSendOnInit" SG_ 2149924864 DSMSS_DrvSelMd1Un 1;
BA_ "SignalType" SG_ 2149924864 DSMSS_DrvSelMd1Un "BLN";
BA_ "PacketOrder" SG_ 2149924864 DSMSS_DrvSelMd1Un 1;
BA_ "SignalLongName" SG_ 2149924864 DSMSS_DrvSelMd1Un "Driver Selected Mode Selection Status : Driver Selected Mode 1 Unavailable";
BA_ "VNSigAllNodes" SG_ 2149924864 DSMSS_DrvSelMd1Un 1;
BA_ "GenSigSendType" SG_ 2149924864 DrvSelMd3Stat 10;
BA_ "GenSigSendOnInit" SG_ 2149924864 DrvSelMd3Stat 1;
BA_ "SignalType" SG_ 2149924864 DrvSelMd3Stat "ENM";
BA_ "SignalLongName" SG_ 2149924864 DrvSelMd3Stat "Driver Selected Mode 3 Status";
BA_ "VNSigAllNodes" SG_ 2149924864 DrvSelMd3Stat 1;
BA_ "GenSigSendType" SG_ 2149924864 DrvSelMd3ReqDnd 10;
BA_ "SignalType" SG_ 2149924864 DrvSelMd3ReqDnd "BLN";
BA_ "SignalLongName" SG_ 2149924864 DrvSelMd3ReqDnd "Driver Selected Mode 3 Request Denied";
BA_ "VNSigAllNodes" SG_ 2149924864 DrvSelMd3ReqDnd 1;
BA_ "GenSigSendType" SG_ 2149924864 DrvSelMd2Stat 10;
BA_ "GenSigSendOnInit" SG_ 2149924864 DrvSelMd2Stat 1;
BA_ "SignalType" SG_ 2149924864 DrvSelMd2Stat "ENM";
BA_ "SignalLongName" SG_ 2149924864 DrvSelMd2Stat "Driver Selected Mode 2 Status";
BA_ "VNSigAllNodes" SG_ 2149924864 DrvSelMd2Stat 1;
BA_ "GenSigSendType" SG_ 2149924864 DrvSelMd2ReqDnd 10;
BA_ "SignalType" SG_ 2149924864 DrvSelMd2ReqDnd "BLN";
BA_ "SignalLongName" SG_ 2149924864 DrvSelMd2ReqDnd "Driver Selected Mode 2 Request Denied";
BA_ "VNSigAllNodes" SG_ 2149924864 DrvSelMd2ReqDnd 1;
BA_ "GenSigSendType" SG_ 2149924864 DrvSelMd1Stat 10;
BA_ "GenSigSendOnInit" SG_ 2149924864 DrvSelMd1Stat 1;
BA_ "SignalType" SG_ 2149924864 DrvSelMd1Stat "ENM";
BA_ "SignalLongName" SG_ 2149924864 DrvSelMd1Stat "Driver Selected Mode 1 Status";
BA_ "VNSigAllNodes" SG_ 2149924864 DrvSelMd1Stat 1;
BA_ "GenSigSendType" SG_ 2149924864 DrvSelMd1ReqDnd 10;
BA_ "SignalType" SG_ 2149924864 DrvSelMd1ReqDnd "BLN";
BA_ "SignalLongName" SG_ 2149924864 DrvSelMd1ReqDnd "Driver Selected Mode 1 Request Denied";
BA_ "VNSigAllNodes" SG_ 2149924864 DrvSelMd1ReqDnd 1;
BA_ "GenSigSendType" SG_ 2149924864 a_12VBatSysUnstab 10;
BA_ "SignalType" SG_ 2149924864 a_12VBatSysUnstab "BLN";
BA_ "SignalLongName" SG_ 2149924864 a_12VBatSysUnstab "12 Volt Battery System Unstable";
BA_ "VNSigAllNodes" SG_ 2149924864 a_12VBatSysUnstab 1;
BA_ "GenSigSendType" SG_ 2149924864 FstIdlMdAct 10;
BA_ "SignalType" SG_ 2149924864 FstIdlMdAct "BLN";
BA_ "SignalLongName" SG_ 2149924864 FstIdlMdAct "Fast Idle Mode Active";
BA_ "VNSigAllNodes" SG_ 2149924864 FstIdlMdAct 1;
BA_ "GenSigSendType" SG_ 2149924864 CPSCA_Resrv3Avail 10;
BA_ "PacketOrder" SG_ 2149924864 CPSCA_Resrv3Avail 7;
BA_ "SignalType" SG_ 2149924864 CPSCA_Resrv3Avail "BLN";
BA_ "SignalLongName" SG_ 2149924864 CPSCA_Resrv3Avail "Collision Preparation System Customization Available : Reserved3 Available";
BA_ "VNSigAllNodes" SG_ 2149924864 CPSCA_Resrv3Avail 1;
BA_ "GenSigSendType" SG_ 2149924864 CPSCA_Resrv2Avail 10;
BA_ "PacketOrder" SG_ 2149924864 CPSCA_Resrv2Avail 6;
BA_ "SignalType" SG_ 2149924864 CPSCA_Resrv2Avail "BLN";
BA_ "SignalLongName" SG_ 2149924864 CPSCA_Resrv2Avail "Collision Preparation System Customization Available : Reserved2 Available";
BA_ "VNSigAllNodes" SG_ 2149924864 CPSCA_Resrv2Avail 1;
BA_ "GenSigSendType" SG_ 2149924864 CPSCA_Resrv1Avail 10;
BA_ "PacketOrder" SG_ 2149924864 CPSCA_Resrv1Avail 5;
BA_ "SignalType" SG_ 2149924864 CPSCA_Resrv1Avail "BLN";
BA_ "SignalLongName" SG_ 2149924864 CPSCA_Resrv1Avail "Collision Preparation System Customization Available : Reserved1 Available";
BA_ "VNSigAllNodes" SG_ 2149924864 CPSCA_Resrv1Avail 1;
BA_ "GenSigSendType" SG_ 2149924864 CPSCA_AlrtBrkStrAvail 10;
BA_ "PacketOrder" SG_ 2149924864 CPSCA_AlrtBrkStrAvail 4;
BA_ "SignalType" SG_ 2149924864 CPSCA_AlrtBrkStrAvail "BLN";
BA_ "SignalLongName" SG_ 2149924864 CPSCA_AlrtBrkStrAvail "Collision Preparation System Customization Available : Alert and Brake and Steer Available";
BA_ "VNSigAllNodes" SG_ 2149924864 CPSCA_AlrtBrkStrAvail 1;
BA_ "GenSigSendType" SG_ 2149924864 CPSCA_AlrtBrkAvail 10;
BA_ "PacketOrder" SG_ 2149924864 CPSCA_AlrtBrkAvail 3;
BA_ "GenSigStartValue" SG_ 2149924864 CPSCA_AlrtBrkAvail 1;
BA_ "SignalType" SG_ 2149924864 CPSCA_AlrtBrkAvail "BLN";
BA_ "SignalLongName" SG_ 2149924864 CPSCA_AlrtBrkAvail "Collision Preparation System Customization Available : Alert and Brake Available";
BA_ "VNSigAllNodes" SG_ 2149924864 CPSCA_AlrtBrkAvail 1;
BA_ "GenSigSendType" SG_ 2149924864 CPSCA_AlrtAvail 10;
BA_ "PacketOrder" SG_ 2149924864 CPSCA_AlrtAvail 2;
BA_ "GenSigStartValue" SG_ 2149924864 CPSCA_AlrtAvail 1;
BA_ "SignalType" SG_ 2149924864 CPSCA_AlrtAvail "BLN";
BA_ "SignalLongName" SG_ 2149924864 CPSCA_AlrtAvail "Collision Preparation System Customization Available : Alert Available";
BA_ "VNSigAllNodes" SG_ 2149924864 CPSCA_AlrtAvail 1;
BA_ "GenSigSendType" SG_ 2149924864 CPSCA_OffAvail 10;
BA_ "PacketOrder" SG_ 2149924864 CPSCA_OffAvail 1;
BA_ "GenSigStartValue" SG_ 2149924864 CPSCA_OffAvail 1;
BA_ "SignalType" SG_ 2149924864 CPSCA_OffAvail "BLN";
BA_ "SignalLongName" SG_ 2149924864 CPSCA_OffAvail "Collision Preparation System Customization Available : Off Available";
BA_ "VNSigAllNodes" SG_ 2149924864 CPSCA_OffAvail 1;
BA_ "GenSigSendType" SG_ 2151153664 RrWndDfgOn 10;
BA_ "GenSigSendOnInit" SG_ 2151153664 RrWndDfgOn 1;
BA_ "SignalType" SG_ 2151153664 RrWndDfgOn "BLN";
BA_ "SignalLongName" SG_ 2151153664 RrWndDfgOn "Rear Window Defog On";
BA_ "VNSigAllNodes" SG_ 2151153664 RrWndDfgOn 1;
BA_ "GenSigSendType" SG_ 2151841792 HtdFrntWSSt 10;
BA_ "SignalType" SG_ 2151841792 HtdFrntWSSt "ENM";
BA_ "SignalLongName" SG_ 2151841792 HtdFrntWSSt "Heated Front Windshield Status";
BA_ "VNSigAllNodes" SG_ 2151841792 HtdFrntWSSt 1;
BA_ "GenSigSendType" SG_ 2151841792 WSWprAct 10;
BA_ "SignalType" SG_ 2151841792 WSWprAct "BLN";
BA_ "SignalLongName" SG_ 2151841792 WSWprAct "Windshield Wiper Active";
BA_ "VNSigAllNodes" SG_ 2151841792 WSWprAct 1;
BA_ "GenSigSendType" SG_ 2151841792 RnSnsOffIO 10;
BA_ "GenSigSendOnInit" SG_ 2151841792 RnSnsOffIO 2;
BA_ "SignalType" SG_ 2151841792 RnSnsOffIO "BLN";
BA_ "SignalLongName" SG_ 2151841792 RnSnsOffIO "Rain Sensor Off Indication On";
BA_ "VNSigAllNodes" SG_ 2151841792 RnSnsOffIO 1;
BA_ "GenSigSendType" SG_ 2151841792 RnSnsActIO 10;
BA_ "SignalType" SG_ 2151841792 RnSnsActIO "BLN";
BA_ "SignalLongName" SG_ 2151841792 RnSnsActIO "Rain Sensor Active Indication On";
BA_ "VNSigAllNodes" SG_ 2151841792 RnSnsActIO 1;
BA_ "GenSigSendType" SG_ 2151841792 TurnWprIntIO 10;
BA_ "SignalType" SG_ 2151841792 TurnWprIntIO "BLN";
BA_ "SignalLongName" SG_ 2151841792 TurnWprIntIO "Turn Wiper Control To Intermittent First Indication On";
BA_ "VNSigAllNodes" SG_ 2151841792 TurnWprIntIO 1;
BA_ "GenSigSendType" SG_ 2154078208 RRWndPosStat 10;
BA_ "GenSigSendOnInit" SG_ 2154078208 RRWndPosStat 2;
BA_ "SignalType" SG_ 2154078208 RRWndPosStat "ENM";
BA_ "SignalLongName" SG_ 2154078208 RRWndPosStat "Right Rear Window Position Status";
BA_ "VNSigAllNodes" SG_ 2154078208 RRWndPosStat 1;
BA_ "GenSigSendType" SG_ 2154078208 PsWndPosStat 10;
BA_ "GenSigSendOnInit" SG_ 2154078208 PsWndPosStat 2;
BA_ "SignalType" SG_ 2154078208 PsWndPosStat "ENM";
BA_ "SignalLongName" SG_ 2154078208 PsWndPosStat "Passenger Window Position Status";
BA_ "VNSigAllNodes" SG_ 2154078208 PsWndPosStat 1;
BA_ "GenSigSendType" SG_ 2154078208 LRWndPosStat 10;
BA_ "GenSigSendOnInit" SG_ 2154078208 LRWndPosStat 2;
BA_ "SignalType" SG_ 2154078208 LRWndPosStat "ENM";
BA_ "SignalLongName" SG_ 2154078208 LRWndPosStat "Left Rear Window Position Status";
BA_ "VNSigAllNodes" SG_ 2154078208 LRWndPosStat 1;
BA_ "GenSigSendType" SG_ 2154078208 DrvWndPosStat 10;
BA_ "GenSigSendOnInit" SG_ 2154078208 DrvWndPosStat 2;
BA_ "SignalType" SG_ 2154078208 DrvWndPosStat "ENM";
BA_ "SignalLongName" SG_ 2154078208 DrvWndPosStat "Driver Window Position Status";
BA_ "VNSigAllNodes" SG_ 2154078208 DrvWndPosStat 1;
BA_ "GenSigSendType" SG_ 2151399424 WshFldLw 10;
BA_ "GenSigSendOnInit" SG_ 2151399424 WshFldLw 1;
BA_ "SignalType" SG_ 2151399424 WshFldLw "BLN";
BA_ "SignalLongName" SG_ 2151399424 WshFldLw "Washer Fluid Low";
BA_ "VNSigAllNodes" SG_ 2151399424 WshFldLw 1;
BA_ "GenSigSendType" SG_ 2151399424 VhlFlRngLwIO 10;
BA_ "GenSigSendOnInit" SG_ 2151399424 VhlFlRngLwIO 2;
BA_ "SignalType" SG_ 2151399424 VhlFlRngLwIO "BLN";
BA_ "SignalLongName" SG_ 2151399424 VhlFlRngLwIO "Vehicle Fuel Range Low Indication On";
BA_ "VNSigAllNodes" SG_ 2151399424 VhlFlRngLwIO 1;
BA_ "GenSigSendType" SG_ 2151170048 RrEndCrrStat 10;
BA_ "SignalType" SG_ 2151170048 RrEndCrrStat "ENM";
BA_ "SignalLongName" SG_ 2151170048 RrEndCrrStat "Rear End Carrier Status";
BA_ "VNSigAllNodes" SG_ 2151170048 RrEndCrrStat 1;
BA_ "GenSigSendType" SG_ 2151170048 RRPrkLmpFld 10;
BA_ "SignalType" SG_ 2151170048 RRPrkLmpFld "BLN";
BA_ "SignalLongName" SG_ 2151170048 RRPrkLmpFld "Rear Right Park Lamp Failed";
BA_ "VNSigAllNodes" SG_ 2151170048 RRPrkLmpFld 1;
BA_ "GenSigSendType" SG_ 2151170048 RLftPrkLmpFld 10;
BA_ "SignalType" SG_ 2151170048 RLftPrkLmpFld "BLN";
BA_ "SignalLongName" SG_ 2151170048 RLftPrkLmpFld "Rear Left Park Lamp Failed";
BA_ "VNSigAllNodes" SG_ 2151170048 RLftPrkLmpFld 1;
BA_ "GenSigSendType" SG_ 2151170048 DisRrPrmryLmps 10;
BA_ "SignalType" SG_ 2151170048 DisRrPrmryLmps "BLN";
BA_ "SignalLongName" SG_ 2151170048 DisRrPrmryLmps "Disable Rear Primary Lamps";
BA_ "VNSigAllNodes" SG_ 2151170048 DisRrPrmryLmps 1;
BA_ "GenSigSendType" SG_ 2151170048 TrlrTlLtFld 10;
BA_ "SignalType" SG_ 2151170048 TrlrTlLtFld "BLN";
BA_ "SignalLongName" SG_ 2151170048 TrlrTlLtFld "Trailer Tail Light Failed";
BA_ "VNSigAllNodes" SG_ 2151170048 TrlrTlLtFld 1;
BA_ "GenSigSendType" SG_ 2151170048 TrlrRvsLtFld 10;
BA_ "SignalType" SG_ 2151170048 TrlrRvsLtFld "BLN";
BA_ "SignalLongName" SG_ 2151170048 TrlrRvsLtFld "Trailer Reverse Light Failed";
BA_ "VNSigAllNodes" SG_ 2151170048 TrlrRvsLtFld 1;
BA_ "GenSigSendType" SG_ 2151170048 TrlrFgLtFld 10;
BA_ "SignalType" SG_ 2151170048 TrlrFgLtFld "BLN";
BA_ "SignalLongName" SG_ 2151170048 TrlrFgLtFld "Trailer Fog Light Failed";
BA_ "VNSigAllNodes" SG_ 2151170048 TrlrFgLtFld 1;
BA_ "GenSigSendType" SG_ 2151170048 TrlrBrkLtFld 10;
BA_ "SignalType" SG_ 2151170048 TrlrBrkLtFld "BLN";
BA_ "SignalLongName" SG_ 2151170048 TrlrBrkLtFld "Trailer Brake Light Failed";
BA_ "VNSigAllNodes" SG_ 2151170048 TrlrBrkLtFld 1;
BA_ "GenSigSendType" SG_ 2151170048 TrlrRtTrInLtFld 10;
BA_ "GenSigSendOnInit" SG_ 2151170048 TrlrRtTrInLtFld 1;
BA_ "SignalType" SG_ 2151170048 TrlrRtTrInLtFld "BLN";
BA_ "SignalLongName" SG_ 2151170048 TrlrRtTrInLtFld "Trailer Right Turn Indicator Light Failed";
BA_ "VNSigAllNodes" SG_ 2151170048 TrlrRtTrInLtFld 1;
BA_ "GenSigSendType" SG_ 2151170048 TrlLfTrInLtFld 10;
BA_ "GenSigSendOnInit" SG_ 2151170048 TrlLfTrInLtFld 1;
BA_ "SignalType" SG_ 2151170048 TrlLfTrInLtFld "BLN";
BA_ "SignalLongName" SG_ 2151170048 TrlLfTrInLtFld "Trailer Left Turn Indicator Light Failed";
BA_ "VNSigAllNodes" SG_ 2151170048 TrlLfTrInLtFld 1;
BA_ "GenSigSendType" SG_ 2151170048 TrlrHtchSwAtv 10;
BA_ "GenSigSendOnInit" SG_ 2151170048 TrlrHtchSwAtv 2;
BA_ "VNSigParkedVehicle" SG_ 2151170048 TrlrHtchSwAtv 1;
BA_ "SignalType" SG_ 2151170048 TrlrHtchSwAtv "BLN";
BA_ "SignalLongName" SG_ 2151170048 TrlrHtchSwAtv "Trailer Hitch Switch Active";
BA_ "VNSigAllNodes" SG_ 2151170048 TrlrHtchSwAtv 1;
BA_ "GenSigSendType" SG_ 2151170048 RtSecTrnIndFld 10;
BA_ "SignalType" SG_ 2151170048 RtSecTrnIndFld "BLN";
BA_ "SignalLongName" SG_ 2151170048 RtSecTrnIndFld "Right Secondary Turn Indicator Failed";
BA_ "VNSigAllNodes" SG_ 2151170048 RtSecTrnIndFld 1;
BA_ "GenSigSendType" SG_ 2151170048 TrlrFgLtPrs 10;
BA_ "SignalType" SG_ 2151170048 TrlrFgLtPrs "BLN";
BA_ "SignalLongName" SG_ 2151170048 TrlrFgLtPrs "Trailer Fog Light Present";
BA_ "VNSigAllNodes" SG_ 2151170048 TrlrFgLtPrs 1;
BA_ "GenSigSendType" SG_ 2151170048 LftSecTrnIndFld 10;
BA_ "SignalType" SG_ 2151170048 LftSecTrnIndFld "BLN";
BA_ "SignalLongName" SG_ 2151170048 LftSecTrnIndFld "Left Secondary Turn Indicator Failed";
BA_ "VNSigAllNodes" SG_ 2151170048 LftSecTrnIndFld 1;
BA_ "GenSigSendType" SG_ 2152759296 PedWrnIndReq 10;
BA_ "SignalType" SG_ 2152759296 PedWrnIndReq "ENM";
BA_ "SignalLongName" SG_ 2152759296 PedWrnIndReq "Pedestrian Warning Indication Request";
BA_ "VNSigAllNodes" SG_ 2152759296 PedWrnIndReq 1;
BA_ "GenSigSendType" SG_ 2152759296 FrtRdrFldIO 10;
BA_ "SignalType" SG_ 2152759296 FrtRdrFldIO "BLN";
BA_ "SignalLongName" SG_ 2152759296 FrtRdrFldIO "Front Radar Failed Indication On";
BA_ "VNSigAllNodes" SG_ 2152759296 FrtRdrFldIO 1;
BA_ "GenSigSendType" SG_ 2152759296 FrtCmrFldIO 10;
BA_ "SignalType" SG_ 2152759296 FrtCmrFldIO "BLN";
BA_ "SignalLongName" SG_ 2152759296 FrtCmrFldIO "Front Camera Failed Indication on";
BA_ "VNSigAllNodes" SG_ 2152759296 FrtCmrFldIO 1;
BA_ "GenSigSendType" SG_ 2152759296 FrtEOCMMdlFldIO 10;
BA_ "SignalType" SG_ 2152759296 FrtEOCMMdlFldIO "BLN";
BA_ "SignalLongName" SG_ 2152759296 FrtEOCMMdlFldIO "Front External Object Calculating Module Failed Indication On";
BA_ "VNSigAllNodes" SG_ 2152759296 FrtEOCMMdlFldIO 1;
BA_ "GenSigSendType" SG_ 2152759296 FrtCmrBlckdIO 10;
BA_ "GenSigSendOnInit" SG_ 2152759296 FrtCmrBlckdIO 2;
BA_ "SignalType" SG_ 2152759296 FrtCmrBlckdIO "BLN";
BA_ "SignalLongName" SG_ 2152759296 FrtCmrBlckdIO "Front Camera Block Indication On";
BA_ "VNSigAllNodes" SG_ 2152759296 FrtCmrBlckdIO 1;
BA_ "GenSigSendType" SG_ 2150850560 PsSbltAtcV 10;
BA_ "GenSigSendOnInit" SG_ 2150850560 PsSbltAtcV 2;
BA_ "SignalType" SG_ 2150850560 PsSbltAtcV "ENM";
BA_ "SignalLongName" SG_ 2150850560 PsSbltAtcV "Passenger Seatbelt Attached Validity";
BA_ "VNSigAllNodes" SG_ 2150850560 PsSbltAtcV 1;
BA_ "GenSigSendType" SG_ 2150850560 PsSbltAtc 10;
BA_ "GenSigSendOnInit" SG_ 2150850560 PsSbltAtc 2;
BA_ "SignalType" SG_ 2150850560 PsSbltAtc "BLN";
BA_ "SignalLongName" SG_ 2150850560 PsSbltAtc "Passenger Seatbelt Attached";
BA_ "VNSigAllNodes" SG_ 2150850560 PsSbltAtc 1;
BA_ "GenSigSendType" SG_ 2150850560 DrSbltAtcV 10;
BA_ "SignalType" SG_ 2150850560 DrSbltAtcV "ENM";
BA_ "SignalLongName" SG_ 2150850560 DrSbltAtcV "Driver Seatbelt Attached Validity";
BA_ "VNSigAllNodes" SG_ 2150850560 DrSbltAtcV 1;
BA_ "GenSigSendType" SG_ 2150850560 DrSbltAtc 10;
BA_ "SignalType" SG_ 2150850560 DrSbltAtc "BLN";
BA_ "SignalLongName" SG_ 2150850560 DrSbltAtc "Driver Seatbelt Attached";
BA_ "VNSigAllNodes" SG_ 2150850560 DrSbltAtc 1;
BA_ "GenSigSendType" SG_ 2150604800 RRDoorAjarSwAct 10;
BA_ "GenSigSendOnInit" SG_ 2150604800 RRDoorAjarSwAct 2;
BA_ "VNSigInfotainment" SG_ 2150604800 RRDoorAjarSwAct 1;
BA_ "SignalType" SG_ 2150604800 RRDoorAjarSwAct "BLN";
BA_ "SignalLongName" SG_ 2150604800 RRDoorAjarSwAct "Rear Right Door Ajar Switch Active";
BA_ "VNSigAllNodes" SG_ 2150604800 RRDoorAjarSwAct 1;
BA_ "GenSigSendType" SG_ 2151219200 RemStrtSt 10;
BA_ "GenSigSendOnInit" SG_ 2151219200 RemStrtSt 2;
BA_ "VNSigInfotainment" SG_ 2151219200 RemStrtSt 1;
BA_ "SignalType" SG_ 2151219200 RemStrtSt "ENM";
BA_ "SignalLongName" SG_ 2151219200 RemStrtSt "Remote Start Status";
BA_ "VNSigAllNodes" SG_ 2151219200 RemStrtSt 1;
BA_ "GenSigSendType" SG_ 2151219200 RmVehStrRq 10;
BA_ "SignalType" SG_ 2151219200 RmVehStrRq "ENM";
BA_ "SignalLongName" SG_ 2151219200 RmVehStrRq "Remote Vehicle Start Request";
BA_ "VNSigAllNodes" SG_ 2151219200 RmVehStrRq 1;
BA_ "GenSigSendType" SG_ 2150514688 SldngDrRgtStat 10;
BA_ "GenSigSendOnInit" SG_ 2150514688 SldngDrRgtStat 1;
BA_ "SignalType" SG_ 2150514688 SldngDrRgtStat "ENM";
BA_ "SignalLongName" SG_ 2150514688 SldngDrRgtStat "Sliding Door Right Status";
BA_ "VNSigAllNodes" SG_ 2150514688 SldngDrRgtStat 1;
BA_ "GenSigSendType" SG_ 2150514688 SldngDrLftStat 10;
BA_ "GenSigSendOnInit" SG_ 2150514688 SldngDrLftStat 1;
BA_ "SignalType" SG_ 2150514688 SldngDrLftStat "ENM";
BA_ "SignalLongName" SG_ 2150514688 SldngDrLftStat "Sliding Door Left Status";
BA_ "VNSigAllNodes" SG_ 2150514688 SldngDrLftStat 1;
BA_ "GenSigSendType" SG_ 2150514688 SdClsrObstclDtctdStat 10;
BA_ "GenSigSendOnInit" SG_ 2150514688 SdClsrObstclDtctdStat 1;
BA_ "SignalType" SG_ 2150514688 SdClsrObstclDtctdStat "BLN";
BA_ "SignalLongName" SG_ 2150514688 SdClsrObstclDtctdStat "Side Closure Obstacle Detected Status";
BA_ "VNSigAllNodes" SG_ 2150514688 SdClsrObstclDtctdStat 1;
BA_ "GenSigSendType" SG_ 2150514688 PwrSldngDrUnavlblIO 10;
BA_ "SignalType" SG_ 2150514688 PwrSldngDrUnavlblIO "BLN";
BA_ "SignalLongName" SG_ 2150514688 PwrSldngDrUnavlblIO "Power Sliding Door Unavailable Indication On";
BA_ "VNSigAllNodes" SG_ 2150514688 PwrSldngDrUnavlblIO 1;
BA_ "GenSigSendType" SG_ 2155208704 SftTpPlsDnWrngIndOn 10;
BA_ "SignalType" SG_ 2155208704 SftTpPlsDnWrngIndOn "BLN";
BA_ "SignalLongName" SG_ 2155208704 SftTpPlsDnWrngIndOn "Soft Top Pulse Down Warning Indication On";
BA_ "VNSigAllNodes" SG_ 2155208704 SftTpPlsDnWrngIndOn 1;
BA_ "GenSigSendType" SG_ 2155208704 SftTpPlsDnSrtdIndOn 10;
BA_ "SignalType" SG_ 2155208704 SftTpPlsDnSrtdIndOn "BLN";
BA_ "SignalLongName" SG_ 2155208704 SftTpPlsDnSrtdIndOn "Soft Top Pulse Down Started Indication On";
BA_ "VNSigAllNodes" SG_ 2155208704 SftTpPlsDnSrtdIndOn 1;
BA_ "GenSigSendType" SG_ 2155208704 VltSwAtvIndOn 10;
BA_ "SignalType" SG_ 2155208704 VltSwAtvIndOn "BLN";
BA_ "SignalLongName" SG_ 2155208704 VltSwAtvIndOn "Valet Switch Active Indication On";
BA_ "VNSigAllNodes" SG_ 2155208704 VltSwAtvIndOn 1;
BA_ "GenSigSendType" SG_ 2155208704 SftTpVltLwIO 10;
BA_ "SignalType" SG_ 2155208704 SftTpVltLwIO "BLN";
BA_ "SignalLongName" SG_ 2155208704 SftTpVltLwIO "Soft Top Voltage Low Indication On";
BA_ "VNSigAllNodes" SG_ 2155208704 SftTpVltLwIO 1;
BA_ "GenSigSendType" SG_ 2155208704 SftTpVehOvSpdIndOn 10;
BA_ "SignalType" SG_ 2155208704 SftTpVehOvSpdIndOn "BLN";
BA_ "SignalLongName" SG_ 2155208704 SftTpVehOvSpdIndOn "Soft Top Vehicle Overspeed Indication On";
BA_ "VNSigAllNodes" SG_ 2155208704 SftTpVehOvSpdIndOn 1;
BA_ "GenSigSendType" SG_ 2155208704 SftTpTneuCvrIO 10;
BA_ "SignalType" SG_ 2155208704 SftTpTneuCvrIO "BLN";
BA_ "SignalLongName" SG_ 2155208704 SftTpTneuCvrIO "Soft Top Tonneau Cover Indication On";
BA_ "VNSigAllNodes" SG_ 2155208704 SftTpTneuCvrIO 1;
BA_ "GenSigSendType" SG_ 2155208704 SftTpTmpLwIO 10;
BA_ "SignalType" SG_ 2155208704 SftTpTmpLwIO "BLN";
BA_ "SignalLongName" SG_ 2155208704 SftTpTmpLwIO "Soft Top Temperature Low Indication On";
BA_ "VNSigAllNodes" SG_ 2155208704 SftTpTmpLwIO 1;
BA_ "GenSigSendType" SG_ 2155208704 SftTpStrIO 10;
BA_ "SignalType" SG_ 2155208704 SftTpStrIO "BLN";
BA_ "SignalLongName" SG_ 2155208704 SftTpStrIO "Soft Top Storage Indication On";
BA_ "VNSigAllNodes" SG_ 2155208704 SftTpStrIO 1;
BA_ "GenSigSendType" SG_ 2155208704 SftTpRmCrgCrrIO 10;
BA_ "SignalType" SG_ 2155208704 SftTpRmCrgCrrIO "BLN";
BA_ "SignalLongName" SG_ 2155208704 SftTpRmCrgCrrIO "Soft Top Remove Cargo Carrier Indication On";
BA_ "VNSigAllNodes" SG_ 2155208704 SftTpRmCrgCrrIO 1;
BA_ "GenSigSendType" SG_ 2155208704 SftTpMnlLtchIndOn 10;
BA_ "SignalType" SG_ 2155208704 SftTpMnlLtchIndOn "BLN";
BA_ "SignalLongName" SG_ 2155208704 SftTpMnlLtchIndOn "Soft Top Manual Latch Indication On";
BA_ "VNSigAllNodes" SG_ 2155208704 SftTpMnlLtchIndOn 1;
BA_ "GenSigSendType" SG_ 2155208704 SftTpMchnOvhtIO 10;
BA_ "SignalType" SG_ 2155208704 SftTpMchnOvhtIO "BLN";
BA_ "SignalLongName" SG_ 2155208704 SftTpMchnOvhtIO "Soft Top Mechanism Overheated Indication On";
BA_ "VNSigAllNodes" SG_ 2155208704 SftTpMchnOvhtIO 1;
BA_ "GenSigSendType" SG_ 2155208704 SftTpLtcIO 10;
BA_ "SignalType" SG_ 2155208704 SftTpLtcIO "BLN";
BA_ "SignalLongName" SG_ 2155208704 SftTpLtcIO "Soft Top Latch Indication On";
BA_ "VNSigAllNodes" SG_ 2155208704 SftTpLtcIO 1;
BA_ "GenSigSendType" SG_ 2155208704 SftTpFlrIO 10;
BA_ "SignalType" SG_ 2155208704 SftTpFlrIO "BLN";
BA_ "SignalLongName" SG_ 2155208704 SftTpFlrIO "Soft Top Failure Indication On";
BA_ "VNSigAllNodes" SG_ 2155208704 SftTpFlrIO 1;
BA_ "GenSigSendType" SG_ 2155208704 SftTpAbvWrngSpdIndOn 10;
BA_ "SignalType" SG_ 2155208704 SftTpAbvWrngSpdIndOn "BLN";
BA_ "SignalLongName" SG_ 2155208704 SftTpAbvWrngSpdIndOn "Soft Top Above Warning Speed Indication On";
BA_ "VNSigAllNodes" SG_ 2155208704 SftTpAbvWrngSpdIndOn 1;
BA_ "GenSigSendType" SG_ 2155208704 FldngTpSt 10;
BA_ "GenSigSendOnInit" SG_ 2155208704 FldngTpSt 1;
BA_ "SignalType" SG_ 2155208704 FldngTpSt "ENM";
BA_ "SignalLongName" SG_ 2155208704 FldngTpSt "Folding Top State";
BA_ "VNSigAllNodes" SG_ 2155208704 FldngTpSt 1;
BA_ "GenSigSendType" SG_ 2155208704 ClsTrnkLidIO 10;
BA_ "SignalType" SG_ 2155208704 ClsTrnkLidIO "BLN";
BA_ "SignalLongName" SG_ 2155208704 ClsTrnkLidIO "Close Trunk Lid Indication On";
BA_ "VNSigAllNodes" SG_ 2155208704 ClsTrnkLidIO 1;
BA_ "GenSigSendType" SG_ 2155208704 CkSoftTpIO 10;
BA_ "SignalType" SG_ 2155208704 CkSoftTpIO "BLN";
BA_ "SignalLongName" SG_ 2155208704 CkSoftTpIO "Check Soft Top Indication On";
BA_ "VNSigAllNodes" SG_ 2155208704 CkSoftTpIO 1;
BA_ "GenSigSendType" SG_ 2155208704 SftTpTrnLmpsRqd 10;
BA_ "SignalType" SG_ 2155208704 SftTpTrnLmpsRqd "BLN";
BA_ "SignalLongName" SG_ 2155208704 SftTpTrnLmpsRqd "Soft Top Turn Lamps Requested";
BA_ "VNSigAllNodes" SG_ 2155208704 SftTpTrnLmpsRqd 1;
BA_ "GenSigSendType" SG_ 2155208704 FldngTpWndCmftRq 10;
BA_ "SignalType" SG_ 2155208704 FldngTpWndCmftRq "ENM";
BA_ "SignalLongName" SG_ 2155208704 FldngTpWndCmftRq "Folding Top Window Comfort Request";
BA_ "VNSigAllNodes" SG_ 2155208704 FldngTpWndCmftRq 1;
BA_ "GenSigSendType" SG_ 2155208704 FTUpdWndPsLmtEnbld 10;
BA_ "GenSigSendOnInit" SG_ 2155208704 FTUpdWndPsLmtEnbld 1;
BA_ "SignalType" SG_ 2155208704 FTUpdWndPsLmtEnbld "BLN";
BA_ "SignalLongName" SG_ 2155208704 FTUpdWndPsLmtEnbld "Folding Top Upward Window Position Limit Enable";
BA_ "VNSigAllNodes" SG_ 2155208704 FTUpdWndPsLmtEnbld 1;
BA_ "GenSigDeltaValue" SG_ 2151530496 HVBTBDCSRR1_DChMHSRq 1;
BA_ "GenSigSendType" SG_ 2151530496 HVBTBDCSRR1_DChMHSRq 12;
BA_ "VNSigInfotainment" SG_ 2151530496 HVBTBDCSRR1_DChMHSRq 1;
BA_ "SignalType" SG_ 2151530496 HVBTBDCSRR1_DChMHSRq "UNM";
BA_ "PacketOrder" SG_ 2151530496 HVBTBDCSRR1_DChMHSRq 5;
BA_ "SignalLongName" SG_ 2151530496 HVBTBDCSRR1_DChMHSRq "High Voltage Battery Time Based Delayed Charging Set Request Remote 1 : Delayed Charging Minute of Hour Set Request";
BA_ "VNSigAllNodes" SG_ 2151530496 HVBTBDCSRR1_DChMHSRq 1;
BA_ "GenSigSendType" SG_ 2151530496 HVBTBDCSRR1_DChSnSRq 10;
BA_ "VNSigInfotainment" SG_ 2151530496 HVBTBDCSRR1_DChSnSRq 1;
BA_ "SignalType" SG_ 2151530496 HVBTBDCSRR1_DChSnSRq "ENM";
BA_ "PacketOrder" SG_ 2151530496 HVBTBDCSRR1_DChSnSRq 4;
BA_ "SignalLongName" SG_ 2151530496 HVBTBDCSRR1_DChSnSRq "High Voltage Battery Time Based Delayed Charging Set Request Remote 1 : Delayed Charging Season Set Request";
BA_ "VNSigAllNodes" SG_ 2151530496 HVBTBDCSRR1_DChSnSRq 1;
BA_ "GenSigSendType" SG_ 2151530496 HVBTBDCSRR1_DChSlSRq 10;
BA_ "VNSigInfotainment" SG_ 2151530496 HVBTBDCSRR1_DChSlSRq 1;
BA_ "SignalType" SG_ 2151530496 HVBTBDCSRR1_DChSlSRq "ENM";
BA_ "PacketOrder" SG_ 2151530496 HVBTBDCSRR1_DChSlSRq 3;
BA_ "SignalLongName" SG_ 2151530496 HVBTBDCSRR1_DChSlSRq "High Voltage Battery Time Based Delayed Charging Set Request Remote 1 : Delayed Charging Selected Set Request";
BA_ "VNSigAllNodes" SG_ 2151530496 HVBTBDCSRR1_DChSlSRq 1;
BA_ "GenSigSendType" SG_ 2151530496 HVBTBDCSRR1_DChDStRq 10;
BA_ "VNSigInfotainment" SG_ 2151530496 HVBTBDCSRR1_DChDStRq 1;
BA_ "SignalType" SG_ 2151530496 HVBTBDCSRR1_DChDStRq "ENM";
BA_ "PacketOrder" SG_ 2151530496 HVBTBDCSRR1_DChDStRq 2;
BA_ "SignalLongName" SG_ 2151530496 HVBTBDCSRR1_DChDStRq "High Voltage Battery Time Based Delayed Charging Set Request Remote 1 : Delayed Charging Day Set Request";
BA_ "VNSigAllNodes" SG_ 2151530496 HVBTBDCSRR1_DChDStRq 1;
BA_ "GenSigDeltaValue" SG_ 2151530496 HVBTBDCSRR1_DChHStRq 1;
BA_ "GenSigSendType" SG_ 2151530496 HVBTBDCSRR1_DChHStRq 12;
BA_ "VNSigInfotainment" SG_ 2151530496 HVBTBDCSRR1_DChHStRq 1;
BA_ "SignalType" SG_ 2151530496 HVBTBDCSRR1_DChHStRq "UNM";
BA_ "PacketOrder" SG_ 2151530496 HVBTBDCSRR1_DChHStRq 1;
BA_ "SignalLongName" SG_ 2151530496 HVBTBDCSRR1_DChHStRq "High Voltage Battery Time Based Delayed Charging Set Request Remote 1 : Delayed Charging Hour Set Request";
BA_ "VNSigAllNodes" SG_ 2151530496 HVBTBDCSRR1_DChHStRq 1;
BA_ "GenSigSendType" SG_ 2151530496 HVBatTmBsChgMdRqRmt1 10;
BA_ "VNSigInfotainment" SG_ 2151530496 HVBatTmBsChgMdRqRmt1 1;
BA_ "SignalType" SG_ 2151530496 HVBatTmBsChgMdRqRmt1 "ENM";
BA_ "SignalLongName" SG_ 2151530496 HVBatTmBsChgMdRqRmt1 "High Voltage Battery Time Based Charging Mode Request Remote 1";
BA_ "VNSigAllNodes" SG_ 2151530496 HVBatTmBsChgMdRqRmt1 1;
BA_ "GenSigSendType" SG_ 2151530496 HVChgSyChgLvPfStRmt1 10;
BA_ "VNSigInfotainment" SG_ 2151530496 HVChgSyChgLvPfStRmt1 1;
BA_ "SignalType" SG_ 2151530496 HVChgSyChgLvPfStRmt1 "ENM";
BA_ "SignalLongName" SG_ 2151530496 HVChgSyChgLvPfStRmt1 "High Voltage Charging System Charge Level Preference Setting Remote 1";
BA_ "VNSigAllNodes" SG_ 2151530496 HVChgSyChgLvPfStRmt1 1;
BA_ "GenSigSendType" SG_ 2151530496 StTODChrgTmpOvrdRmt1 10;
BA_ "VNSigInfotainment" SG_ 2151530496 StTODChrgTmpOvrdRmt1 1;
BA_ "SignalType" SG_ 2151530496 StTODChrgTmpOvrdRmt1 "ENM";
BA_ "SignalLongName" SG_ 2151530496 StTODChrgTmpOvrdRmt1 "Set Time of Day Charge Temporary Override Remote 1";
BA_ "VNSigAllNodes" SG_ 2151530496 StTODChrgTmpOvrdRmt1 1;
BA_ "GenSigSendType" SG_ 2151530496 PrtyChrgRqRmt1 10;
BA_ "VNSigInfotainment" SG_ 2151530496 PrtyChrgRqRmt1 1;
BA_ "SignalType" SG_ 2151530496 PrtyChrgRqRmt1 "ENM";
BA_ "SignalLongName" SG_ 2151530496 PrtyChrgRqRmt1 "Priority Charging Request Remote 1";
BA_ "VNSigAllNodes" SG_ 2151530496 PrtyChrgRqRmt1 1;
BA_ "GenSigSendType" SG_ 2151530496 OfBrdHVCVhCsChRqRmt1 10;
BA_ "VNSigInfotainment" SG_ 2151530496 OfBrdHVCVhCsChRqRmt1 1;
BA_ "SignalType" SG_ 2151530496 OfBrdHVCVhCsChRqRmt1 "BLN";
BA_ "SignalLongName" SG_ 2151530496 OfBrdHVCVhCsChRqRmt1 "Off Board High Voltage Charging Vehicle Cease Charging Requested Remote 1";
BA_ "VNSigAllNodes" SG_ 2151530496 OfBrdHVCVhCsChRqRmt1 1;
BA_ "GenSigSendType" SG_ 2151530496 TireTrdTmpStat 10;
BA_ "SignalType" SG_ 2151530496 TireTrdTmpStat "ENM";
BA_ "SignalLongName" SG_ 2151530496 TireTrdTmpStat "Tire Tread Temperature Status";
BA_ "VNSigAllNodes" SG_ 2151530496 TireTrdTmpStat 1;
BA_ "GenSigSendType" SG_ 2151530496 TrPrsMntrTrLdStat 10;
BA_ "SignalType" SG_ 2151530496 TrPrsMntrTrLdStat "ENM";
BA_ "SignalLongName" SG_ 2151530496 TrPrsMntrTrLdStat "Tire Pressure Monitoring Tire Loading Status";
BA_ "VNSigAllNodes" SG_ 2151530496 TrPrsMntrTrLdStat 1;
BA_ "GenSigSendType" SG_ 2151530496 TrPrsMntrAtLocFld 10;
BA_ "SignalType" SG_ 2151530496 TrPrsMntrAtLocFld "BLN";
BA_ "SignalLongName" SG_ 2151530496 TrPrsMntrAtLocFld "Tire Pressure Monitoring Autolocation System Failed";
BA_ "VNSigAllNodes" SG_ 2151530496 TrPrsMntrAtLocFld 1;
BA_ "GenSigSendType" SG_ 2151530496 TireLocatnWarnEn 10;
BA_ "SignalType" SG_ 2151530496 TireLocatnWarnEn "BLN";
BA_ "SignalLongName" SG_ 2151530496 TireLocatnWarnEn "Tire Location Warnings Enabled";
BA_ "VNSigAllNodes" SG_ 2151530496 TireLocatnWarnEn 1;
BA_ "GenSigSendType" SG_ 2151530496 WintTrRecIndOn 10;
BA_ "SignalType" SG_ 2151530496 WintTrRecIndOn "BLN";
BA_ "SignalLongName" SG_ 2151530496 WintTrRecIndOn "Winter Tire Recognition Indication On";
BA_ "VNSigAllNodes" SG_ 2151530496 WintTrRecIndOn 1;
BA_ "GenSigSendType" SG_ 2151530496 TrPrsMntrFld 10;
BA_ "SignalType" SG_ 2151530496 TrPrsMntrFld "BLN";
BA_ "SignalLongName" SG_ 2151530496 TrPrsMntrFld "Tire Pressure Monitoring System Failed";
BA_ "VNSigAllNodes" SG_ 2151530496 TrPrsMntrFld 1;
BA_ "GenSigSendType" SG_ 2151530496 TrRrAxlPresStat 10;
BA_ "SignalType" SG_ 2151530496 TrRrAxlPresStat "ENM";
BA_ "SignalLongName" SG_ 2151530496 TrRrAxlPresStat "Tire Rear Axle Pressure Status";
BA_ "VNSigAllNodes" SG_ 2151530496 TrRrAxlPresStat 1;
BA_ "GenSigSendType" SG_ 2151530496 TrFrntAxlPresStat 10;
BA_ "SignalType" SG_ 2151530496 TrFrntAxlPresStat "ENM";
BA_ "SignalLongName" SG_ 2151530496 TrFrntAxlPresStat "Tire Front Axle Pressure Status";
BA_ "VNSigAllNodes" SG_ 2151530496 TrFrntAxlPresStat 1;
BA_ "GenSigSendType" SG_ 2151530496 TPMTrLrnMdCmplt 10;
BA_ "GenSigSendOnInit" SG_ 2151530496 TPMTrLrnMdCmplt 2;
BA_ "SignalType" SG_ 2151530496 TPMTrLrnMdCmplt "BLN";
BA_ "SignalLongName" SG_ 2151530496 TPMTrLrnMdCmplt "Tire Pressure Monitoring Tire Learn Mode Complete";
BA_ "GenSigStartValue" SG_ 2151530496 TPMTrLrnMdCmplt 1;
BA_ "VNSigAllNodes" SG_ 2151530496 TPMTrLrnMdCmplt 1;
BA_ "GenSigDeltaValue" SG_ 2151497728 TireLFPrs 1;
BA_ "GenSigSendType" SG_ 2151497728 TireLFPrs 12;
BA_ "GenSigSendOnInit" SG_ 2151497728 TireLFPrs 1;
BA_ "SignalType" SG_ 2151497728 TireLFPrs "UNM";
BA_ "SignalLongName" SG_ 2151497728 TireLFPrs "Tire Left Front Pressure";
BA_ "GenSigStartValue" SG_ 2151497728 TireLFPrs 255;
BA_ "VNSigAllNodes" SG_ 2151497728 TireLFPrs 1;
BA_ "GenSigSendType" SG_ 2151497728 TireLFPrsStat 10;
BA_ "GenSigSendOnInit" SG_ 2151497728 TireLFPrsStat 1;
BA_ "SignalType" SG_ 2151497728 TireLFPrsStat "ENM";
BA_ "SignalLongName" SG_ 2151497728 TireLFPrsStat "Tire Left Front Pressure Status";
BA_ "VNSigAllNodes" SG_ 2151497728 TireLFPrsStat 1;
BA_ "GenSigSendType" SG_ 2151497728 TireLFPrsV 10;
BA_ "GenSigSendOnInit" SG_ 2151497728 TireLFPrsV 1;
BA_ "SignalType" SG_ 2151497728 TireLFPrsV "ENM";
BA_ "SignalLongName" SG_ 2151497728 TireLFPrsV "Tire Left Front Pressure Validity";
BA_ "VNSigAllNodes" SG_ 2151497728 TireLFPrsV 1;
BA_ "GenSigDeltaValue" SG_ 2151497728 TireLRPrs 1;
BA_ "GenSigSendType" SG_ 2151497728 TireLRPrs 12;
BA_ "GenSigSendOnInit" SG_ 2151497728 TireLRPrs 1;
BA_ "SignalType" SG_ 2151497728 TireLRPrs "UNM";
BA_ "SignalLongName" SG_ 2151497728 TireLRPrs "Tire Left Rear Pressure";
BA_ "GenSigStartValue" SG_ 2151497728 TireLRPrs 255;
BA_ "VNSigAllNodes" SG_ 2151497728 TireLRPrs 1;
BA_ "GenSigSendType" SG_ 2151497728 TireLRPrsStat 10;
BA_ "GenSigSendOnInit" SG_ 2151497728 TireLRPrsStat 1;
BA_ "SignalType" SG_ 2151497728 TireLRPrsStat "ENM";
BA_ "SignalLongName" SG_ 2151497728 TireLRPrsStat "Tire Left Rear Pressure Status";
BA_ "VNSigAllNodes" SG_ 2151497728 TireLRPrsStat 1;
BA_ "GenSigSendType" SG_ 2151497728 TireLRPrsV 10;
BA_ "GenSigSendOnInit" SG_ 2151497728 TireLRPrsV 1;
BA_ "SignalType" SG_ 2151497728 TireLRPrsV "ENM";
BA_ "SignalLongName" SG_ 2151497728 TireLRPrsV "Tire Left Rear Pressure Validity";
BA_ "VNSigAllNodes" SG_ 2151497728 TireLRPrsV 1;
BA_ "GenSigDeltaValue" SG_ 2151497728 TireRFPrs 1;
BA_ "GenSigSendType" SG_ 2151497728 TireRFPrs 12;
BA_ "GenSigSendOnInit" SG_ 2151497728 TireRFPrs 1;
BA_ "SignalType" SG_ 2151497728 TireRFPrs "UNM";
BA_ "SignalLongName" SG_ 2151497728 TireRFPrs "Tire Right Front Pressure";
BA_ "GenSigStartValue" SG_ 2151497728 TireRFPrs 255;
BA_ "VNSigAllNodes" SG_ 2151497728 TireRFPrs 1;
BA_ "GenSigSendType" SG_ 2151497728 TireRFPrsStat 10;
BA_ "GenSigSendOnInit" SG_ 2151497728 TireRFPrsStat 1;
BA_ "SignalType" SG_ 2151497728 TireRFPrsStat "ENM";
BA_ "SignalLongName" SG_ 2151497728 TireRFPrsStat "Tire Right Front Pressure Status";
BA_ "VNSigAllNodes" SG_ 2151497728 TireRFPrsStat 1;
BA_ "GenSigSendType" SG_ 2151497728 TireRFPrsV 10;
BA_ "GenSigSendOnInit" SG_ 2151497728 TireRFPrsV 1;
BA_ "SignalType" SG_ 2151497728 TireRFPrsV "ENM";
BA_ "SignalLongName" SG_ 2151497728 TireRFPrsV "Tire Right Front Pressure Validity";
BA_ "VNSigAllNodes" SG_ 2151497728 TireRFPrsV 1;
BA_ "GenSigDeltaValue" SG_ 2151497728 TireRRPrs 1;
BA_ "GenSigSendType" SG_ 2151497728 TireRRPrs 12;
BA_ "GenSigSendOnInit" SG_ 2151497728 TireRRPrs 1;
BA_ "SignalType" SG_ 2151497728 TireRRPrs "UNM";
BA_ "SignalLongName" SG_ 2151497728 TireRRPrs "Tire Right Rear Pressure";
BA_ "GenSigStartValue" SG_ 2151497728 TireRRPrs 255;
BA_ "VNSigAllNodes" SG_ 2151497728 TireRRPrs 1;
BA_ "GenSigSendType" SG_ 2151497728 TireRRPrsStat 10;
BA_ "GenSigSendOnInit" SG_ 2151497728 TireRRPrsStat 1;
BA_ "SignalType" SG_ 2151497728 TireRRPrsStat "ENM";
BA_ "SignalLongName" SG_ 2151497728 TireRRPrsStat "Tire Right Rear Pressure Status";
BA_ "VNSigAllNodes" SG_ 2151497728 TireRRPrsStat 1;
BA_ "GenSigSendType" SG_ 2151497728 TireRRPrsV 10;
BA_ "GenSigSendOnInit" SG_ 2151497728 TireRRPrsV 1;
BA_ "SignalType" SG_ 2151497728 TireRRPrsV "ENM";
BA_ "SignalLongName" SG_ 2151497728 TireRRPrsV "Tire Right Rear Pressure Validity";
BA_ "VNSigAllNodes" SG_ 2151497728 TireRRPrsV 1;
BA_ "GenSigSendType" SG_ 2150588416 PDAjrSwAtv 10;
BA_ "GenSigSendOnInit" SG_ 2150588416 PDAjrSwAtv 2;
BA_ "VNSigInfotainment" SG_ 2150588416 PDAjrSwAtv 1;
BA_ "SignalType" SG_ 2150588416 PDAjrSwAtv "BLN";
BA_ "SignalLongName" SG_ 2150588416 PDAjrSwAtv "Passenger Door Ajar Switch Active";
BA_ "VNSigAllNodes" SG_ 2150588416 PDAjrSwAtv 1;
BA_ "GenSigSendType" SG_ 2150916096 PrkHtrCoolntTempM 10;
BA_ "VNSigIntermediate" SG_ 2150916096 PrkHtrCoolntTempM 1;
BA_ "SignalType" SG_ 2150916096 PrkHtrCoolntTempM "ENM";
BA_ "SignalLongName" SG_ 2150916096 PrkHtrCoolntTempM "Park Heater Coolant Temperature Mask";
BA_ "VNSigAllNodes" SG_ 2150916096 PrkHtrCoolntTempM 1;
BA_ "GenSigSendType" SG_ 2150916096 PrkHtrPrhtAch 10;
BA_ "GenSigSendOnInit" SG_ 2150916096 PrkHtrPrhtAch 1;
BA_ "VNSigIntermediate" SG_ 2150916096 PrkHtrPrhtAch 1;
BA_ "SignalType" SG_ 2150916096 PrkHtrPrhtAch "BLN";
BA_ "SignalLongName" SG_ 2150916096 PrkHtrPrhtAch "Park Heater Preheat Achieved";
BA_ "VNSigAllNodes" SG_ 2150916096 PrkHtrPrhtAch 1;
BA_ "GenSigSendType" SG_ 2150916096 PrkHtrFlCnsmdRolCntV 10;
BA_ "GenSigSendOnInit" SG_ 2150916096 PrkHtrFlCnsmdRolCntV 1;
BA_ "SignalType" SG_ 2150916096 PrkHtrFlCnsmdRolCntV "ENM";
BA_ "SignalLongName" SG_ 2150916096 PrkHtrFlCnsmdRolCntV "Park Heater Fuel Consumed Rolling Count Validity";
BA_ "VNSigAllNodes" SG_ 2150916096 PrkHtrFlCnsmdRolCntV 1;
BA_ "GenSigSendType" SG_ 2150916096 PrkHtrFlCsmdRlCntRsOc 10;
BA_ "GenSigSendOnInit" SG_ 2150916096 PrkHtrFlCsmdRlCntRsOc 1;
BA_ "SignalType" SG_ 2150916096 PrkHtrFlCsmdRlCntRsOc "BLN";
BA_ "SignalLongName" SG_ 2150916096 PrkHtrFlCsmdRlCntRsOc "Park Heater Fuel Consumed Rolling Count Reset Occurred";
BA_ "VNSigAllNodes" SG_ 2150916096 PrkHtrFlCsmdRlCntRsOc 1;
BA_ "GenSigDeltaValue" SG_ 2150916096 PrkHtrFlCnsmdRolCnt 1;
BA_ "GenSigSendType" SG_ 2150916096 PrkHtrFlCnsmdRolCnt 12;
BA_ "GenSigSendOnInit" SG_ 2150916096 PrkHtrFlCnsmdRolCnt 1;
BA_ "SignalType" SG_ 2150916096 PrkHtrFlCnsmdRolCnt "UNM";
BA_ "SignalLongName" SG_ 2150916096 PrkHtrFlCnsmdRolCnt "Park Heater Fuel Consumed Rolling Count";
BA_ "VNSigAllNodes" SG_ 2150916096 PrkHtrFlCnsmdRolCnt 1;
BA_ "GenSigSendType" SG_ 2150916096 PrkHtrCoolntTempV 10;
BA_ "GenSigSendOnInit" SG_ 2150916096 PrkHtrCoolntTempV 1;
BA_ "VNSigIntermediate" SG_ 2150916096 PrkHtrCoolntTempV 1;
BA_ "SignalType" SG_ 2150916096 PrkHtrCoolntTempV "ENM";
BA_ "SignalLongName" SG_ 2150916096 PrkHtrCoolntTempV "Park Heater Coolant Temperature Validity";
BA_ "VNSigAllNodes" SG_ 2150916096 PrkHtrCoolntTempV 1;
BA_ "GenSigDeltaValue" SG_ 2150916096 PrkHtrCoolntTemp 1;
BA_ "GenSigSendType" SG_ 2150916096 PrkHtrCoolntTemp 12;
BA_ "GenSigSendOnInit" SG_ 2150916096 PrkHtrCoolntTemp 1;
BA_ "VNSigIntermediate" SG_ 2150916096 PrkHtrCoolntTemp 1;
BA_ "SignalType" SG_ 2150916096 PrkHtrCoolntTemp "UNM";
BA_ "SignalLongName" SG_ 2150916096 PrkHtrCoolntTemp "Park Heater Coolant Temperature";
BA_ "VNSigAllNodes" SG_ 2150916096 PrkHtrCoolntTemp 1;
BA_ "GenSigSendType" SG_ 2150916096 ClntCircPmpAct 10;
BA_ "GenSigSendOnInit" SG_ 2150916096 ClntCircPmpAct 1;
BA_ "VNSigIntermediate" SG_ 2150916096 ClntCircPmpAct 1;
BA_ "SignalType" SG_ 2150916096 ClntCircPmpAct "BLN";
BA_ "SignalLongName" SG_ 2150916096 ClntCircPmpAct "Coolant Circulation Pump Active";
BA_ "VNSigAllNodes" SG_ 2150916096 ClntCircPmpAct 1;
BA_ "GenSigSendType" SG_ 2150916096 PrkHtrAtv 10;
BA_ "GenSigSendOnInit" SG_ 2150916096 PrkHtrAtv 1;
BA_ "VNSigIntermediate" SG_ 2150916096 PrkHtrAtv 1;
BA_ "SignalType" SG_ 2150916096 PrkHtrAtv "BLN";
BA_ "SignalLongName" SG_ 2150916096 PrkHtrAtv "Park Heater Active";
BA_ "VNSigAllNodes" SG_ 2150916096 PrkHtrAtv 1;
BA_ "GenSigSendType" SG_ 2151366656 RrAxlLckIO 10;
BA_ "SignalType" SG_ 2151366656 RrAxlLckIO "BLN";
BA_ "SignalLongName" SG_ 2151366656 RrAxlLckIO "Rear Axle Lock Indication On";
BA_ "VNSigAllNodes" SG_ 2151366656 RrAxlLckIO 1;
BA_ "GenSigSendType" SG_ 2151366656 FrntAxlLckIO 10;
BA_ "SignalType" SG_ 2151366656 FrntAxlLckIO "BLN";
BA_ "SignalLongName" SG_ 2151366656 FrntAxlLckIO "Front Axle Lock Indication On";
BA_ "VNSigAllNodes" SG_ 2151366656 FrntAxlLckIO 1;
BA_ "GenSigSendType" SG_ 2151366656 AxlLcksServIO 10;
BA_ "SignalType" SG_ 2151366656 AxlLcksServIO "BLN";
BA_ "SignalLongName" SG_ 2151366656 AxlLcksServIO "Axle Locks Service Indication On";
BA_ "VNSigAllNodes" SG_ 2151366656 AxlLcksServIO 1;
BA_ "GenSigSendType" SG_ 2151366656 AxlLckUnavailIndReq 10;
BA_ "SignalType" SG_ 2151366656 AxlLckUnavailIndReq "ENM";
BA_ "SignalLongName" SG_ 2151366656 AxlLckUnavailIndReq "Axle Locks Unavailable Indication Request";
BA_ "VNSigAllNodes" SG_ 2151366656 AxlLckUnavailIndReq 1;
BA_ "GenSigSendType" SG_ 2151366656 AxlLcksVDA 10;
BA_ "SignalType" SG_ 2151366656 AxlLcksVDA "ENM";
BA_ "SignalLongName" SG_ 2151366656 AxlLcksVDA "Axle Locks Virtual Device Availability";
BA_ "GenSigStartValue" SG_ 2151366656 AxlLcksVDA 1;
BA_ "VNSigAllNodes" SG_ 2151366656 AxlLcksVDA 1;
BA_ "GenSigSendType" SG_ 2151366656 PrkBrkSwAtv 10;
BA_ "GenSigSendOnInit" SG_ 2151366656 PrkBrkSwAtv 1;
BA_ "SignalType" SG_ 2151366656 PrkBrkSwAtv "BLN";
BA_ "SignalLongName" SG_ 2151366656 PrkBrkSwAtv "Park Brake Switch Active";
BA_ "VNSigAllNodes" SG_ 2151366656 PrkBrkSwAtv 1;
BA_ "GenSigSendType" SG_ 2151284736 PrkAstOprtrDsrdStat_1D0 10;
BA_ "GenSigSendOnInit" SG_ 2151284736 PrkAstOprtrDsrdStat_1D0 2;
BA_ "SignalType" SG_ 2151284736 PrkAstOprtrDsrdStat_1D0 "ENM";
BA_ "SignalLongName" SG_ 2151284736 PrkAstOprtrDsrdStat_1D0 "Park Assistance Operator Desired Status";
BA_ "VNSigAllNodes" SG_ 2151284736 PrkAstOprtrDsrdStat_1D0 1;
BA_ "GenSigSendType" SG_ 2151284736 TnDrvPrkAstOffUnbIO 10;
BA_ "SignalType" SG_ 2151284736 TnDrvPrkAstOffUnbIO "BLN";
BA_ "SignalLongName" SG_ 2151284736 TnDrvPrkAstOffUnbIO "Teen Driver Park Assist Off Unavailable Indication On";
BA_ "VNSigAllNodes" SG_ 2151284736 TnDrvPrkAstOffUnbIO 1;
BA_ "GenSigSendType" SG_ 2151284736 PrkAstFld 10;
BA_ "SignalType" SG_ 2151284736 PrkAstFld "BLN";
BA_ "SignalLongName" SG_ 2151284736 PrkAstFld "Parking Assistance Failed";
BA_ "VNSigAllNodes" SG_ 2151284736 PrkAstFld 1;
BA_ "GenSigSendType" SG_ 2151284736 PrkAstSnsDistrbdIO 10;
BA_ "SignalType" SG_ 2151284736 PrkAstSnsDistrbdIO "BLN";
BA_ "SignalLongName" SG_ 2151284736 PrkAstSnsDistrbdIO "Parking Assistance Sensors Disturbed Indication On";
BA_ "VNSigAllNodes" SG_ 2151284736 PrkAstSnsDistrbdIO 1;
BA_ "GenSigSendType" SG_ 2151284736 PrkAsstDisablIO 10;
BA_ "GenSigSendOnInit" SG_ 2151284736 PrkAsstDisablIO 2;
BA_ "SignalType" SG_ 2151284736 PrkAsstDisablIO "BLN";
BA_ "SignalLongName" SG_ 2151284736 PrkAsstDisablIO "Parking Assistance Disabled Indication On";
BA_ "VNSigAllNodes" SG_ 2151284736 PrkAsstDisablIO 1;
BA_ "GenSigSendType" SG_ 2151284736 PrkAstSnrsBlk 10;
BA_ "SignalType" SG_ 2151284736 PrkAstSnrsBlk "BLN";
BA_ "SignalLongName" SG_ 2151284736 PrkAstSnrsBlk "Parking Assistance Sensors Blocked";
BA_ "VNSigAllNodes" SG_ 2151284736 PrkAstSnrsBlk 1;
BA_ "GenSigSendType" SG_ 2151284736 PrkAsstClnPrkAstIO 10;
BA_ "SignalType" SG_ 2151284736 PrkAsstClnPrkAstIO "BLN";
BA_ "SignalLongName" SG_ 2151284736 PrkAsstClnPrkAstIO "Parking Assistance Clean Parking Assist Indication On";
BA_ "VNSigAllNodes" SG_ 2151284736 PrkAsstClnPrkAstIO 1;
BA_ "GenSigSendType" SG_ 2150596608 RLDoorAjarSwAct 10;
BA_ "GenSigSendOnInit" SG_ 2150596608 RLDoorAjarSwAct 2;
BA_ "VNSigInfotainment" SG_ 2150596608 RLDoorAjarSwAct 1;
BA_ "SignalType" SG_ 2150596608 RLDoorAjarSwAct "BLN";
BA_ "SignalLongName" SG_ 2150596608 RLDoorAjarSwAct "Rear Left Door Ajar Switch Active";
BA_ "VNSigAllNodes" SG_ 2150596608 RLDoorAjarSwAct 1;
BA_ "SignalType" SG_ 2155380736 ServFuelSysTrnsfrPmpIO "BLN";
BA_ "SignalLongName" SG_ 2155380736 ServFuelSysTrnsfrPmpIO "Service Fuel System Transfer Pump Indication On";
BA_ "VNSigAllNodes" SG_ 2155380736 ServFuelSysTrnsfrPmpIO 1;
BA_ "SignalType" SG_ 2155380736 ACCmCltEngd "BLN";
BA_ "SignalLongName" SG_ 2155380736 ACCmCltEngd "Air Conditioning Compressor Clutch Engaged";
BA_ "VNSigAllNodes" SG_ 2155380736 ACCmCltEngd 1;
BA_ "SignalType" SG_ 2155380736 StrAsstRdcdLvl3IO "BLN";
BA_ "SignalLongName" SG_ 2155380736 StrAsstRdcdLvl3IO "Steering Assist Reduced Level 3 Indication On";
BA_ "VNSigAllNodes" SG_ 2155380736 StrAsstRdcdLvl3IO 1;
BA_ "SignalType" SG_ 2155380736 StrAsstRdcdLvl2IO "BLN";
BA_ "SignalLongName" SG_ 2155380736 StrAsstRdcdLvl2IO "Steering Assist Reduced Level 2 Indication On";
BA_ "VNSigAllNodes" SG_ 2155380736 StrAsstRdcdLvl2IO 1;
BA_ "SignalType" SG_ 2155380736 StrngAsstRdcdIO "BLN";
BA_ "SignalLongName" SG_ 2155380736 StrngAsstRdcdIO "Steering Assist Reduced Indication On";
BA_ "VNSigAllNodes" SG_ 2155380736 StrngAsstRdcdIO 1;
BA_ "SignalType" SG_ 2155380736 ARSFlrIO "BLN";
BA_ "SignalLongName" SG_ 2155380736 ARSFlrIO "Active Rear Steer Failure Indication On";
BA_ "VNSigAllNodes" SG_ 2155380736 ARSFlrIO 1;
BA_ "SignalType" SG_ 2155380736 PwrPkFnSpd "UNM";
BA_ "SignalLongName" SG_ 2155380736 PwrPkFnSpd "Power Pack Fan Speed";
BA_ "VNSigAllNodes" SG_ 2155380736 PwrPkFnSpd 1;
BA_ "SignalType" SG_ 2155380736 PwrPckAirInTempFlt "UNM";
BA_ "SignalLongName" SG_ 2155380736 PwrPckAirInTempFlt "Power Pack Air Inlet Temperature Filtered";
BA_ "VNSigAllNodes" SG_ 2155380736 PwrPckAirInTempFlt 1;
BA_ "SignalType" SG_ 2155380736 PTExPrtclFltrWrn2IO "BLN";
BA_ "SignalLongName" SG_ 2155380736 PTExPrtclFltrWrn2IO "Powertrain Exhaust Particle Filter Warning 2 Indication On";
BA_ "VNSigAllNodes" SG_ 2155380736 PTExPrtclFltrWrn2IO 1;
BA_ "SignalType" SG_ 2155380736 EngOilHotIO "BLN";
BA_ "SignalLongName" SG_ 2155380736 EngOilHotIO "Engine Oil Hot Indication On";
BA_ "VNSigAllNodes" SG_ 2155380736 EngOilHotIO 1;
BA_ "SignalType" SG_ 2155380736 RrLevVDA "ENM";
BA_ "SignalLongName" SG_ 2155380736 RrLevVDA "Rear Leveling Virtual Device Availability";
BA_ "GenSigStartValue" SG_ 2155380736 RrLevVDA 1;
BA_ "VNSigAllNodes" SG_ 2155380736 RrLevVDA 1;
BA_ "SignalType" SG_ 2155380736 EngWtrInFlIO "BLN";
BA_ "SignalLongName" SG_ 2155380736 EngWtrInFlIO "Engine Water In Fuel Indication On";
BA_ "VNSigAllNodes" SG_ 2155380736 EngWtrInFlIO 1;
BA_ "SignalType" SG_ 2155380736 AdvFrntLghtSysIndRq "ENM";
BA_ "SignalLongName" SG_ 2155380736 AdvFrntLghtSysIndRq "Advanced Front Lighting System Indication Request";
BA_ "VNSigAllNodes" SG_ 2155380736 AdvFrntLghtSysIndRq 1;
BA_ "SignalType" SG_ 2155380736 PTExPrtclFltrWrnIO "BLN";
BA_ "SignalLongName" SG_ 2155380736 PTExPrtclFltrWrnIO "Powertrain Exhaust Particle Filter Warning Indication On";
BA_ "VNSigAllNodes" SG_ 2155380736 PTExPrtclFltrWrnIO 1;
BA_ "SignalType" SG_ 2155380736 AirCndOffIO "BLN";
BA_ "SignalLongName" SG_ 2155380736 AirCndOffIO "Air Conditioning Off Indication On";
BA_ "VNSigAllNodes" SG_ 2155380736 AirCndOffIO 1;
BA_ "SignalType" SG_ 2155380736 HdLtLvlFlrIO "BLN";
BA_ "SignalLongName" SG_ 2155380736 HdLtLvlFlrIO "Head Light Leveling Failure Indication On";
BA_ "VNSigAllNodes" SG_ 2155380736 HdLtLvlFlrIO 1;
BA_ "SignalType" SG_ 2155380736 PwrStrIO "BLN";
BA_ "SignalLongName" SG_ 2155380736 PwrStrIO "Power Steering Indication On";
BA_ "VNSigAllNodes" SG_ 2155380736 PwrStrIO 1;
BA_ "SignalType" SG_ 2155380736 EngHt_StpEngIO "BLN";
BA_ "SignalLongName" SG_ 2155380736 EngHt_StpEngIO "Engine Hot / Stop Engine Indication On";
BA_ "VNSigAllNodes" SG_ 2155380736 EngHt_StpEngIO 1;
BA_ "SignalType" SG_ 2155380736 CkFlFilrCapIO "BLN";
BA_ "SignalLongName" SG_ 2155380736 CkFlFilrCapIO "Check Fuel Filler Cap Indication On";
BA_ "VNSigAllNodes" SG_ 2155380736 CkFlFilrCapIO 1;
BA_ "SignalType" SG_ 2155380736 RdcdPwrIO "BLN";
BA_ "SignalLongName" SG_ 2155380736 RdcdPwrIO "Reduced Power Indication On";
BA_ "VNSigAllNodes" SG_ 2155380736 RdcdPwrIO 1;
BA_ "SignalType" SG_ 2155380736 EngOilPrsLwIO "BLN";
BA_ "SignalLongName" SG_ 2155380736 EngOilPrsLwIO "Engine Oil Pressure Low Indication On";
BA_ "VNSigAllNodes" SG_ 2155380736 EngOilPrsLwIO 1;
BA_ "SignalType" SG_ 2155380736 EngOilLvlLwIO "BLN";
BA_ "SignalLongName" SG_ 2155380736 EngOilLvlLwIO "Engine Oil Level Low Indication On";
BA_ "VNSigAllNodes" SG_ 2155380736 EngOilLvlLwIO 1;
BA_ "SignalType" SG_ 2155380736 EngOilChngIO "BLN";
BA_ "SignalLongName" SG_ 2155380736 EngOilChngIO "Engine Oil Change Indication On";
BA_ "VNSigAllNodes" SG_ 2155380736 EngOilChngIO 1;
BA_ "SignalType" SG_ 2155380736 EngHotFuelEnrchmntIO "BLN";
BA_ "SignalLongName" SG_ 2155380736 EngHotFuelEnrchmntIO "Engine Hot Fuel Enrichment Indication On";
BA_ "VNSigAllNodes" SG_ 2155380736 EngHotFuelEnrchmntIO 1;
BA_ "GenSigSendType" SG_ 2155380736 DslGlwPlgIO 10;
BA_ "SignalType" SG_ 2155380736 DslGlwPlgIO "BLN";
BA_ "SignalLongName" SG_ 2155380736 DslGlwPlgIO "Diesel Glow Plug Indication On";
BA_ "VNSigAllNodes" SG_ 2155380736 DslGlwPlgIO 1;
BA_ "SignalType" SG_ 2155380736 SrvLevSysIO "BLN";
BA_ "SignalLongName" SG_ 2155380736 SrvLevSysIO "Service Leveling System Indication On";
BA_ "VNSigAllNodes" SG_ 2155380736 SrvLevSysIO 1;
BA_ "SignalType" SG_ 2155380736 VehOvrLdIndOn "BLN";
BA_ "SignalLongName" SG_ 2155380736 VehOvrLdIndOn "Vehicle Overloaded Indication On";
BA_ "VNSigAllNodes" SG_ 2155380736 VehOvrLdIndOn 1;
BA_ "GenSigDeltaValue" SG_ 2154856448 HmdtySnsrTemp 1;
BA_ "GenSigSendType" SG_ 2154856448 HmdtySnsrTemp 12;
BA_ "SignalType" SG_ 2154856448 HmdtySnsrTemp "UNM";
BA_ "SignalLongName" SG_ 2154856448 HmdtySnsrTemp "Humidity Sensor Temperature";
BA_ "VNSigAllNodes" SG_ 2154856448 HmdtySnsrTemp 1;
BA_ "GenSigDeltaValue" SG_ 2154856448 HmdtySnsrRltvHmdty 1;
BA_ "GenSigSendType" SG_ 2154856448 HmdtySnsrRltvHmdty 12;
BA_ "SignalType" SG_ 2154856448 HmdtySnsrRltvHmdty "UNM";
BA_ "SignalLongName" SG_ 2154856448 HmdtySnsrRltvHmdty "Humidity Sensor Relative Humidity";
BA_ "VNSigAllNodes" SG_ 2154856448 HmdtySnsrRltvHmdty 1;
BA_ "GenSigDeltaValue" SG_ 2154856448 HmdtySnsrGlssTemp 1;
BA_ "GenSigSendType" SG_ 2154856448 HmdtySnsrGlssTemp 12;
BA_ "SignalType" SG_ 2154856448 HmdtySnsrGlssTemp "UNM";
BA_ "SignalLongName" SG_ 2154856448 HmdtySnsrGlssTemp "Humidity Sensor Glass Temperature";
BA_ "VNSigAllNodes" SG_ 2154856448 HmdtySnsrGlssTemp 1;
BA_REL_ "GenSigSuprvResp" BU_SG_REL_ CSM_LE SG_ 2153308160 RdHVltBatPckVlt 1;
BA_REL_ "GenSigSuprvResp" BU_SG_REL_ RadioHead_LE SG_ 2153308160 RdHVltBatPckVlt 1;
BA_REL_ "GenSigSuprvResp" BU_SG_REL_ VCU_LE SG_ 2153308160 RdHVltBatPckVlt 1;
BA_REL_ "GenSigSuprvResp" BU_SG_REL_ VCU_LE SG_ 2153308160 RdHVltBatPckVlt 1;
BA_REL_ "GenSigSuprvResp" BU_SG_REL_ IPC_LE SG_ 2153308160 RdHVltBatPckVlt 1;
BA_REL_ "GenSigSuprvResp" BU_SG_REL_ CSM_LE SG_ 2153308160 RdHVltBatPckCrnt 1;
BA_REL_ "GenSigSuprvResp" BU_SG_REL_ RadioHead_LE SG_ 2153308160 RdHVltBatPckCrnt 1;
BA_REL_ "GenSigSuprvResp" BU_SG_REL_ VCU_LE SG_ 2153308160 RdHVltBatPckCrnt 1;
BA_REL_ "GenSigSuprvResp" BU_SG_REL_ VCU_LE SG_ 2153308160 RdHVltBatPckCrnt 1;
BA_REL_ "GenSigSuprvResp" BU_SG_REL_ IPC_LE SG_ 2153308160 RdHVltBatPckCrnt 1;
BA_REL_ "GenSigSuprvResp" BU_SG_REL_ VCU_LE SG_ 2149924864 PTOMobModTrnsInGrIO 1;
BA_REL_ "GenSigSuprvResp" BU_SG_REL_ IPC_LE SG_ 2149924864 PTOMobModTrnsInGrIO 1;
BA_REL_ "GenSigSuprvResp" BU_SG_REL_ VCU_LE SG_ 2149924864 TireRRLowTracIO 1;
BA_REL_ "GenSigSuprvResp" BU_SG_REL_ IPC_LE SG_ 2149924864 TireRRLowTracIO 1;
BA_REL_ "GenSigSuprvResp" BU_SG_REL_ VCU_LE SG_ 2149924864 TireRFLowTracIO 1;
BA_REL_ "GenSigSuprvResp" BU_SG_REL_ IPC_LE SG_ 2149924864 TireRFLowTracIO 1;
BA_REL_ "GenSigSuprvResp" BU_SG_REL_ VCU_LE SG_ 2149924864 TireLRLowTracIO 1;
BA_REL_ "GenSigSuprvResp" BU_SG_REL_ IPC_LE SG_ 2149924864 TireLRLowTracIO 1;
BA_REL_ "GenSigSuprvResp" BU_SG_REL_ VCU_LE SG_ 2149924864 TireLFLowTracIO 1;
BA_REL_ "GenSigSuprvResp" BU_SG_REL_ IPC_LE SG_ 2149924864 TireLFLowTracIO 1;
BA_REL_ "GenSigSuprvResp" BU_SG_REL_ VCU_LE SG_ 2149924864 HilRlbkCtrlActIO 1;
BA_REL_ "GenSigSuprvResp" BU_SG_REL_ IPC_LE SG_ 2149924864 HilRlbkCtrlActIO 1;
BA_REL_ "GenSigSuprvResp" BU_SG_REL_ VCU_LE SG_ 2149924864 DsplyPerfMdRq 1;
BA_REL_ "GenSigSuprvResp" BU_SG_REL_ IPC_LE SG_ 2149924864 DsplyPerfMdRq 1;
BA_REL_ "GenSigSuprvResp" BU_SG_REL_ CSM_LE SG_ 2149924864 DSMSS_DrvSelMd0Pn 1;
BA_REL_ "GenSigSuprvResp" BU_SG_REL_ RadioHead_LE SG_ 2149924864 DSMSS_DrvSelMd0Pn 1;
BA_REL_ "GenSigSuprvResp" BU_SG_REL_ VCU_LE SG_ 2149924864 DSMSS_DrvSelMd0Pn 1;
BA_REL_ "GenSigSuprvResp" BU_SG_REL_ CSM_LE SG_ 2149924864 DSMSS_DrvSelMd8Pn 1;
BA_REL_ "GenSigSuprvResp" BU_SG_REL_ RadioHead_LE SG_ 2149924864 DSMSS_DrvSelMd8Pn 1;
BA_REL_ "GenSigSuprvResp" BU_SG_REL_ VCU_LE SG_ 2149924864 DSMSS_DrvSelMd8Pn 1;
BA_REL_ "GenSigSuprvResp" BU_SG_REL_ CSM_LE SG_ 2149924864 DSMSS_DrvSelMd7Pn 1;
BA_REL_ "GenSigSuprvResp" BU_SG_REL_ RadioHead_LE SG_ 2149924864 DSMSS_DrvSelMd7Pn 1;
BA_REL_ "GenSigSuprvResp" BU_SG_REL_ VCU_LE SG_ 2149924864 DSMSS_DrvSelMd7Pn 1;
BA_REL_ "GenSigSuprvResp" BU_SG_REL_ CSM_LE SG_ 2149924864 DSMSS_DrvSelMd6Pn 1;
BA_REL_ "GenSigSuprvResp" BU_SG_REL_ RadioHead_LE SG_ 2149924864 DSMSS_DrvSelMd6Pn 1;
BA_REL_ "GenSigSuprvResp" BU_SG_REL_ VCU_LE SG_ 2149924864 DSMSS_DrvSelMd6Pn 1;
BA_REL_ "GenSigSuprvResp" BU_SG_REL_ CSM_LE SG_ 2149924864 DSMSS_DrvSelMd5Pn 1;
BA_REL_ "GenSigSuprvResp" BU_SG_REL_ RadioHead_LE SG_ 2149924864 DSMSS_DrvSelMd5Pn 1;
BA_REL_ "GenSigSuprvResp" BU_SG_REL_ VCU_LE SG_ 2149924864 DSMSS_DrvSelMd5Pn 1;
BA_REL_ "GenSigSuprvResp" BU_SG_REL_ CSM_LE SG_ 2149924864 DSMSS_DrvSelMd4Pn 1;
BA_REL_ "GenSigSuprvResp" BU_SG_REL_ RadioHead_LE SG_ 2149924864 DSMSS_DrvSelMd4Pn 1;
BA_REL_ "GenSigSuprvResp" BU_SG_REL_ VCU_LE SG_ 2149924864 DSMSS_DrvSelMd4Pn 1;
BA_REL_ "GenSigSuprvResp" BU_SG_REL_ CSM_LE SG_ 2149924864 DSMSS_DrvSelMd3Pn 1;
BA_REL_ "GenSigSuprvResp" BU_SG_REL_ RadioHead_LE SG_ 2149924864 DSMSS_DrvSelMd3Pn 1;
BA_REL_ "GenSigSuprvResp" BU_SG_REL_ VCU_LE SG_ 2149924864 DSMSS_DrvSelMd3Pn 1;
BA_REL_ "GenSigSuprvResp" BU_SG_REL_ CSM_LE SG_ 2149924864 DSMSS_DrvSelMd2Pn 1;
BA_REL_ "GenSigSuprvResp" BU_SG_REL_ RadioHead_LE SG_ 2149924864 DSMSS_DrvSelMd2Pn 1;
BA_REL_ "GenSigSuprvResp" BU_SG_REL_ VCU_LE SG_ 2149924864 DSMSS_DrvSelMd2Pn 1;
BA_REL_ "GenSigSuprvResp" BU_SG_REL_ CSM_LE SG_ 2149924864 DSMSS_DrvSelMd1Pn 1;
BA_REL_ "GenSigSuprvResp" BU_SG_REL_ RadioHead_LE SG_ 2149924864 DSMSS_DrvSelMd1Pn 1;
BA_REL_ "GenSigSuprvResp" BU_SG_REL_ VCU_LE SG_ 2149924864 DSMSS_DrvSelMd1Pn 1;
BA_REL_ "GenSigSuprvResp" BU_SG_REL_ CSM_LE SG_ 2149924864 DSMSS_DrvSelMd8Un 1;
BA_REL_ "GenSigSuprvResp" BU_SG_REL_ RadioHead_LE SG_ 2149924864 DSMSS_DrvSelMd8Un 1;
BA_REL_ "GenSigSuprvResp" BU_SG_REL_ VCU_LE SG_ 2149924864 DSMSS_DrvSelMd8Un 1;
BA_REL_ "GenSigSuprvResp" BU_SG_REL_ CSM_LE SG_ 2149924864 DSMSS_DrvSelMd7Un 1;
BA_REL_ "GenSigSuprvResp" BU_SG_REL_ RadioHead_LE SG_ 2149924864 DSMSS_DrvSelMd7Un 1;
BA_REL_ "GenSigSuprvResp" BU_SG_REL_ VCU_LE SG_ 2149924864 DSMSS_DrvSelMd7Un 1;
BA_REL_ "GenSigSuprvResp" BU_SG_REL_ CSM_LE SG_ 2149924864 DSMSS_DrvSelMd6Un 1;
BA_REL_ "GenSigSuprvResp" BU_SG_REL_ RadioHead_LE SG_ 2149924864 DSMSS_DrvSelMd6Un 1;
BA_REL_ "GenSigSuprvResp" BU_SG_REL_ VCU_LE SG_ 2149924864 DSMSS_DrvSelMd6Un 1;
BA_REL_ "GenSigSuprvResp" BU_SG_REL_ CSM_LE SG_ 2149924864 DSMSS_DrvSelMd5Un 1;
BA_REL_ "GenSigSuprvResp" BU_SG_REL_ RadioHead_LE SG_ 2149924864 DSMSS_DrvSelMd5Un 1;
BA_REL_ "GenSigSuprvResp" BU_SG_REL_ VCU_LE SG_ 2149924864 DSMSS_DrvSelMd5Un 1;
BA_REL_ "GenSigSuprvResp" BU_SG_REL_ CSM_LE SG_ 2149924864 DSMSS_DrvSelMd4Un 1;
BA_REL_ "GenSigSuprvResp" BU_SG_REL_ RadioHead_LE SG_ 2149924864 DSMSS_DrvSelMd4Un 1;
BA_REL_ "GenSigSuprvResp" BU_SG_REL_ VCU_LE SG_ 2149924864 DSMSS_DrvSelMd4Un 1;
BA_REL_ "GenSigSuprvResp" BU_SG_REL_ CSM_LE SG_ 2149924864 DSMSS_DrvSelMd3Un 1;
BA_REL_ "GenSigSuprvResp" BU_SG_REL_ RadioHead_LE SG_ 2149924864 DSMSS_DrvSelMd3Un 1;
BA_REL_ "GenSigSuprvResp" BU_SG_REL_ VCU_LE SG_ 2149924864 DSMSS_DrvSelMd3Un 1;
BA_REL_ "GenSigSuprvResp" BU_SG_REL_ CSM_LE SG_ 2149924864 DSMSS_DrvSelMd2Un 1;
BA_REL_ "GenSigSuprvResp" BU_SG_REL_ RadioHead_LE SG_ 2149924864 DSMSS_DrvSelMd2Un 1;
BA_REL_ "GenSigSuprvResp" BU_SG_REL_ VCU_LE SG_ 2149924864 DSMSS_DrvSelMd2Un 1;
BA_REL_ "GenSigSuprvResp" BU_SG_REL_ CSM_LE SG_ 2149924864 DSMSS_DrvSelMd1Un 1;
BA_REL_ "GenSigSuprvResp" BU_SG_REL_ RadioHead_LE SG_ 2149924864 DSMSS_DrvSelMd1Un 1;
BA_REL_ "GenSigSuprvResp" BU_SG_REL_ VCU_LE SG_ 2149924864 DSMSS_DrvSelMd1Un 1;
BA_REL_ "GenSigSuprvResp" BU_SG_REL_ CSM_LE SG_ 2149924864 DrvSelMd3Stat 1;
BA_REL_ "GenSigSuprvResp" BU_SG_REL_ RadioHead_LE SG_ 2149924864 DrvSelMd3Stat 1;
BA_REL_ "GenSigSuprvResp" BU_SG_REL_ VCU_LE SG_ 2149924864 DrvSelMd3Stat 1;
BA_REL_ "GenSigSuprvResp" BU_SG_REL_ CSM_LE SG_ 2149924864 DrvSelMd2Stat 1;
BA_REL_ "GenSigSuprvResp" BU_SG_REL_ RadioHead_LE SG_ 2149924864 DrvSelMd2Stat 1;
BA_REL_ "GenSigSuprvResp" BU_SG_REL_ VCU_LE SG_ 2149924864 DrvSelMd2Stat 1;
BA_REL_ "GenSigSuprvResp" BU_SG_REL_ CSM_LE SG_ 2149924864 DrvSelMd1Stat 1;
BA_REL_ "GenSigSuprvResp" BU_SG_REL_ RadioHead_LE SG_ 2149924864 DrvSelMd1Stat 1;
BA_REL_ "GenSigSuprvResp" BU_SG_REL_ VCU_LE SG_ 2149924864 DrvSelMd1Stat 1;
BA_REL_ "GenSigSuprvResp" BU_SG_REL_ VCU_LE SG_ 2149924864 a_12VBatSysUnstab 1;
BA_REL_ "GenSigSuprvResp" BU_SG_REL_ IPC_LE SG_ 2149924864 a_12VBatSysUnstab 1;
BA_REL_ "GenSigSuprvResp" BU_SG_REL_ VCU_LE SG_ 2149924864 FstIdlMdAct 1;
BA_REL_ "GenSigSuprvResp" BU_SG_REL_ IPC_LE SG_ 2149924864 FstIdlMdAct 1;
BA_REL_ "GenSigRxStartValue" BU_SG_REL_ VCU_LE SG_ 2149924864 CPSCA_Resrv3Avail "0";
BA_REL_ "GenSigRxStartValue" BU_SG_REL_ CSM_LE SG_ 2149924864 CPSCA_Resrv3Avail "0";
BA_REL_ "GenSigRxStartValue" BU_SG_REL_ RadioHead_LE SG_ 2149924864 CPSCA_Resrv3Avail "0";
BA_REL_ "GenSigRxStartValue" BU_SG_REL_ VCU_LE SG_ 2149924864 CPSCA_Resrv2Avail "0";
BA_REL_ "GenSigRxStartValue" BU_SG_REL_ CSM_LE SG_ 2149924864 CPSCA_Resrv2Avail "0";
BA_REL_ "GenSigRxStartValue" BU_SG_REL_ RadioHead_LE SG_ 2149924864 CPSCA_Resrv2Avail "0";
BA_REL_ "GenSigRxStartValue" BU_SG_REL_ VCU_LE SG_ 2149924864 CPSCA_Resrv1Avail "0";
BA_REL_ "GenSigRxStartValue" BU_SG_REL_ CSM_LE SG_ 2149924864 CPSCA_Resrv1Avail "0";
BA_REL_ "GenSigRxStartValue" BU_SG_REL_ RadioHead_LE SG_ 2149924864 CPSCA_Resrv1Avail "0";
BA_REL_ "GenSigRxStartValue" BU_SG_REL_ VCU_LE SG_ 2149924864 CPSCA_AlrtBrkStrAvail "0";
BA_REL_ "GenSigRxStartValue" BU_SG_REL_ CSM_LE SG_ 2149924864 CPSCA_AlrtBrkStrAvail "0";
BA_REL_ "GenSigRxStartValue" BU_SG_REL_ RadioHead_LE SG_ 2149924864 CPSCA_AlrtBrkStrAvail "0";
BA_REL_ "GenSigRxStartValue" BU_SG_REL_ VCU_LE SG_ 2149924864 CPSCA_AlrtBrkAvail "1";
BA_REL_ "GenSigRxStartValue" BU_SG_REL_ CSM_LE SG_ 2149924864 CPSCA_AlrtBrkAvail "1";
BA_REL_ "GenSigRxStartValue" BU_SG_REL_ RadioHead_LE SG_ 2149924864 CPSCA_AlrtBrkAvail "1";
BA_REL_ "GenSigRxStartValue" BU_SG_REL_ VCU_LE SG_ 2149924864 CPSCA_AlrtAvail "1";
BA_REL_ "GenSigRxStartValue" BU_SG_REL_ CSM_LE SG_ 2149924864 CPSCA_AlrtAvail "1";
BA_REL_ "GenSigRxStartValue" BU_SG_REL_ RadioHead_LE SG_ 2149924864 CPSCA_AlrtAvail "1";
BA_REL_ "GenSigRxStartValue" BU_SG_REL_ VCU_LE SG_ 2149924864 CPSCA_OffAvail "1";
BA_REL_ "GenSigRxStartValue" BU_SG_REL_ CSM_LE SG_ 2149924864 CPSCA_OffAvail "1";
BA_REL_ "GenSigRxStartValue" BU_SG_REL_ RadioHead_LE SG_ 2149924864 CPSCA_OffAvail "1";
BA_REL_ "GenSigSuprvResp" BU_SG_REL_ IPC_LE SG_ 2151153664 RrWndDfgOn 1;
BA_REL_ "GenSigSuprvResp" BU_SG_REL_ VCU_LE SG_ 2151153664 RrWndDfgOn 1;
BA_REL_ "GenSigSuprvResp" BU_SG_REL_ VCU_LE SG_ 2151153664 RrWndDfgOn 1;
BA_REL_ "GenSigSuprvResp" BU_SG_REL_ CSM_LE SG_ 2151153664 RrWndDfgOn 1;
BA_REL_ "GenSigSuprvResp" BU_SG_REL_ RadioHead_LE SG_ 2151153664 RrWndDfgOn 1;
BA_REL_ "GenSigSuprvResp" BU_SG_REL_ V2V_LE SG_ 2151841792 WSWprAct 1;
BA_REL_ "GenSigSuprvResp" BU_SG_REL_ VCU_LE SG_ 2152759296 PedWrnIndReq 1;
BA_REL_ "GenSigSuprvResp" BU_SG_REL_ IPC_LE SG_ 2152759296 PedWrnIndReq 1;
BA_REL_ "GenSigSuprvResp" BU_SG_REL_ IPC_LE SG_ 2152759296 FrtCmrBlckdIO 1;
BA_REL_ "GenSigSuprvResp" BU_SG_REL_ VCU_LE SG_ 2152759296 FrtCmrBlckdIO 1;
BA_REL_ "GenSigSuprvResp" BU_SG_REL_ V2V_LE SG_ 2150850560 PsSbltAtc 1;
BA_REL_ "GenSigSuprvResp" BU_SG_REL_ V2V_LE SG_ 2150850560 DrSbltAtc 1;
BA_REL_ "GenSigSuprvResp" BU_SG_REL_ V2V_LE SG_ 2150604800 RRDoorAjarSwAct 1;
BA_REL_ "GenSigRxStartValue" BU_SG_REL_ IPC_LE SG_ 2150604800 RRDoorAjarSwAct "*";
BA_REL_ "GenSigSuprvResp" BU_SG_REL_ IPC_LE SG_ 2150604800 RRDoorAjarSwAct 2;
BA_REL_ "GenSigRxStartValue" BU_SG_REL_ VCU_LE SG_ 2150604800 RRDoorAjarSwAct "*";
BA_REL_ "GenSigSuprvResp" BU_SG_REL_ VCU_LE SG_ 2150604800 RRDoorAjarSwAct 2;
BA_REL_ "GenSigSuprvRespComment" BU_SG_REL_ VCU_LE SG_ 2150604800 RRDoorAjarSwAct "*";
BA_REL_ "GenSigRxStartValue" BU_SG_REL_ VCU_LE SG_ 2150604800 RRDoorAjarSwAct "*";
BA_REL_ "GenSigRxStartValue" BU_SG_REL_ VCU_LE SG_ 2150604800 RRDoorAjarSwAct "*";
BA_REL_ "GenSigSuprvResp" BU_SG_REL_ VCU_LE SG_ 2150604800 RRDoorAjarSwAct 2;
BA_REL_ "GenSigSuprvRespComment" BU_SG_REL_ RadioHead_LE SG_ 2150604800 RRDoorAjarSwAct "*";
BA_REL_ "GenSigRxStartValue" BU_SG_REL_ RadioHead_LE SG_ 2150604800 RRDoorAjarSwAct "*";
BA_REL_ "GenSigRxStartValue" BU_SG_REL_ RadioHead_LE SG_ 2150604800 RRDoorAjarSwAct "*";
BA_REL_ "GenSigSuprvResp" BU_SG_REL_ RadioHead_LE SG_ 2150604800 RRDoorAjarSwAct 2;
BA_REL_ "GenSigSuprvResp" BU_SG_REL_ TCP_LE SG_ 2151219200 RemStrtSt 1;
BA_REL_ "GenSigSuprvResp" BU_SG_REL_ ONSTAR_LE SG_ 2151219200 RemStrtSt 1;
BA_REL_ "GenSigSuprvResp" BU_SG_REL_ VCU_LE SG_ 2151219200 RemStrtSt 1;
BA_REL_ "GenSigSuprvResp" BU_SG_REL_ VCU_LE SG_ 2151219200 RemStrtSt 1;
BA_REL_ "GenSigSuprvResp" BU_SG_REL_ RadioHead_LE SG_ 2151219200 RemStrtSt 1;
BA_REL_ "GenSigSuprvResp" BU_SG_REL_ RadioHead_LE SG_ 2151219200 RemStrtSt 1;
BA_REL_ "GenSigSuprvResp" BU_SG_REL_ VCU_LE SG_ 2155208704 SftTpPlsDnWrngIndOn 1;
BA_REL_ "GenSigSuprvResp" BU_SG_REL_ IPC_LE SG_ 2155208704 SftTpPlsDnWrngIndOn 1;
BA_REL_ "GenSigSuprvResp" BU_SG_REL_ VCU_LE SG_ 2155208704 SftTpPlsDnSrtdIndOn 1;
BA_REL_ "GenSigSuprvResp" BU_SG_REL_ IPC_LE SG_ 2155208704 SftTpPlsDnSrtdIndOn 1;
BA_REL_ "GenSigSuprvResp" BU_SG_REL_ VCU_LE SG_ 2155208704 FldngTpSt 1;
BA_REL_ "GenSigSuprvResp" BU_SG_REL_ IPC_LE SG_ 2155208704 FldngTpSt 1;
BA_REL_ "GenSigSuprvResp" BU_SG_REL_ V2V_LE SG_ 2155208704 ClsTrnkLidIO 1;
BA_REL_ "GenSigRxStartValue" BU_SG_REL_ VCU_LE SG_ 2151530496 TireTrdTmpStat "0";
BA_REL_ "GenSigRxStartValue" BU_SG_REL_ IPC_LE SG_ 2151530496 TireTrdTmpStat "0";
BA_REL_ "GenSigSuprvResp" BU_SG_REL_ VCU_LE SG_ 2151530496 TrPrsMntrTrLdStat 1;
BA_REL_ "GenSigSuprvResp" BU_SG_REL_ IPC_LE SG_ 2151530496 TrPrsMntrTrLdStat 1;
BA_REL_ "GenSigSuprvRespSubValue" BU_SG_REL_ VCU_LE SG_ 2151530496 TPMTrLrnMdCmplt 1;
BA_REL_ "GenSigSuprvResp" BU_SG_REL_ VCU_LE SG_ 2151530496 TPMTrLrnMdCmplt 2;
BA_REL_ "GenSigSuprvRespSubValue" BU_SG_REL_ IPC_LE SG_ 2151530496 TPMTrLrnMdCmplt 1;
BA_REL_ "GenSigSuprvResp" BU_SG_REL_ IPC_LE SG_ 2151530496 TPMTrLrnMdCmplt 2;
BA_REL_ "GenSigSuprvResp" BU_SG_REL_ V2V_LE SG_ 2151497728 TireLFPrs 1;
BA_REL_ "GenSigSuprvResp" BU_SG_REL_ VPM_LE SG_ 2151497728 TireLFPrs 1;
BA_REL_ "GenSigSuprvResp" BU_SG_REL_ TCP_LE SG_ 2151497728 TireLFPrs 1;
BA_REL_ "GenSigSuprvResp" BU_SG_REL_ ONSTAR_LE SG_ 2151497728 TireLFPrs 1;
BA_REL_ "GenSigSuprvResp" BU_SG_REL_ VCU_LE SG_ 2151497728 TireLFPrs 1;
BA_REL_ "GenSigSuprvResp" BU_SG_REL_ IPC_LE SG_ 2151497728 TireLFPrs 1;
BA_REL_ "GenSigSuprvResp" BU_SG_REL_ VPM_LE SG_ 2151497728 TireLFPrsStat 1;
BA_REL_ "GenSigSuprvResp" BU_SG_REL_ V2V_LE SG_ 2151497728 TireLRPrs 1;
BA_REL_ "GenSigSuprvResp" BU_SG_REL_ VPM_LE SG_ 2151497728 TireLRPrs 1;
BA_REL_ "GenSigSuprvResp" BU_SG_REL_ TCP_LE SG_ 2151497728 TireLRPrs 1;
BA_REL_ "GenSigSuprvResp" BU_SG_REL_ ONSTAR_LE SG_ 2151497728 TireLRPrs 1;
BA_REL_ "GenSigSuprvResp" BU_SG_REL_ VCU_LE SG_ 2151497728 TireLRPrs 1;
BA_REL_ "GenSigSuprvResp" BU_SG_REL_ IPC_LE SG_ 2151497728 TireLRPrs 1;
BA_REL_ "GenSigSuprvResp" BU_SG_REL_ VPM_LE SG_ 2151497728 TireLRPrsStat 1;
BA_REL_ "GenSigSuprvResp" BU_SG_REL_ V2V_LE SG_ 2151497728 TireRFPrs 1;
BA_REL_ "GenSigSuprvResp" BU_SG_REL_ VPM_LE SG_ 2151497728 TireRFPrs 1;
BA_REL_ "GenSigSuprvResp" BU_SG_REL_ TCP_LE SG_ 2151497728 TireRFPrs 1;
BA_REL_ "GenSigSuprvResp" BU_SG_REL_ ONSTAR_LE SG_ 2151497728 TireRFPrs 1;
BA_REL_ "GenSigSuprvResp" BU_SG_REL_ VCU_LE SG_ 2151497728 TireRFPrs 1;
BA_REL_ "GenSigSuprvResp" BU_SG_REL_ IPC_LE SG_ 2151497728 TireRFPrs 1;
BA_REL_ "GenSigSuprvResp" BU_SG_REL_ VPM_LE SG_ 2151497728 TireRFPrsStat 1;
BA_REL_ "GenSigSuprvResp" BU_SG_REL_ V2V_LE SG_ 2151497728 TireRRPrs 1;
BA_REL_ "GenSigSuprvResp" BU_SG_REL_ VPM_LE SG_ 2151497728 TireRRPrs 1;
BA_REL_ "GenSigSuprvResp" BU_SG_REL_ TCP_LE SG_ 2151497728 TireRRPrs 1;
BA_REL_ "GenSigSuprvResp" BU_SG_REL_ ONSTAR_LE SG_ 2151497728 TireRRPrs 1;
BA_REL_ "GenSigSuprvResp" BU_SG_REL_ VCU_LE SG_ 2151497728 TireRRPrs 1;
BA_REL_ "GenSigSuprvResp" BU_SG_REL_ IPC_LE SG_ 2151497728 TireRRPrs 1;
BA_REL_ "GenSigSuprvResp" BU_SG_REL_ VPM_LE SG_ 2151497728 TireRRPrsStat 1;
BA_REL_ "GenSigSuprvResp" BU_SG_REL_ V2V_LE SG_ 2150588416 PDAjrSwAtv 1;
BA_REL_ "GenSigSuprvResp" BU_SG_REL_ RadioHead_LE SG_ 2150588416 PDAjrSwAtv 2;
BA_REL_ "GenSigSuprvResp" BU_SG_REL_ RadioHead_LE SG_ 2150588416 PDAjrSwAtv 2;
BA_REL_ "GenSigSuprvResp" BU_SG_REL_ VCU_LE SG_ 2150588416 PDAjrSwAtv 2;
BA_REL_ "GenSigSuprvResp" BU_SG_REL_ VCU_LE SG_ 2150588416 PDAjrSwAtv 2;
BA_REL_ "GenSigSuprvResp" BU_SG_REL_ VCU_LE SG_ 2150588416 PDAjrSwAtv 2;
BA_REL_ "GenSigSuprvResp" BU_SG_REL_ IPC_LE SG_ 2150588416 PDAjrSwAtv 2;
BA_REL_ "GenSigVDAFailComment" BU_SG_REL_ VCU_LE SG_ 2151366656 RrAxlLckIO "AxlLcksVDA";
BA_REL_ "GenSigVDAFailResp" BU_SG_REL_ VCU_LE SG_ 2151366656 RrAxlLckIO 1;
BA_REL_ "GenSigSuprvResp" BU_SG_REL_ VCU_LE SG_ 2151366656 RrAxlLckIO 1;
BA_REL_ "GenSigVDAFailComment" BU_SG_REL_ IPC_LE SG_ 2151366656 RrAxlLckIO "AxlLcksVDA";
BA_REL_ "GenSigVDAFailResp" BU_SG_REL_ IPC_LE SG_ 2151366656 RrAxlLckIO 1;
BA_REL_ "GenSigSuprvResp" BU_SG_REL_ IPC_LE SG_ 2151366656 RrAxlLckIO 1;
BA_REL_ "GenSigVDAFailComment" BU_SG_REL_ VCU_LE SG_ 2151366656 FrntAxlLckIO "AxlLcksVDA";
BA_REL_ "GenSigVDAFailResp" BU_SG_REL_ VCU_LE SG_ 2151366656 FrntAxlLckIO 1;
BA_REL_ "GenSigSuprvResp" BU_SG_REL_ VCU_LE SG_ 2151366656 FrntAxlLckIO 1;
BA_REL_ "GenSigVDAFailComment" BU_SG_REL_ IPC_LE SG_ 2151366656 FrntAxlLckIO "AxlLcksVDA";
BA_REL_ "GenSigVDAFailResp" BU_SG_REL_ IPC_LE SG_ 2151366656 FrntAxlLckIO 1;
BA_REL_ "GenSigSuprvResp" BU_SG_REL_ IPC_LE SG_ 2151366656 FrntAxlLckIO 1;
BA_REL_ "GenSigVDAFailComment" BU_SG_REL_ VCU_LE SG_ 2151366656 AxlLcksServIO "AxlLcksVDA";
BA_REL_ "GenSigVDAFailResp" BU_SG_REL_ VCU_LE SG_ 2151366656 AxlLcksServIO 1;
BA_REL_ "GenSigSuprvResp" BU_SG_REL_ VCU_LE SG_ 2151366656 AxlLcksServIO 1;
BA_REL_ "GenSigVDAFailComment" BU_SG_REL_ IPC_LE SG_ 2151366656 AxlLcksServIO "AxlLcksVDA";
BA_REL_ "GenSigVDAFailResp" BU_SG_REL_ IPC_LE SG_ 2151366656 AxlLcksServIO 1;
BA_REL_ "GenSigSuprvResp" BU_SG_REL_ IPC_LE SG_ 2151366656 AxlLcksServIO 1;
BA_REL_ "GenSigSuprvResp" BU_SG_REL_ VCU_LE SG_ 2151366656 AxlLckUnavailIndReq 1;
BA_REL_ "GenSigSuprvResp" BU_SG_REL_ IPC_LE SG_ 2151366656 AxlLckUnavailIndReq 1;
BA_REL_ "GenSigSuprvResp" BU_SG_REL_ V2V_LE SG_ 2151366656 PrkBrkSwAtv 1;
BA_REL_ "GenSigSuprvResp" BU_SG_REL_ ONSTAR_LE SG_ 2151366656 PrkBrkSwAtv 1;
BA_REL_ "GenSigSuprvResp" BU_SG_REL_ TCP_LE SG_ 2151366656 PrkBrkSwAtv 1;
BA_REL_ "GenSigSuprvResp" BU_SG_REL_ LVMNav_LE SG_ 2151366656 PrkBrkSwAtv 1;
BA_REL_ "GenSigSuprvResp" BU_SG_REL_ VCU_LE SG_ 2151284736 TnDrvPrkAstOffUnbIO 1;
BA_REL_ "GenSigSuprvResp" BU_SG_REL_ IPC_LE SG_ 2151284736 TnDrvPrkAstOffUnbIO 1;
BA_REL_ "GenSigSuprvResp" BU_SG_REL_ VCU_LE SG_ 2151284736 PrkAsstDisablIO 1;
BA_REL_ "GenSigSuprvResp" BU_SG_REL_ IPC_LE SG_ 2151284736 PrkAsstDisablIO 1;
BA_REL_ "GenSigSuprvResp" BU_SG_REL_ V2V_LE SG_ 2150596608 RLDoorAjarSwAct 1;
BA_REL_ "GenSigRxStartValue" BU_SG_REL_ RadioHead_LE SG_ 2150596608 RLDoorAjarSwAct "*";
BA_REL_ "GenSigSuprvResp" BU_SG_REL_ RadioHead_LE SG_ 2150596608 RLDoorAjarSwAct 2;
BA_REL_ "GenSigRxStartValue" BU_SG_REL_ RadioHead_LE SG_ 2150596608 RLDoorAjarSwAct "*";
BA_REL_ "GenSigSuprvResp" BU_SG_REL_ RadioHead_LE SG_ 2150596608 RLDoorAjarSwAct 2;
BA_REL_ "GenSigRxStartValue" BU_SG_REL_ VCU_LE SG_ 2150596608 RLDoorAjarSwAct "*";
BA_REL_ "GenSigSuprvResp" BU_SG_REL_ VCU_LE SG_ 2150596608 RLDoorAjarSwAct 2;
BA_REL_ "GenSigRxStartValue" BU_SG_REL_ VCU_LE SG_ 2150596608 RLDoorAjarSwAct "*";
BA_REL_ "GenSigSuprvResp" BU_SG_REL_ VCU_LE SG_ 2150596608 RLDoorAjarSwAct 2;
BA_REL_ "GenSigSuprvResp" BU_SG_REL_ VCU_LE SG_ 2150596608 RLDoorAjarSwAct 2;
BA_REL_ "GenSigSuprvResp" BU_SG_REL_ IPC_LE SG_ 2150596608 RLDoorAjarSwAct 2;
BA_REL_ "GenSigSuprvResp" BU_SG_REL_ VCU_LE SG_ 2155380736 StrAsstRdcdLvl3IO 1;
BA_REL_ "GenSigSuprvResp" BU_SG_REL_ IPC_LE SG_ 2155380736 StrAsstRdcdLvl3IO 1;
BA_REL_ "GenSigSuprvResp" BU_SG_REL_ VCU_LE SG_ 2155380736 StrAsstRdcdLvl2IO 1;
BA_REL_ "GenSigSuprvResp" BU_SG_REL_ IPC_LE SG_ 2155380736 StrAsstRdcdLvl2IO 1;
BA_REL_ "GenSigSuprvResp" BU_SG_REL_ VCU_LE SG_ 2155380736 StrngAsstRdcdIO 1;
BA_REL_ "GenSigSuprvResp" BU_SG_REL_ IPC_LE SG_ 2155380736 StrngAsstRdcdIO 1;
BA_REL_ "GenSigSuprvResp" BU_SG_REL_ VCU_LE SG_ 2155380736 SrvLevSysIO 1;
BA_REL_ "GenSigSuprvResp" BU_SG_REL_ IPC_LE SG_ 2155380736 SrvLevSysIO 1;
VAL_ 2155102208 DSMP_UnsdRsrvd 1 "true" 0 "false" ;
VAL_ 2155085824 CPMAPINFO4 1 "Hardware Or Software Error" 0 "No Hardware Or Software Error" ;
VAL_ 2155085824 StrgColCommsFlt 2 "Disabled Communications DTC" 1 "No Communications Fault" 0 "Communications Fault" ;
VAL_ 2155085824 DSCDS_DispReq 1 "true" 0 "false" ;
VAL_ 2155085824 DSCDS_DispSz 3 "Reserved" 2 "Small Size" 1 "Medium Size" 0 "Full Size" ;
VAL_ 2155085824 DSCDS_CshLgAdjFdRr 3 "Rearward" 2 "Forward" 1 "Selected - No Movement" 0 "Not Selected" ;
VAL_ 2155085824 DSCDS_BkCshBlstInOt 5 "Cushion Bolster Out" 4 "Cushion Bolster In" 3 "Back Bolster Out" 2 "Back Bolster In" 1 "Selected - No Movement" 0 "Not Selected" ;
VAL_ 2155085824 DSCDS_CshBlstrInOut 3 "Out" 2 "In" 1 "Selected - No Movement" 0 "Not Selected" ;
VAL_ 2155085824 DSCDS_BkBlstrInOut 3 "Out" 2 "In" 1 "Selected - No Movement" 0 "Not Selected" ;
VAL_ 2155085824 DSCDS_LmbrUDnFdRr 5 "Rearward" 4 "Forward" 3 "Down" 2 "Up" 1 "Selected - No Movement" 0 "Not Selected" ;
VAL_ 2155085824 DSCDS_LmbrFwdRr 3 "Rearward" 2 "Forward" 1 "Selected - No Movement" 0 "Not Selected" ;
VAL_ 2155085824 DSCDS_LmbrUpDwn 3 "Down" 2 "Up" 1 "Selected - No Movement" 0 "Not Selected" ;
VAL_ 2155085824 DSCDS_UprShldrFdRr 3 "Rearward" 2 "Forward" 1 "Selected - No Movement" 0 "Not Selected" ;
VAL_ 2155085824 DSCDS_HdrstTltFwdRr 3 "Rearward" 2 "Forward" 1 "Selected - No Movement" 0 "Not Selected" ;
VAL_ 2155085824 DSCDS_HdrstWngInOt 3 "Out" 2 "In" 1 "Selected - No Movement" 0 "Not Selected" ;
VAL_ 2155085824 DSCDS_HdrstUDnFdRr 5 "Rearward" 4 "Forward" 3 "Down" 2 "Up" 1 "Selected - No Movement" 0 "Not Selected" ;
VAL_ 2155085824 DSCDS_HdrstFwdRrwd 3 "Rearward" 2 "Forward" 1 "Selected - No Movement" 0 "Not Selected" ;
VAL_ 2155085824 DSCDS_HdrstUpDn 3 "Down" 2 "Up" 1 "Selected - No Movement" 0 "Not Selected" ;
VAL_ 2155085824 DSCDS_MassgIntsty 7 "Massage Intensity 7" 6 "Massage Intensity 6" 5 "Massage Intensity 5" 4 "Massage Intensity 4" 3 "Massage Intensity 3" 2 "Massage Intensity 2" 1 "Massage Intensity 1" 0 "Massage Off" ;
VAL_ 2155085824 DSCDS_MassgTyp 15 "Massage Type 15" 14 "Massage Type 14" 13 "Massage Type 13" 12 "Massage Type 12" 11 "Massage Type 11" 10 "Massage Type 10" 9 "Massage Type 9" 8 "Massage Type 8" 7 "Massage Type 7" 6 "Massage Type 6" 5 "Massage Type 5" 4 "Massage Type 4" 3 "Massage Type 3" 2 "Massage Type 2" 1 "Massage Type 1" 0 "Massage Off" ;
VAL_ 2155085824 DSCDS_Massg 2 "Selected Massage On" 1 "Selected Massage Off" 0 "Not Selected" ;
VAL_ 2152103936 LRSCDS_DispReq 1 "true" 0 "false" ;
VAL_ 2152103936 LRSCDS_DispSz 2 "Small Size" 1 "Medium Size" 0 "Full Size" ;
VAL_ 2152103936 LRSCDS_CshLgAdjFdRr 3 "Rearward" 2 "Forward" 1 "Selected - No Movement " 0 "Not Selected" ;
VAL_ 2152103936 LRSCDS_BkCshBlstInOt 5 "Cushion Bolster Out" 4 "Cushion Bolster In" 3 "Back Bolster Out" 2 "Back Bolster In" 1 "Selected - No Movement" 0 "Not Selected" ;
VAL_ 2152103936 LRSCDS_CshBlstrInOut 3 "Out" 2 "In" 1 "Selected - No Movement" 0 "Not Selected" ;
VAL_ 2152103936 LRSCDS_BkBlstrInOut 3 "Out" 2 "In" 1 "Selected - No Movement" 0 "Not Selected" ;
VAL_ 2152103936 LRSCDS_LmbrUDnFdRr 5 "Rearward" 4 "Forward" 3 "Down" 2 "Up" 1 "Selected - No Movement " 0 "Not Selected" ;
VAL_ 2152103936 LRSCDS_LmbrFwdRr 3 "Rearward" 2 "Forward" 1 "Selected - No Movement " 0 "Not Selected" ;
VAL_ 2152103936 LRSCDS_LmbrUpDwn 3 "Down" 2 "Up" 1 "Selected - No Movement" 0 "Not Selected" ;
VAL_ 2152103936 LRSCDS_UprShldrFdRr 3 "Rearward" 2 "Forward" 1 "Selected - No Movement " 0 "Not Selected" ;
VAL_ 2152103936 LRSCDS_HdrstTltFwdRr 3 "Rearward" 2 "Forward" 1 "Selected - No Movement " 0 "Not Selected" ;
VAL_ 2152103936 LRSCDS_HdrstWngInOt 3 "Out" 2 "In" 1 "Selected - No Movement" 0 "Not Selected" ;
VAL_ 2152103936 LRSCDS_HdrstFdRrUDn 5 "Rearward" 4 "Forward" 3 "Down" 2 "Up" 1 "Selected - No Movement " 0 "Not Selected" ;
VAL_ 2152103936 LRSCDS_HdrstFwdRrwd 3 "Rearward" 2 "Forward" 1 "Selected - No Movement " 0 "Not Selected" ;
VAL_ 2152103936 LRSCDS_HdrstUpDn 3 "Down" 2 "Up" 1 "Selected - No Movement" 0 "Not Selected" ;
VAL_ 2152103936 LRSCDS_MassgIntsty 7 "Massage Intensity 7" 6 "Massage Intensity 6" 5 "Massage Intensity 5" 4 "Massage Intensity 4" 3 "Massage Intensity 3" 2 "Massage Intensity 2" 1 "Massage Intensity 1" 0 "Massage Off" ;
VAL_ 2152103936 LRSCDS_MassgTyp 15 "Massage Type 15" 14 "Massage Type 14" 13 "Massage Type 13" 12 "Massage Type 12" 11 "Massage Type 11" 10 "Massage Type 10" 9 "Massage Type 9" 8 "Massage Type 8" 7 "Massage Type 7" 6 "Massage Type 6" 5 "Massage Type 5" 4 "Massage Type 4" 3 "Massage Type 3" 2 "Massage Type 2" 1 "Massage Type 1" 0 "Massage Off" ;
VAL_ 2152103936 LRSCDS_Massg 2 "Selected Massage On" 1 "Selected Massage Off" 0 "Not Selected" ;
VAL_ 2152087552 LRSMP_UnsdRsrvd 1 "true" 0 "false" ;
VAL_ 2153308160 RdHVltBatPckVltV 1 "Invalid" 0 "Valid" ;
VAL_ 2153308160 RdHVltBatPckVltM 1 "Use Data" 0 "Don't Use Data" ;
VAL_ 2153308160 RdHVltBatPckCrntV 1 "Invalid" 0 "Valid" ;
VAL_ 2153308160 RdHVltBatPckCrntM 1 "Use Data" 0 "Don't Use Data" ;
VAL_ 2149924864 PTOMobModTrnsInGrIO 1 "true" 0 "false" ;
VAL_ 2149924864 FwdClnMtgnBrkReqAct 1 "true" 0 "false" ;
VAL_ 2149924864 TireRRLowTracIO 1 "true" 0 "false" ;
VAL_ 2149924864 TireRFLowTracIO 1 "true" 0 "false" ;
VAL_ 2149924864 TireLRLowTracIO 1 "true" 0 "false" ;
VAL_ 2149924864 TireLFLowTracIO 1 "true" 0 "false" ;
VAL_ 2149924864 HilRlbkCtrlActIO 1 "true" 0 "false" ;
VAL_ 2149924864 DsplyPerfMdRq 7 "Performance Mode 7" 6 "Performance Mode 6" 5 "Performance Mode 5" 4 "Performance Mode 4" 3 "Performance Mode 3" 2 "Performance Mode 2" 1 "Performance Mode 1" 0 "No Action" ;
VAL_ 2149924864 DrvSelMd8Stat 1 "Active" 0 "Inactive" ;
VAL_ 2149924864 DrvSelMd8ReqDnd 1 "true" 0 "false" ;
VAL_ 2149924864 DrvSelMd7Stat 1 "Active" 0 "Inactive" ;
VAL_ 2149924864 DrvSelMd7ReqDnd 1 "true" 0 "false" ;
VAL_ 2149924864 DrvSelMd6Stat 1 "Active" 0 "Inactive" ;
VAL_ 2149924864 DrvSelMd6ReqDnd 1 "true" 0 "false" ;
VAL_ 2149924864 DrvSelMd5Stat 1 "Active" 0 "Inactive" ;
VAL_ 2149924864 DrvSelMd5ReqDnd 1 "true" 0 "false" ;
VAL_ 2149924864 DrvSelMd4Stat 1 "Active" 0 "Inactive" ;
VAL_ 2149924864 DrvSelMd4ReqDnd 1 "true" 0 "false" ;
VAL_ 2149924864 EDADS_RcmndtFwdGr 15 "Unused and Reserved 7" 14 "Unused and Reserved 6" 13 "Unused and Reserved 5" 12 "Unused and Reserved 4" 11 "Unused and Reserved 3" 10 "Tenth Gear" 9 "Ninth Gear" 8 "Eighth Gear" 7 "Seventh Gear" 6 "Sixth Gear" 5 "Fifth Gear" 4 "Fourth Gear" 3 "Third Gear" 2 "Second Gear" 1 "First Gear" 0 "None" ;
VAL_ 2149924864 EDADS_CrntFwdMsdG 15 "Unused and Reserved 7" 14 "Unused and Reserved 6" 13 "Unused and Reserved 5" 12 "Unused and Reserved 4" 11 "Unused and Reserved 3" 10 "Tenth Gear" 9 "Ninth Gear" 8 "Eighth Gear" 7 "Seventh Gear" 6 "Sixth Gear" 5 "Fifth Gear" 4 "Fourth Gear" 3 "Third Gear" 2 "Second Gear" 1 "First Gear" 0 "None" ;
VAL_ 2149924864 EDADS_ShftIndStat 2 "No Shift" 1 "Shift Up" 0 "Shift Down" ;
VAL_ 2149924864 EDADS_EcoDrvShftIO 1 "true" 0 "false" ;
VAL_ 2149924864 DSMSS_DrvSelMd0Pn 1 "true" 0 "false" ;
VAL_ 2149924864 DSMSS_DrvSelMd8Pn 1 "true" 0 "false" ;
VAL_ 2149924864 DSMSS_DrvSelMd7Pn 1 "true" 0 "false" ;
VAL_ 2149924864 DSMSS_DrvSelMd6Pn 1 "true" 0 "false" ;
VAL_ 2149924864 DSMSS_DrvSelMd5Pn 1 "true" 0 "false" ;
VAL_ 2149924864 DSMSS_DrvSelMd4Pn 1 "true" 0 "false" ;
VAL_ 2149924864 DSMSS_DrvSelMd3Pn 1 "true" 0 "false" ;
VAL_ 2149924864 DSMSS_DrvSelMd2Pn 1 "true" 0 "false" ;
VAL_ 2149924864 DSMSS_DrvSelMd1Pn 1 "true" 0 "false" ;
VAL_ 2149924864 DSMSS_DrvSelMd8Un 1 "true" 0 "false" ;
VAL_ 2149924864 DSMSS_DrvSelMd7Un 1 "true" 0 "false" ;
VAL_ 2149924864 DSMSS_DrvSelMd6Un 1 "true" 0 "false" ;
VAL_ 2149924864 DSMSS_DrvSelMd5Un 1 "true" 0 "false" ;
VAL_ 2149924864 DSMSS_DrvSelMd4Un 1 "true" 0 "false" ;
VAL_ 2149924864 DSMSS_DrvSelMd3Un 1 "true" 0 "false" ;
VAL_ 2149924864 DSMSS_DrvSelMd2Un 1 "true" 0 "false" ;
VAL_ 2149924864 DSMSS_DrvSelMd1Un 1 "true" 0 "false" ;
VAL_ 2149924864 DrvSelMd3Stat 1 "Active" 0 "Inactive" ;
VAL_ 2149924864 DrvSelMd3ReqDnd 1 "true" 0 "false" ;
VAL_ 2149924864 DrvSelMd2Stat 1 "Active" 0 "Inactive" ;
VAL_ 2149924864 DrvSelMd2ReqDnd 1 "true" 0 "false" ;
VAL_ 2149924864 DrvSelMd1Stat 1 "Active" 0 "Inactive" ;
VAL_ 2149924864 DrvSelMd1ReqDnd 1 "true" 0 "false" ;
VAL_ 2149924864 a_12VBatSysUnstab 1 "true" 0 "false" ;
VAL_ 2149924864 FstIdlMdAct 1 "true" 0 "false" ;
VAL_ 2149924864 CPSCA_Resrv3Avail 1 "true" 0 "false" ;
VAL_ 2149924864 CPSCA_Resrv2Avail 1 "true" 0 "false" ;
VAL_ 2149924864 CPSCA_Resrv1Avail 1 "true" 0 "false" ;
VAL_ 2149924864 CPSCA_AlrtBrkStrAvail 1 "true" 0 "false" ;
VAL_ 2149924864 CPSCA_AlrtBrkAvail 1 "true" 0 "false" ;
VAL_ 2149924864 CPSCA_AlrtAvail 1 "true" 0 "false" ;
VAL_ 2149924864 CPSCA_OffAvail 1 "true" 0 "false" ;
VAL_ 2151153664 RrWndDfgOn 1 "true" 0 "false" ;
VAL_ 2151841792 HtdFrntWSSt 1 "ON" 0 "OFF" ;
VAL_ 2151841792 WSWprAct 1 "true" 0 "false" ;
VAL_ 2151841792 RnSnsOffIO 1 "true" 0 "false" ;
VAL_ 2151841792 RnSnsActIO 1 "true" 0 "false" ;
VAL_ 2151841792 TurnWprIntIO 1 "true" 0 "false" ;
VAL_ 2154078208 RRWndPosStat 6 "Fully Opened" 5 "Open More Than C" 4 "Position C" 3 "Posistion B" 2 "Posistion A" 1 "Open Less Than A" 0 "Fully Closed" ;
VAL_ 2154078208 PsWndPosStat 6 "Fully Opened" 5 "Open More Than C" 4 "Position C" 3 "Posistion B" 2 "Posistion A" 1 "Open Less Than A" 0 "Fully Closed" ;
VAL_ 2154078208 LRWndPosStat 6 "Fully Opened" 5 "Open More Than C" 4 "Position C" 3 "Posistion B" 2 "Posistion A" 1 "Open Less Than A" 0 "Fully Closed" ;
VAL_ 2154078208 DrvWndPosStat 6 "Fully Opened" 5 "Open More Than C" 4 "Position C" 3 "Posistion B" 2 "Posistion A" 1 "Open Less Than A" 0 "Fully Closed" ;
VAL_ 2151399424 WshFldLw 1 "true" 0 "false" ;
VAL_ 2151399424 VhlFlRngLwIO 1 "true" 0 "false" ;
VAL_ 2151170048 RrEndCrrStat 0 "Not Extended" 1 "Extended" ;
VAL_ 2151170048 RRPrkLmpFld 1 "true" 0 "false" ;
VAL_ 2151170048 RLftPrkLmpFld 1 "true" 0 "false" ;
VAL_ 2151170048 DisRrPrmryLmps 1 "true" 0 "false" ;
VAL_ 2151170048 TrlrTlLtFld 1 "true" 0 "false" ;
VAL_ 2151170048 TrlrRvsLtFld 1 "true" 0 "false" ;
VAL_ 2151170048 TrlrFgLtFld 1 "true" 0 "false" ;
VAL_ 2151170048 TrlrBrkLtFld 1 "true" 0 "false" ;
VAL_ 2151170048 TrlrRtTrInLtFld 1 "true" 0 "false" ;
VAL_ 2151170048 TrlLfTrInLtFld 1 "true" 0 "false" ;
VAL_ 2151170048 TrlrHtchSwAtv 1 "true" 0 "false" ;
VAL_ 2151170048 RtSecTrnIndFld 1 "true" 0 "false" ;
VAL_ 2151170048 TrlrFgLtPrs 1 "true" 0 "false" ;
VAL_ 2151170048 LftSecTrnIndFld 1 "true" 0 "false" ;
VAL_ 2152759296 PedWrnIndReq 3 "Reserved " 2 "Pedestrian alert" 1 "Pedestrian detected" 0 "None" ;
VAL_ 2152759296 FrtRdrFldIO 1 "true" 0 "false" ;
VAL_ 2152759296 FrtCmrFldIO 1 "true" 0 "false" ;
VAL_ 2152759296 FrtEOCMMdlFldIO 1 "true" 0 "false" ;
VAL_ 2152759296 FrtCmrBlckdIO 1 "true" 0 "false" ;
VAL_ 2150850560 PsSbltAtcV 1 "Invalid" 0 "Valid" ;
VAL_ 2150850560 PsSbltAtc 1 "true" 0 "false" ;
VAL_ 2150850560 DrSbltAtcV 1 "Invalid" 0 "Valid" ;
VAL_ 2150850560 DrSbltAtc 1 "true" 0 "false" ;
VAL_ 2150604800 RRDoorAjarSwAct 1 "true" 0 "false" ;
VAL_ 2151219200 RemStrtSt 1 "Active" 0 "Inactive" ;
VAL_ 2151219200 RmVehStrRq 1 "Remote Start Requested" 0 "Remote Start Not Requested" ;
VAL_ 2150514688 SldngDrRgtStat 5 "Stopped" 4 "Closing" 3 "Opening" 2 "Closed" 1 "Full Open" 0 "Unknown" ;
VAL_ 2150514688 SldngDrLftStat 5 "Stopped" 4 "Closing" 3 "Opening" 2 "Closed" 1 "Full Open" 0 "Unknown" ;
VAL_ 2150514688 SdClsrObstclDtctdStat 1 "true" 0 "false" ;
VAL_ 2150514688 PwrSldngDrUnavlblIO 1 "true" 0 "false" ;
VAL_ 2155208704 SftTpPlsDnWrngIndOn 1 "true" 0 "false" ;
VAL_ 2155208704 SftTpPlsDnSrtdIndOn 1 "true" 0 "false" ;
VAL_ 2155208704 VltSwAtvIndOn 1 "true" 0 "false" ;
VAL_ 2155208704 SftTpVltLwIO 1 "true" 0 "false" ;
VAL_ 2155208704 SftTpVehOvSpdIndOn 1 "true" 0 "false" ;
VAL_ 2155208704 SftTpTneuCvrIO 1 "true" 0 "false" ;
VAL_ 2155208704 SftTpTmpLwIO 1 "true" 0 "false" ;
VAL_ 2155208704 SftTpStrIO 1 "true" 0 "false" ;
VAL_ 2155208704 SftTpRmCrgCrrIO 1 "true" 0 "false" ;
VAL_ 2155208704 SftTpMnlLtchIndOn 1 "true" 0 "false" ;
VAL_ 2155208704 SftTpMchnOvhtIO 1 "true" 0 "false" ;
VAL_ 2155208704 SftTpLtcIO 1 "true" 0 "false" ;
VAL_ 2155208704 SftTpFlrIO 1 "true" 0 "false" ;
VAL_ 2155208704 SftTpAbvWrngSpdIndOn 1 "true" 0 "false" ;
VAL_ 2155208704 FldngTpSt 4 "Not Secure And Not Moving " 3 "Closing" 2 "Opening" 1 "Fully Closed" 0 "Fully Opened" ;
VAL_ 2155208704 ClsTrnkLidIO 1 "true" 0 "false" ;
VAL_ 2155208704 CkSoftTpIO 1 "true" 0 "false" ;
VAL_ 2155208704 SftTpTrnLmpsRqd 1 "true" 0 "false" ;
VAL_ 2155208704 FldngTpWndCmftRq 0 "No Action" 1 "Comfort Close" 2 "Comfort Open" 3 "Reserved" ;
VAL_ 2155208704 FTUpdWndPsLmtEnbld 1 "true" 0 "false" ;
VAL_ 2151530496 HVBTBDCSRR1_DChSnSRq 3 "Yearly" 2 "Winter" 1 "Summer" 0 "No Action" ;
VAL_ 2151530496 HVBTBDCSRR1_DChSlSRq 8 "Unused and Reserved 4" 7 "Departure Time 2 Invalid" 6 "Unused and Reserved 3" 5 "Departure Time 2" 4 "Unused and Reserved 2" 3 "Departure Time 1 Invalid" 2 "Unused and Reserved 1" 1 "Departure Time 1" 0 "No Action" ;
VAL_ 2151530496 HVBTBDCSRR1_DChDStRq 10 "Sat and Sun Same" 9 "Mon To Fri Same" 8 "All Days Same" 7 "Saturday" 6 "Friday" 5 "Thursday" 4 "Wednsday" 3 "Tuesday" 2 "Monday" 1 "Sunday" 0 "No Action" ;
VAL_ 2151530496 HVBatTmBsChgMdRqRmt1 3 "Rate Based Charge" 2 "Delayed Charge" 1 "Charge Now" 0 "No Action" ;
VAL_ 2151530496 HVChgSyChgLvPfStRmt1 4 "Reduced Current Level 3" 3 "Reduced Current Level 2" 2 "Reduced Current Level 1" 1 "No Reduction" 0 "No Action" ;
VAL_ 2151530496 StTODChrgTmpOvrdRmt1 2 "Active" 1 "Inactive" 0 "No Action" ;
VAL_ 2151530496 PrtyChrgRqRmt1 2 "Active" 1 "Inactive" 0 "No Action" ;
VAL_ 2151530496 OfBrdHVCVhCsChRqRmt1 1 "true" 0 "false" ;
VAL_ 2151530496 TireTrdTmpStat 0 "No Action (unknown)" 1 "Frozen" 2 "Cold" 3 "Warm" 4 "Hot" 5 "Overheated" ;
VAL_ 2151530496 TrPrsMntrTrLdStat 0 "Unknown" 1 "Light Load" 2 "Best Economy Load" 3 "Max Load" ;
VAL_ 2151530496 TrPrsMntrAtLocFld 1 "true" 0 "false" ;
VAL_ 2151530496 TireLocatnWarnEn 1 "true" 0 "false" ;
VAL_ 2151530496 WintTrRecIndOn 1 "true" 0 "false" ;
VAL_ 2151530496 TrPrsMntrFld 1 "true" 0 "false" ;
VAL_ 2151530496 TrRrAxlPresStat 2 "Tire Pressure Imbalance Warning" 1 "Tire Pressure Balanced" 0 "Unknown" ;
VAL_ 2151530496 TrFrntAxlPresStat 2 "Tire Pressure Imbalance Warning" 1 "Tire Pressure Balanced" 0 "Unknown" ;
VAL_ 2151530496 TPMTrLrnMdCmplt 1 "true" 0 "false" ;
VAL_ 2151497728 TireLFPrsStat 5 "High" 4 "Low - Extended Mobility" 3 "Low" 2 "Low - Service Now" 1 "Nominal" 0 "Unknown" ;
VAL_ 2151497728 TireLFPrsV 1 "Invalid" 0 "Valid" ;
VAL_ 2151497728 TireLRPrsStat 5 "High" 4 "Low - Extended Mobility" 3 "Low" 2 "Low - Service Now" 1 "Nominal" 0 "Unknown" ;
VAL_ 2151497728 TireLRPrsV 1 "Invalid" 0 "Valid" ;
VAL_ 2151497728 TireRFPrsStat 5 "High" 4 "Low - Extended Mobility" 3 "Low" 2 "Low - Service Now" 1 "Nominal" 0 "Unknown" ;
VAL_ 2151497728 TireRFPrsV 1 "Invalid" 0 "Valid" ;
VAL_ 2151497728 TireRRPrsStat 5 "High" 4 "Low - Extended Mobility" 3 "Low" 2 "Low - Service Now" 1 "Nominal" 0 "Unknown" ;
VAL_ 2151497728 TireRRPrsV 1 "Invalid" 0 "Valid" ;
VAL_ 2150588416 PDAjrSwAtv 1 "true" 0 "false" ;
VAL_ 2150916096 PrkHtrCoolntTempM 1 "Use Data" 0 "Don't Use Data" ;
VAL_ 2150916096 PrkHtrPrhtAch 1 "true" 0 "false" ;
VAL_ 2150916096 PrkHtrFlCnsmdRolCntV 1 "Invalid" 0 "Valid" ;
VAL_ 2150916096 PrkHtrFlCsmdRlCntRsOc 1 "true" 0 "false" ;
VAL_ 2150916096 PrkHtrCoolntTempV 1 "Invalid" 0 "Valid" ;
VAL_ 2150916096 ClntCircPmpAct 1 "true" 0 "false" ;
VAL_ 2150916096 PrkHtrAtv 1 "true" 0 "false" ;
VAL_ 2151366656 RrAxlLckIO 1 "true" 0 "false" ;
VAL_ 2151366656 FrntAxlLckIO 1 "true" 0 "false" ;
VAL_ 2151366656 AxlLcksServIO 1 "true" 0 "false" ;
VAL_ 2151366656 AxlLckUnavailIndReq 7 "Unused And Reserved 2" 6 "Unused And Reserved 1" 5 "Generic Unavailable" 4 "Not During Hill Decent" 3 "Speed Too High" 2 "Not In 4 WD Low" 1 "Rear Axle Not Locked" 0 "No Action" ;
VAL_ 2151366656 AxlLcksVDA 1 "Virtual Device Available" 0 "Virtual Device Unavailable" ;
VAL_ 2151366656 PrkBrkSwAtv 1 "true" 0 "false" ;
VAL_ 2151284736 PrkAstOprtrDsrdStat_1D0 0 "Off" 1 "On" 2 "Tow Bar Attached" ;
VAL_ 2151284736 TnDrvPrkAstOffUnbIO 1 "true" 0 "false" ;
VAL_ 2151284736 PrkAstFld 1 "true" 0 "false" ;
VAL_ 2151284736 PrkAstSnsDistrbdIO 1 "true" 0 "false" ;
VAL_ 2151284736 PrkAsstDisablIO 1 "true" 0 "false" ;
VAL_ 2151284736 PrkAstSnrsBlk 1 "true" 0 "false" ;
VAL_ 2151284736 PrkAsstClnPrkAstIO 1 "true" 0 "false" ;
VAL_ 2150596608 RLDoorAjarSwAct 1 "true" 0 "false" ;
VAL_ 2155380736 ServFuelSysTrnsfrPmpIO 1 "true" 0 "false" ;
VAL_ 2155380736 ACCmCltEngd 1 "true" 0 "false" ;
VAL_ 2155380736 StrAsstRdcdLvl3IO 1 "true" 0 "false" ;
VAL_ 2155380736 StrAsstRdcdLvl2IO 1 "true" 0 "false" ;
VAL_ 2155380736 StrngAsstRdcdIO 1 "true" 0 "false" ;
VAL_ 2155380736 ARSFlrIO 1 "true" 0 "false" ;
VAL_ 2155380736 PTExPrtclFltrWrn2IO 1 "true" 0 "false" ;
VAL_ 2155380736 EngOilHotIO 1 "true" 0 "false" ;
VAL_ 2155380736 RrLevVDA 1 "VirtualDeviceAvailable" 0 "VirtualDeviceUnavailable" ;
VAL_ 2155380736 EngWtrInFlIO 1 "true" 0 "false" ;
VAL_ 2155380736 AdvFrntLghtSysIndRq 7 "Indication 7" 6 "Indication 6" 5 "Indication 5" 4 "Indication 4" 3 "Indication 3" 2 "Indication 2" 1 "Indication 1" 0 "No Indication" ;
VAL_ 2155380736 PTExPrtclFltrWrnIO 1 "true" 0 "false" ;
VAL_ 2155380736 AirCndOffIO 1 "true" 0 "false" ;
VAL_ 2155380736 HdLtLvlFlrIO 1 "true" 0 "false" ;
VAL_ 2155380736 PwrStrIO 1 "true" 0 "false" ;
VAL_ 2155380736 EngHt_StpEngIO 1 "true" 0 "false" ;
VAL_ 2155380736 CkFlFilrCapIO 1 "true" 0 "false" ;
VAL_ 2155380736 RdcdPwrIO 1 "true" 0 "false" ;
VAL_ 2155380736 EngOilPrsLwIO 1 "true" 0 "false" ;
VAL_ 2155380736 EngOilLvlLwIO 1 "true" 0 "false" ;
VAL_ 2155380736 EngOilChngIO 1 "true" 0 "false" ;
VAL_ 2155380736 EngHotFuelEnrchmntIO 1 "true" 0 "false" ;
VAL_ 2155380736 DslGlwPlgIO 1 "true" 0 "false" ;
VAL_ 2155380736 SrvLevSysIO 1 "true" 0 "false" ;
VAL_ 2155380736 VehOvrLdIndOn 1 "true" 0 "false" ;
SIG_GROUP_ 2155102208 DrvStMassgPrty 1 : DSMP_UnsdRsrvd DSMP_MaxDispVal DSMP_Type15 DSMP_Type14 DSMP_Type13 DSMP_Type12 DSMP_Type11 DSMP_Type10 DSMP_Type9 DSMP_Type8 DSMP_Type7 DSMP_Type6 DSMP_Type5 DSMP_Type4 DSMP_Type3 DSMP_Type2 DSMP_Type1;
SIG_GROUP_ 2155085824 DrvStCtlDispStat 1 : DSCDS_UnsdRsrvd DSCDS_DispReq DSCDS_DispSz DSCDS_CshLgAdjFdRr DSCDS_BkCshBlstInOt DSCDS_CshBlstrInOut DSCDS_BkBlstrInOut DSCDS_LmbrUDnFdRr DSCDS_LmbrFwdRr DSCDS_LmbrUpDwn DSCDS_UprShldrFdRr DSCDS_HdrstTltFwdRr DSCDS_HdrstWngInOt DSCDS_HdrstUDnFdRr DSCDS_HdrstFwdRrwd DSCDS_HdrstUpDn DSCDS_MassgIntsty DSCDS_MassgTyp DSCDS_Massg;
SIG_GROUP_ 2152120320 RRStActPrty 1 : RRSAP_UnsdRsrvd RRSAP_DispSz RRSAP_CshLgthAdjFdRr RRSAP_BkCshBlstrInOut RRSAP_CshBlstrInOut RRSAP_BkBlstrInOut RRSAP_LmbrUpDnFdRr RRSAP_LmbrFwdRr RRSAP_LmbrUpDwn RRSAP_UprShldrFwdRr RRSAP_HdrstTltFwdRr RRSAP_HdrstWngsInOut RRSAP_HdrstUpDnFdRr RRSAP_HdrstFwdRrwd RRSAP_HdrstUpDn RRSAP_Massg;
SIG_GROUP_ 2152103936 LRStCtlDispStat 1 : LRSCDS_UnsdRsrvd LRSCDS_DispReq LRSCDS_DispSz LRSCDS_CshLgAdjFdRr LRSCDS_BkCshBlstInOt LRSCDS_CshBlstrInOut LRSCDS_BkBlstrInOut LRSCDS_LmbrUDnFdRr LRSCDS_LmbrFwdRr LRSCDS_LmbrUpDwn LRSCDS_UprShldrFdRr LRSCDS_HdrstTltFwdRr LRSCDS_HdrstWngInOt LRSCDS_HdrstFdRrUDn LRSCDS_HdrstFwdRrwd LRSCDS_HdrstUpDn LRSCDS_MassgIntsty LRSCDS_MassgTyp LRSCDS_Massg;
SIG_GROUP_ 2152087552 LRStMassgPrty 1 : LRSMP_UnsdRsrvd LRSMP_MaxDispVal LRSMP_Type15 LRSMP_Type14 LRSMP_Type13 LRSMP_Type12 LRSMP_Type11 LRSMP_Type10 LRSMP_Type9 LRSMP_Type8 LRSMP_Type7 LRSMP_Type6 LRSMP_Type5 LRSMP_Type4 LRSMP_Type3 LRSMP_Type2 LRSMP_Type1;
SIG_GROUP_ 2152071168 LRStActPrty 1 : LRSAP_UnsdRsrvd LRSAP_DispSz LRSAP_CshLgthAdjFdRr LRSAP_BkCshBlstrInOut LRSAP_CshBlstrInOut LRSAP_BkBlstrInOut LRSAP_LmbrUpDnFdRr LRSAP_LmbrFwdRr LRSAP_LmbrUpDwn LRSAP_UprShldrFwdRr LRSAP_HdrstTltFwdRr LRSAP_HdrstWngsInOut LRSAP_HdrstUpDnFdRr LRSAP_HdrstFwdRrwd LRSAP_HdrstUpDn LRSAP_Massg;
SIG_GROUP_ 2149924864 ECODrvAsstDsplyStat 1 : EDADS_RcmndtFwdGr EDADS_CrntFwdMsdG EDADS_ShftIndStat EDADS_EcoDrvShftIO;
SIG_GROUP_ 2149924864 DrvSelMdSelnStat 1 : DSMSS_DrvSelMd0Pn DSMSS_DrvSelMd8Pn DSMSS_DrvSelMd7Pn DSMSS_DrvSelMd6Pn DSMSS_DrvSelMd5Pn DSMSS_DrvSelMd4Pn DSMSS_DrvSelMd3Pn DSMSS_DrvSelMd2Pn DSMSS_DrvSelMd1Pn DSMSS_DrvSelMd8Un DSMSS_DrvSelMd7Un DSMSS_DrvSelMd6Un DSMSS_DrvSelMd5Un DSMSS_DrvSelMd4Un DSMSS_DrvSelMd3Un DSMSS_DrvSelMd2Un DSMSS_DrvSelMd1Un;
SIG_GROUP_ 2149924864 ColPrepSysCustAvail 1 : CPSCA_Resrv3Avail CPSCA_Resrv2Avail CPSCA_Resrv1Avail CPSCA_AlrtBrkStrAvail CPSCA_AlrtBrkAvail CPSCA_AlrtAvail CPSCA_OffAvail;
SIG_GROUP_ 2151530496 HVBatTmBsDlChStRqRmt1 1 : HVBTBDCSRR1_DChMHSRq HVBTBDCSRR1_DChSnSRq HVBTBDCSRR1_DChSlSRq HVBTBDCSRR1_DChDStRq HVBTBDCSRR1_DChHStRq;
